VERSION ""

NS_ :

BS_:

BU_: AHLM ASBS CBC DIAGNOST DPDM DTCM ECM EHPS ESC ESL ESM ETM GPF HCP IC IRCM OCM ORC PTS RF_HUB SCCM SGW TBM TCM TPM

BO_ 1562 SD_RS_EPS: 8 EHPS
 SG_ SD_RS_EPS : 7|64@0+ (1,0) [0|0] ""  ETM,SGW,TBM

BO_ 1543 SD_RS_ESC: 8 ESC
 SG_ SD_RS_ESC : 7|64@0+ (1,0) [0|0] ""  ETM,SGW,TBM

BO_ 1544 SD_RS_ESL: 8 ESL
 SG_ SD_RS_ESL : 7|64@0+ (1,0) [0|0] ""  ETM,SGW,TBM

BO_ 1545 SD_RS_ESM: 8 ESM
 SG_ SD_RS_ESM : 7|64@0+ (1,0) [0|0] ""  ETM,SGW,TBM

BO_ 1586 SD_RS_GPF: 8 GPF
 SG_ SD_RS_GPF : 7|64@0+ (1,0) [0|0] ""  ETM,SGW,TBM

BO_ 1594 SD_RS_HCP: 8 HCP
 SG_ SD_RS_HCP : 7|64@0+ (1,0) [0|0] ""  ETM,SGW,TBM

BO_ 1538 SD_RS_IC: 8 IC
 SG_ SD_RS_IC : 7|64@0+ (1,0) [0|0] ""  ETM,SGW,TBM

BO_ 1566 SD_RS_OCM: 8 OCM
 SG_ SD_RS_OCM : 7|64@0+ (1,0) [0|0] ""  ETM,SGW,TBM

BO_ 1540 SD_RS_ORC: 8 ORC
 SG_ SD_RS_ORC : 7|64@0+ (1,0) [0|0] ""  ETM,SGW,TBM

BO_ 1570 SD_RS_PTS: 8 PTS
 SG_ SD_RS_PTS : 7|64@0+ (1,0) [0|0] ""  ETM,SGW,TBM

BO_ 1536 SD_RS_RF_HUB: 8 RF_HUB
 SG_ SD_RS_RF_HUB : 7|64@0+ (1,0) [0|0] ""  ETM,SGW,TBM

BO_ 1571 SD_RS_SCCM: 8 SCCM
 SG_ SD_RS_SCCM : 7|64@0+ (1,0) [0|0] ""  ETM,SGW,TBM

BO_ 1643 SD_RS_TBM: 8 SGW
 SG_ SD_RS_TBM : 7|64@0+ (1,0) [0|0] "" Vector__XXX

BO_ 1593 SD_RS_TCM: 8 TCM
 SG_ SD_RS_TCM : 7|64@0+ (1,0) [0|0] ""  ETM,SGW,TBM

BO_ 1539 SD_RS_TPM: 8 TPM
 SG_ SD_RS_TPM : 7|64@0+ (1,0) [0|0] ""  ETM,SGW,TBM

BO_ 423 STATUS_C_ESL: 2 ESL
 SG_ ESLSts : 12|3@1+ (1,0) [0|0] ""  SGW
 SG_ KeyOffWithHighSpeedSts : 15|1@1+ (1,0) [0|0] ""  CBC,SGW

BO_ 491 STATUS_C_PTS: 8 PTS
 SG_ PTS_DBD : 16|1@1+ (1,0) [0|0] ""  IC,SGW

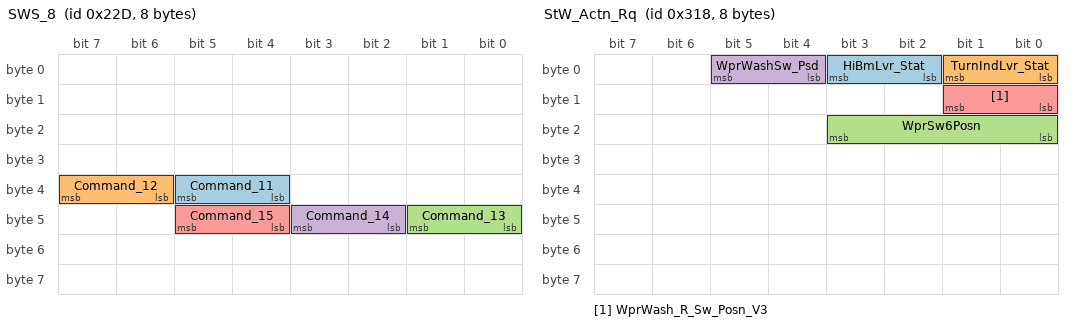
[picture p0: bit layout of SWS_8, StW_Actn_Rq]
BO_ 557 SWS_8: 8 CBC
 SG_ Command_11 : 36|2@1+ (1,0) [0|0] ""  ETM,IC,SGW,TBM
 SG_ Command_12 : 38|2@1+ (1,0) [0|0] ""  ETM,IC,SGW,TBM
 SG_ Command_13 : 40|2@1+ (1,0) [0|0] ""  ETM,IC,SGW,TBM
 SG_ Command_14 : 42|2@1+ (1,0) [0|0] ""  ETM,IC,SGW,TBM
 SG_ Command_15 : 44|2@1+ (1,0) [0|0] ""  ETM,IC,SGW,TBM

BO_ 792 StW_Actn_Rq: 8 SCCM
 SG_ HiBmLvr_Stat : 2|2@1+ (1,0) [0|0] ""  CBC,ETM,SGW,TBM
 SG_ TurnIndLvr_Stat : 0|2@1+ (1,0) [0|0] ""  CBC,IRCM,SGW
 SG_ WprSw6Posn : 16|4@1+ (1,0) [0|0] ""  CBC,ETM,IRCM,SGW,TBM
 SG_ WprWashSw_Psd : 4|2@1+ (1,0) [0|0] ""  CBC,ETM,SGW,TBM
 SG_ WprWash_R_Sw_Posn_V3 : 8|2@1+ (1,0) [0|0] ""  CBC,ECM,ETM,SGW,TBM

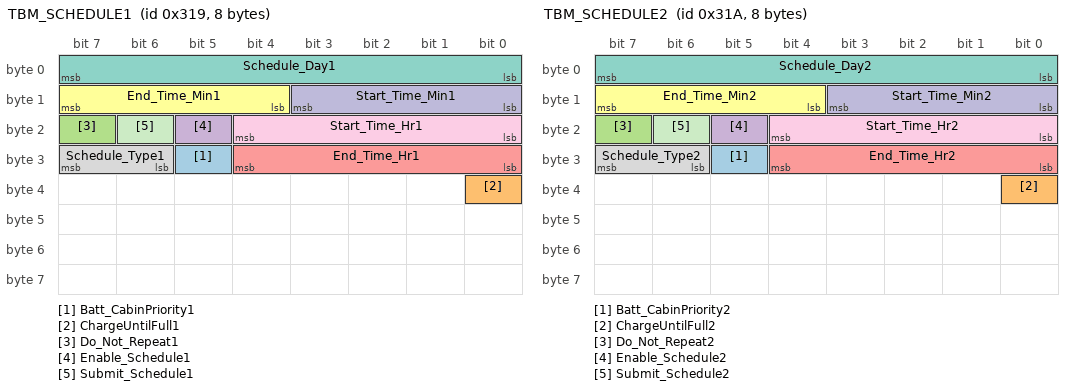
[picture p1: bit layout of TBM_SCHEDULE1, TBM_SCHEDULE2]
BO_ 793 TBM_SCHEDULE1: 8 CBC
 SG_ Batt_CabinPriority1 : 29|1@1+ (1,0) [0|0] ""  HCP,SGW
 SG_ ChargeUntilFull1 : 32|1@1+ (1,0) [0|0] ""  HCP,SGW
 SG_ Do_Not_Repeat1 : 23|1@1+ (1,0) [0|0] ""  HCP,SGW
 SG_ Enable_Schedule1 : 21|1@1+ (1,0) [0|0] ""  HCP,SGW
 SG_ End_Time_Hr1 : 24|5@1+ (1,0) [0|23] "Hours"  HCP,SGW
 SG_ End_Time_Min1 : 12|4@1+ (5,0) [0|55] "min"  HCP,SGW
 SG_ Schedule_Day1 : 0|8@1+ (1,0) [0|0] ""  HCP,SGW
 SG_ Schedule_Type1 : 30|2@1+ (1,0) [0|0] ""  HCP,SGW
 SG_ Start_Time_Hr1 : 16|5@1+ (1,0) [0|23] "Hours"  HCP,SGW
 SG_ Start_Time_Min1 : 8|4@1+ (5,0) [0|55] "min"  HCP,SGW
 SG_ Submit_Schedule1 : 22|1@1+ (1,0) [0|0] ""  HCP,SGW

BO_ 794 TBM_SCHEDULE2: 8 CBC
 SG_ Batt_CabinPriority2 : 29|1@1+ (1,0) [0|0] ""  HCP,SGW
 SG_ ChargeUntilFull2 : 32|1@1+ (1,0) [0|0] ""  HCP,SGW
 SG_ Do_Not_Repeat2 : 23|1@1+ (1,0) [0|0] ""  HCP,SGW
 SG_ Enable_Schedule2 : 21|1@1+ (1,0) [0|0] ""  HCP,SGW
 SG_ End_Time_Hr2 : 24|5@1+ (1,0) [0|23] "Hours"  HCP,SGW
 SG_ End_Time_Min2 : 12|4@1+ (5,0) [0|55] "min"  HCP,SGW
 SG_ Schedule_Day2 : 0|8@1+ (1,0) [0|0] ""  HCP,SGW
 SG_ Schedule_Type2 : 30|2@1+ (1,0) [0|0] ""  HCP,SGW
 SG_ Start_Time_Hr2 : 16|5@1+ (1,0) [0|23] "Hours"  HCP,SGW
 SG_ Start_Time_Min2 : 8|4@1+ (5,0) [0|55] "min"  HCP,SGW
 SG_ Submit_Schedule2 : 22|1@1+ (1,0) [0|0] ""  HCP,SGW

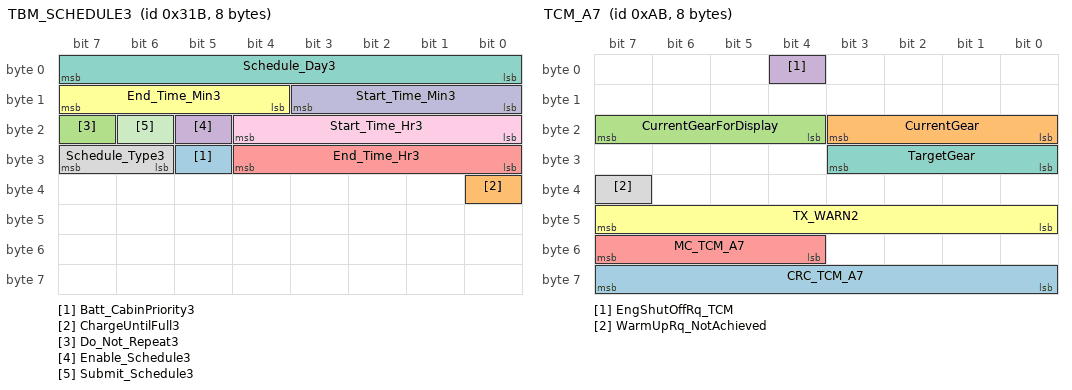
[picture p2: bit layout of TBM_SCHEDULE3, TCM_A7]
BO_ 795 TBM_SCHEDULE3: 8 CBC
 SG_ Batt_CabinPriority3 : 29|1@1+ (1,0) [0|0] ""  HCP,SGW
 SG_ ChargeUntilFull3 : 32|1@1+ (1,0) [0|0] ""  HCP,SGW
 SG_ Do_Not_Repeat3 : 23|1@1+ (1,0) [0|0] ""  HCP,SGW
 SG_ Enable_Schedule3 : 21|1@1+ (1,0) [0|0] ""  HCP,SGW
 SG_ End_Time_Hr3 : 24|5@1+ (1,0) [0|23] "Hours"  HCP,SGW
 SG_ End_Time_Min3 : 12|4@1+ (5,0) [0|55] "min"  HCP,SGW
 SG_ Schedule_Day3 : 0|8@1+ (1,0) [0|0] ""  HCP,SGW
 SG_ Schedule_Type3 : 30|2@1+ (1,0) [0|0] ""  HCP,SGW
 SG_ Start_Time_Hr3 : 16|5@1+ (1,0) [0|23] "Hours"  HCP,SGW
 SG_ Start_Time_Min3 : 8|4@1+ (5,0) [0|55] "min"  HCP,SGW
 SG_ Submit_Schedule3 : 22|1@1+ (1,0) [0|0] ""  HCP,SGW

BO_ 171 TCM_A7: 8 TCM
 SG_ CRC_TCM_A7 : 56|8@1+ (1,0) [0|0] ""  ECM,HCP,IRCM,SGW
 SG_ CurrentGear : 16|4@1+ (1,0) [0|0] ""  ECM,ETM,HCP,IRCM,SGW,TBM
 SG_ CurrentGearForDisplay : 20|4@1+ (1,0) [0|0] ""  ETM,IC,SGW
 SG_ EngShutOffRq_TCM : 4|1@1+ (1,0) [0|0] ""  ECM,SGW
 SG_ MC_TCM_A7 : 52|4@1+ (1,0) [0|15] ""  ECM,HCP,IRCM,SGW
 SG_ TX_WARN2 : 40|8@1+ (1,0) [0|0] ""  ETM,IC,SGW,TBM
 SG_ TargetGear : 24|4@1+ (1,0) [0|0] ""  ECM,HCP,IRCM,SGW
 SG_ WarmUpRq_NotAchieved : 39|1@1+ (1,0) [0|0] ""  ECM,SGW

BO_ 945 TCM_APPL1: 8 TCM
 SG_ TCM_APPL1 : 7|64@0+ (1,0) [0|0] ""  DIAGNOST,SGW

BO_ 944 TCM_APPL2: 8 DIAGNOST
 SG_ TCM_APPL2 : 7|64@0+ (1,0) [0|0] ""  TCM

BO_ 946 TCM_APPL3: 8 TCM
 SG_ TCM_APPL3 : 7|64@0+ (1,0) [0|0] ""  DIAGNOST,SGW

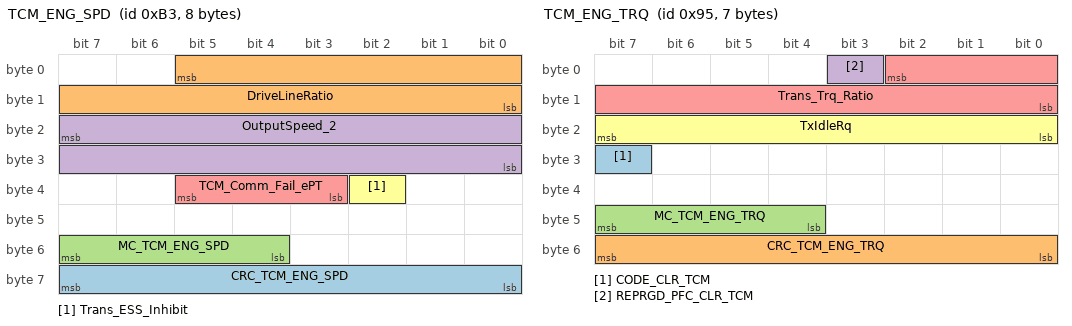
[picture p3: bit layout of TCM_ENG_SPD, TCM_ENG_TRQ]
BO_ 179 TCM_ENG_SPD: 8 TCM
 SG_ CRC_TCM_ENG_SPD : 56|8@1+ (1,0) [0|0] ""  ECM,ESC,HCP,IRCM,SGW
 SG_ DriveLineRatio : 5|14@0+ (0.01,0) [0|163.82] ""  ECM,HCP,IRCM,SGW
 SG_ MC_TCM_ENG_SPD : 52|4@1+ (1,0) [0|15] ""  ECM,ESC,HCP,IRCM,SGW
 SG_ OutputSpeed_2 : 23|16@0+ (1,0) [0|65534] "rpm"  ECM,HCP,SGW
 SG_ TCM_Comm_Fail_ePT : 35|3@1+ (1,0) [0|0] ""  ECM,HCP,SGW
 SG_ Trans_ESS_Inhibit : 34|1@1+ (1,0) [0|0] ""  ECM,SGW

BO_ 149 TCM_ENG_TRQ: 7 TCM
 SG_ CODE_CLR_TCM : 31|1@1+ (1,0) [0|0] ""  ECM,SGW
 SG_ CRC_TCM_ENG_TRQ : 48|8@1+ (1,0) [0|0] ""  DTCM,ECM,ESC,HCP,IRCM,SGW
 SG_ MC_TCM_ENG_TRQ : 44|4@1+ (1,0) [0|15] ""  DTCM,ECM,ESC,HCP,IRCM,SGW
 SG_ REPRGD_PFC_CLR_TCM : 3|1@1+ (1,0) [0|0] ""  ECM,SGW
 SG_ Trans_Trq_Ratio : 2|11@0+ (0.01,0) [0|20.46] ""  DTCM,ECM,ESC,ETM,HCP,IRCM,SGW,TBM
 SG_ TxIdleRq : 16|8@1+ (4,500) [500|1516] "rpm"  ECM,ESC,SGW

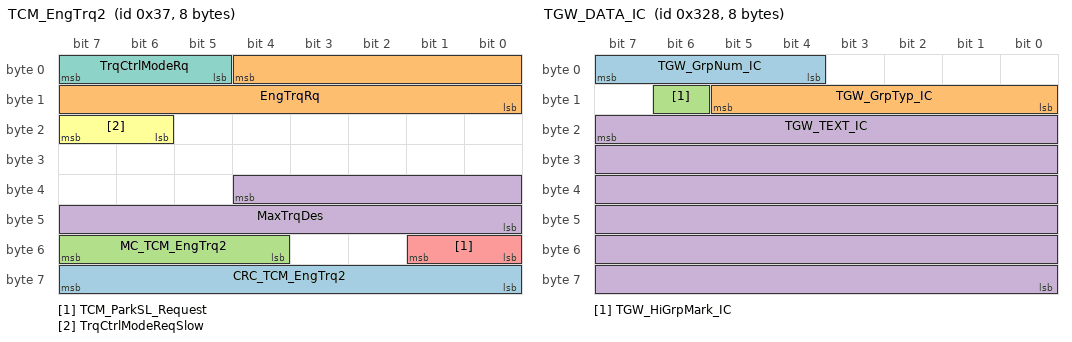
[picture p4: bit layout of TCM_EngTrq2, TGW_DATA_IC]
BO_ 55 TCM_EngTrq2: 8 TCM
 SG_ CRC_TCM_EngTrq2 : 56|8@1+ (1,0) [0|0] ""  ECM,ESC,HCP,IRCM,SGW
 SG_ EngTrqRq : 4|13@0+ (0.25,-500) [-500|1547.5] "Nm"  ECM,ESC,HCP,SGW
 SG_ MC_TCM_EngTrq2 : 52|4@1+ (1,0) [0|15] ""  ECM,ESC,HCP,IRCM,SGW
 SG_ MaxTrqDes : 36|13@0+ (0.25,-500) [-500|1547.5] "Nm"  ECM,HCP,SGW
 SG_ TCM_ParkSL_Request : 48|2@1+ (1,0) [0|0] ""  ECM,SGW
 SG_ TrqCtrlModeReqSlow : 22|2@1+ (1,0) [0|0] ""  HCP,SGW
 SG_ TrqCtrlModeRq : 5|3@1+ (1,0) [0|0] ""  ECM,ESC,HCP,SGW

BO_ 872 TCM_HSA: 8 TCM
 SG_ TCM_HSA : 7|64@0+ (1,0) [0|0] ""  DIAGNOST,SGW

BO_ 888 TCM_HSB: 8 TCM
 SG_ TCM_HSB : 7|64@0+ (1,0) [0|0] ""  DIAGNOST,SGW

BO_ 904 TCM_HSC: 8 TCM
 SG_ TCM_HSC : 7|64@0+ (1,0) [0|0] ""  DIAGNOST,SGW

BO_ 920 TCM_HSD: 8 TCM
 SG_ TCM_HSD : 7|64@0+ (1,0) [0|0] ""  DIAGNOST,SGW

BO_ 808 TGW_DATA_IC: 8 CBC
 SG_ TGW_GrpNum_IC : 4|4@1+ (1,1) [1|16] "Group"  IC,SGW
 SG_ TGW_GrpTyp_IC : 8|6@1+ (1,0) [1|40] "Text"  IC,SGW
 SG_ TGW_HiGrpMark_IC : 14|1@1+ (1,0) [0|0] ""  IC,SGW
 SG_ TGW_TEXT_IC : 23|48@0+ (1,0) [0|0] ""  IC,SGW

BO_ 662 TPM_A1: 8 TPM
 SG_ STFASysEnableFault : 23|1@1+ (1,0) [0|0] ""  CBC,SGW
 SG_ TFASts_TPM : 22|1@1+ (1,0) [0|0] ""  CBC,SGW
 SG_ TPM_Chime_Rq : 2|1@1+ (1,0) [0|0] ""  IC,SGW
 SG_ TPM_HazardFlash : 21|1@1+ (1,0) [0|0] ""  CBC,IC,SGW
 SG_ TPM_HornChirp : 19|2@1+ (1,0) [0|0] ""  SGW
 SG_ TPM_IndLmp_On_Rq : 0|2@1+ (1,0) [0|0] ""  ETM,IC,ORC,SGW,TBM
 SG_ TPM_Sys_Stat : 5|3@1+ (1,0) [0|0] ""  IC,SGW
 SG_ TireFL : 8|2@1+ (1,0) [0|0] ""  ETM,IC,ORC,SGW,TBM
 SG_ TireFR : 10|2@1+ (1,0) [0|0] ""  ETM,IC,ORC,SGW,TBM
 SG_ TirePressFL : 24|8@1+ (1,0) [0|126] "psi"  ETM,IC,ORC,SGW,TBM
 SG_ TirePressFR : 32|8@1+ (1,0) [0|126] "psi"  ETM,IC,ORC,SGW,TBM
 SG_ TirePressRL : 40|8@1+ (1,0) [0|126] "psi"  ETM,IC,ORC,SGW,TBM
 SG_ TirePressRR : 48|8@1+ (1,0) [0|126] "psi"  ETM,IC,ORC,SGW,TBM
 SG_ TirePressSpr : 56|8@1+ (1,0) [0|126] "psi"  ETM,IC,ORC,SGW,TBM
 SG_ TireRL : 14|2@1+ (1,0) [0|0] ""  ETM,IC,ORC,SGW,TBM
 SG_ TireRR : 12|2@1+ (1,0) [0|0] ""  ETM,IC,ORC,SGW,TBM
 SG_ TireSpr : 16|2@1+ (1,0) [0|0] ""  ETM,IC,ORC,SGW,TBM

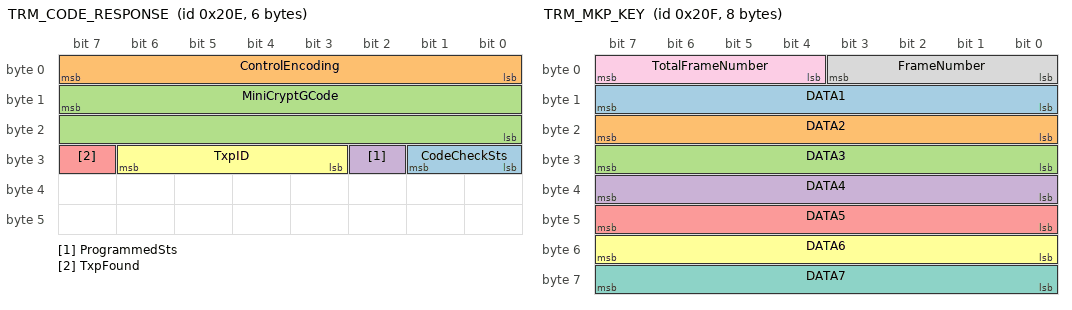
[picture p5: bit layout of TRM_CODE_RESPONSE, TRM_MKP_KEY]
BO_ 526 TRM_CODE_RESPONSE: 6 RF_HUB
 SG_ CodeCheckSts : 24|2@1+ (1,0) [0|0] ""  CBC,SGW
 SG_ ControlEncoding : 0|8@1+ (1,0) [0|0] ""  CBC,SGW
 SG_ MiniCryptGCode : 15|16@0+ (1,0) [0|0] ""  CBC,SGW
 SG_ ProgrammedSts : 26|1@1+ (1,0) [0|0] ""  CBC,SGW
 SG_ TxpFound : 31|1@1+ (1,0) [0|0] ""  CBC,SGW
 SG_ TxpID : 27|4@1+ (1,0) [0|0] ""  CBC,SGW

BO_ 527 TRM_MKP_KEY: 8 RF_HUB
 SG_ DATA1 : 8|8@1+ (1,0) [0|0] ""  CBC,SGW
 SG_ DATA2 : 16|8@1+ (1,0) [0|0] ""  CBC,SGW
 SG_ DATA3 : 24|8@1+ (1,0) [0|0] ""  CBC,SGW
 SG_ DATA4 : 32|8@1+ (1,0) [0|0] ""  CBC,SGW
 SG_ DATA5 : 40|8@1+ (1,0) [0|0] ""  CBC,SGW
 SG_ DATA6 : 48|8@1+ (1,0) [0|0] ""  CBC,SGW
 SG_ DATA7 : 56|8@1+ (1,0) [0|0] ""  CBC,SGW
 SG_ FrameNumber : 0|4@1+ (1,0) [0|0] ""  CBC,SGW
 SG_ TotalFrameNumber : 4|4@1+ (1,0) [0|0] ""  CBC,SGW

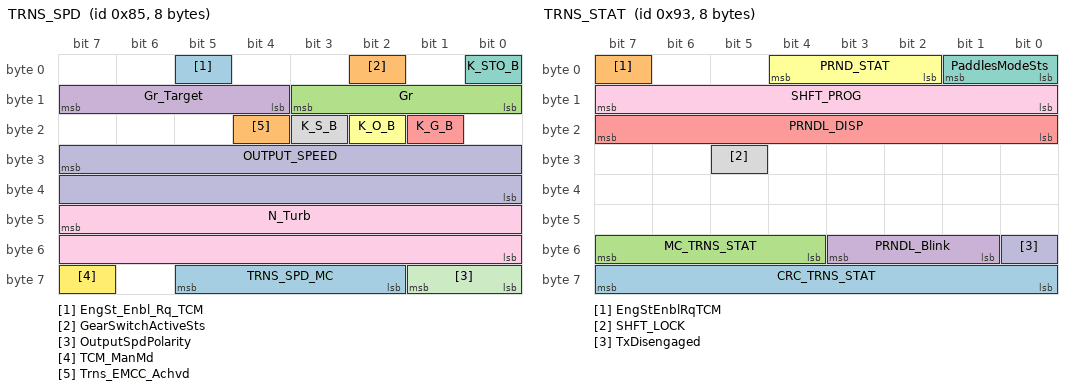
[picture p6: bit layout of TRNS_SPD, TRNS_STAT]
BO_ 133 TRNS_SPD: 8 TCM
 SG_ EngSt_Enbl_Rq_TCM : 5|1@1+ (1,0) [0|0] ""  ETM,RF_HUB,SGW,TBM
 SG_ GearSwitchActiveSts : 2|1@1+ (1,0) [0|0] ""  ECM,ESC,ETM,HCP,SGW,TBM
 SG_ Gr : 8|4@1+ (1,0) [0|0] ""  CBC,DTCM,ECM,ESC,ETM,HCP,IC,ORC,RF_HUB,SGW,TBM,TPM
 SG_ Gr_Target : 12|4@1+ (1,0) [0|0] ""  CBC,DTCM,ECM,ESC,HCP,SGW
 SG_ K_G_B : 17|1@1+ (1,0) [0|0] ""  ECM,ESC,ETM,HCP,SGW,TBM
 SG_ K_O_B : 18|1@1+ (1,0) [0|0] ""  ECM,ESC,ETM,HCP,SGW,TBM
 SG_ K_STO_B : 0|1@1+ (1,0) [0|0] ""  ECM,ETM,HCP,SGW,TBM
 SG_ K_S_B : 19|1@1+ (1,0) [0|0] ""  ECM,ESC,ETM,HCP,SGW,TBM
 SG_ N_Turb : 47|16@0+ (1,0) [0|65534] "rpm"  ECM,ETM,HCP,SGW,TBM
 SG_ OUTPUT_SPEED : 31|16@0+ (1,0) [0|65534] "rpm"  DTCM,ECM,ESC,ETM,HCP,SGW,TBM
 SG_ OutputSpdPolarity : 56|2@1+ (1,0) [0|0] ""  ESC,ETM,HCP,SGW,TBM
 SG_ TCM_ManMd : 63|1@1+ (1,0) [0|0] ""  DTCM,ECM,ETM,HCP,IC,SGW
 SG_ TRNS_SPD_MC : 58|4@1+ (1,0) [0|15] ""  ECM,ESC,ETM,HCP,SGW,TBM
 SG_ Trns_EMCC_Achvd : 20|1@1+ (1,0) [0|0] ""  ECM,ETM,SGW,TBM

BO_ 147 TRNS_STAT: 8 TCM
 SG_ CRC_TRNS_STAT : 56|8@1+ (1,0) [0|0] ""  DTCM,ECM,ESC,ESM,HCP,IRCM,PTS,SGW
 SG_ EngStEnblRqTCM : 7|1@1+ (1,0) [0|0] ""  ECM,RF_HUB,SGW
 SG_ MC_TRNS_STAT : 52|4@1+ (1,0) [0|15] ""  DTCM,ECM,ESC,ESM,HCP,IRCM,PTS,SGW
 SG_ PRNDL_Blink : 49|3@1+ (1,0) [0|0] ""  ESM,IC,SGW
 SG_ PRNDL_DISP : 16|8@1+ (1,0) [0|0] ""  CBC,DTCM,ECM,ESC,ESM,HCP,IC,IRCM,ORC,SGW
 SG_ PRND_STAT : 2|3@1+ (1,0) [0|0] ""  CBC,ECM,ESC,ESM,HCP,IC,IRCM,ORC,PTS,SGW
 SG_ PaddlesModeSts : 0|2@1+ (1,0) [0|0] ""  SGW
 SG_ SHFT_LOCK : 29|1@1+ (1,0) [0|0] ""  ESM,SGW
 SG_ SHFT_PROG : 8|8@1+ (1,0) [0|0] ""  CBC,DTCM,ECM,ESC,HCP,IC,SGW
 SG_ TxDisengaged : 48|1@1+ (1,0) [0|0] ""  ECM,HCP,SGW

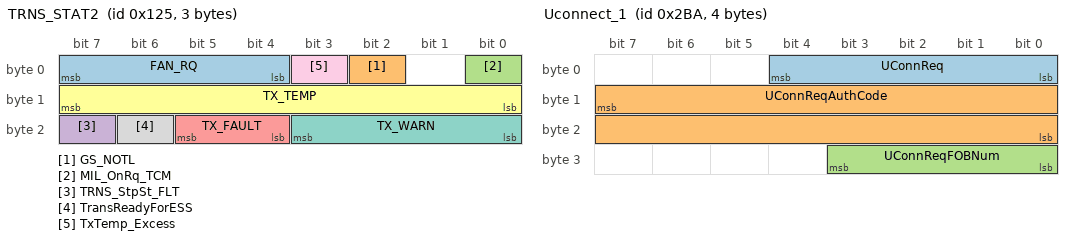
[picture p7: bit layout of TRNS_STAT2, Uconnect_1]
BO_ 293 TRNS_STAT2: 3 TCM
 SG_ FAN_RQ : 4|4@1+ (7.2,0) [0|100] "%"  ECM,SGW
 SG_ GS_NOTL : 2|1@1+ (1,0) [0|0] ""  ECM,HCP,IRCM,ORC,SGW
 SG_ MIL_OnRq_TCM : 0|1@1+ (1,0) [0|0] ""  ECM,ETM,SGW,TBM
 SG_ TRNS_StpSt_FLT : 23|1@1+ (1,0) [0|0] ""  ECM,SGW
 SG_ TX_FAULT : 20|2@1+ (1,0) [0|0] ""  ECM,ESM,ETM,RF_HUB,SGW,TBM
 SG_ TX_TEMP : 8|8@1+ (1,-50) [-50|204] "°C"  CBC,DTCM,ECM,ETM,HCP,IC,SGW,TBM
 SG_ TX_WARN : 16|4@1+ (1,0) [0|0] ""  IC,SGW
 SG_ TransReadyForESS : 22|1@1+ (1,0) [0|0] ""  ECM,ORC,SGW
 SG_ TxTemp_Excess : 3|1@1+ (1,0) [0|0] ""  ETM,IC,SGW,TBM

BO_ 698 Uconnect_1: 4 ETM
 SG_ UConnReq : 0|5@1+ (1,0) [0|0] ""  RF_HUB
 SG_ UConnReqAuthCode : 15|16@0+ (1,0) [0|0] ""  RF_HUB
 SG_ UConnReqFOBNum : 24|4@1+ (1,0) [0|0] ""  RF_HUB

BO_ 992 VIN: 8 ECM
 SG_ VIN_DATA : 15|56@0+ (1,0) [0|0] ""  AHLM,ASBS,CBC,DPDM,DTCM,EHPS,ESC,ESL,ESM,ETM,GPF,HCP,IC,IRCM,OCM,ORC,PTS,RF_HUB,SCCM,SGW,TBM,TCM,TPM
 SG_ VIN_MSG : 0|2@1+ (1,0) [0|0] ""  AHLM,ASBS,CBC,DPDM,DTCM,EHPS,ESC,ESL,ESM,ETM,GPF,HCP,IC,IRCM,OCM,ORC,PTS,RF_HUB,SCCM,SGW,TBM,TCM,TPM

BO_ 1000 VehCfg1: 8 CBC
 SG_ VC_AUTO_HB : 27|1@1+ (1,0) [0|0] ""  IC,IRCM,RF_HUB,SGW
 SG_ VC_BODY_STYLE : 28|4@1+ (1,0) [0|0] ""  AHLM,ASBS,DPDM,DTCM,ECM,EHPS,ESC,ESL,ESM,GPF,HCP,IC,IRCM,OCM,ORC,PTS,RF_HUB,SCCM,SGW,TCM,TPM
 SG_ VC_CHMCM_Prsnt : 61|1@1+ (1,0) [0|0] ""  RF_HUB,SGW
 SG_ VC_COUNTRY : 16|5@1+ (1,0) [0|0] ""  AHLM,ASBS,DPDM,DTCM,ECM,EHPS,ESC,ESL,ESM,ETM,GPF,HCP,IC,IRCM,OCM,ORC,PTS,RF_HUB,SCCM,SGW,TBM,TCM,TPM
 SG_ VC_EmodePrsnt : 26|1@1+ (1,0) [0|0] ""  RF_HUB,SGW
 SG_ VC_HDC_Prsnt : 62|1@1+ (1,0) [0|0] ""  ECM,ESC,IC,IRCM,RF_HUB,SGW,TCM
 SG_ VC_HdRstPrsnt : 56|1@1+ (1,0) [0|0] ""  RF_HUB,SGW
 SG_ VC_LHD_RHD : 21|2@1+ (1,0) [0|0] ""  DTCM,ESC,ETM,IC,IRCM,RF_HUB,SGW,TBM
 SG_ VC_MAX_VEH_SPD : 32|8@1+ (2,0) [0|506] "kph"  RF_HUB,SGW
 SG_ VC_MODEL_YEAR : 2|6@1+ (1,2000) [2000|2062] "model-year"  AHLM,ASBS,DPDM,DTCM,ECM,EHPS,ESC,ESL,ESM,ETM,GPF,HCP,IC,IRCM,OCM,ORC,PTS,RF_HUB,SCCM,SGW,TBM,TCM,TPM
 SG_ VC_PP_Prsnt : 47|1@1+ (1,0) [0|0] ""  RF_HUB,SGW
 SG_ VC_PTS_Config : 58|2@1+ (1,0) [0|0] ""  IC,RF_HUB,SGW
 SG_ VC_PTS_DispTyp : 44|3@1+ (1,0) [0|0] ""  RF_HUB,SGW
 SG_ VC_RVCM_Prsnt : 60|1@1+ (1,0) [0|0] ""  RF_HUB,SGW
 SG_ VC_RemStPrsnt : 23|1@1+ (1,0) [0|0] ""  IC,ORC,RF_HUB,SGW,TCM,TPM
 SG_ VC_SCR_Prsnt : 57|1@1+ (1,0) [0|0] ""  ECM,IC,RF_HUB,SGW
 SG_ VC_SSC_Prsnt : 63|1@1+ (1,0) [0|0] ""  DTCM,ECM,ESC,IC,RF_HUB,SGW,TCM
 SG_ VC_ShftrTyp : 40|4@1+ (1,0) [0|0] ""  IC,RF_HUB,SGW,TCM
 SG_ VC_SpecialPKG : 48|8@1+ (1,0) [1|254] ""  RF_HUB,SGW
 SG_ VC_VEH_LINE : 8|8@1+ (1,0) [0|0] ""  AHLM,ASBS,DPDM,DTCM,ECM,EHPS,ESC,ESL,ESM,ETM,GPF,HCP,IC,IRCM,OCM,ORC,PTS,RF_HUB,SCCM,SGW,TBM,TCM,TPM
 SG_ VC_VehCfg1_Stat : 0|2@1+ (1,0) [0|0] ""  AHLM,ASBS,DPDM,DTCM,ECM,EHPS,ESC,ESL,ESM,GPF,HCP,IC,IRCM,OCM,ORC,PTS,RF_HUB,SCCM,SGW,TCM,TPM
 SG_ VC_XWD : 24|2@1+ (1,0) [0|0] ""  DTCM,ECM,EHPS,ESC,HCP,IRCM,RF_HUB,SGW,TCM

BO_ 1001 VehCfg2: 8 CBC
 SG_ VC_AC_Prsnt : 11|1@1+ (1,0) [0|0] ""  RF_HUB,SGW
 SG_ VC_CRUISE_PRSNT : 12|1@1+ (1,0) [0|0] ""  ECM,IC,IRCM,ORC,RF_HUB,SCCM,SGW,TCM
 SG_ VC_DRVMD_Prsnt : 25|1@1+ (1,0) [0|0] ""  RF_HUB,SGW
 SG_ VC_ECO_Indicator : 24|1@1+ (1,0) [0|0] ""  RF_HUB,SGW
 SG_ VC_ESCDrvMd_Prsnt : 27|1@1+ (1,0) [0|0] ""  RF_HUB,SGW
 SG_ VC_EngPowerDrvMd_Prsnt : 28|1@1+ (1,0) [0|0] ""  RF_HUB,SGW
 SG_ VC_FG_PRSNT : 13|1@1+ (1,0) [0|0] ""  RF_HUB,SGW
 SG_ VC_FULL_SPARE : 14|1@1+ (1,0) [0|0] ""  RF_HUB,SGW,TPM
 SG_ VC_LgtLdPressFtTr : 56|8@1+ (1,0) [0|126] "psi"  RF_HUB,SGW
 SG_ VC_LgtLdPressRrTr : 48|8@1+ (1,0) [0|126] "psi"  RF_HUB,SGW
 SG_ VC_MaseratiMd : 6|2@1+ (1,0) [0|0] ""  RF_HUB,SGW
 SG_ VC_MaxLdPressFtTr : 40|8@1+ (1,0) [0|126] "psi"  IC,RF_HUB,SGW,TPM
 SG_ VC_MaxLdPressRrTr : 32|8@1+ (1,0) [0|126] "psi"  IC,RF_HUB,SGW,TPM
 SG_ VC_MemoryDRVMD_Prsnt : 26|1@1+ (1,0) [0|0] ""  RF_HUB,SGW
 SG_ VC_OffRoad : 15|1@1+ (1,0) [0|0] ""  RF_HUB,SGW
 SG_ VC_PADS_Prsnt : 8|1@1+ (1,0) [0|0] ""  IC,ORC,RF_HUB,SGW
 SG_ VC_PwrIvtrTyp : 2|2@1+ (1,0) [0|0] ""  RF_HUB,SGW
 SG_ VC_RainSnsPrsnt : 9|1@1+ (1,0) [0|0] ""  RF_HUB,SGW
 SG_ VC_RunFlatTirePrsnt : 5|1@1+ (1,0) [0|0] ""  RF_HUB,SGW
 SG_ VC_SKIM_PRSNT : 10|1@1+ (1,0) [0|0] ""  RF_HUB,SGW
 SG_ VC_SecPrkPrsnt : 29|1@1+ (1,0) [0|0] ""  RF_HUB,SGW
 SG_ VC_ShftInd_Prsnt : 30|2@1+ (1,0) [0|0] ""  ECM,HCP,IC,RF_HUB,SGW
 SG_ VC_SpecialPKG_IC : 16|8@1+ (1,0) [0|0] ""  IC,IRCM,RF_HUB,SGW
 SG_ VC_ThatchamPrsnt : 4|1@1+ (1,0) [0|0] ""  RF_HUB,SGW
 SG_ VC_VehCfg2_Stat : 0|2@1+ (1,0) [0|0] ""  ECM,ESC,ESM,HCP,IC,IRCM,ORC,RF_HUB,SCCM,SGW,TCM,TPM

BO_TX_BU_ 1643 : SGW,TBM;
BO_TX_BU_ 171 : TCM,ECM;
BO_TX_BU_ 944 : DIAGNOST,SGW;
BO_TX_BU_ 147 : TCM,ECM;
BO_TX_BU_ 698 : ETM,SGW,TBM;
CM_ SG_ 1562 SD_RS_EPS "Response on Event - light";
CM_ SG_ 1543 SD_RS_ESC "Response on Event - light";
CM_ SG_ 1544 SD_RS_ESL "Response on Event - light";
CM_ SG_ 1545 SD_RS_ESM "Response on Event - light";
CM_ SG_ 1586 SD_RS_GPF "Response on Event - light";
CM_ SG_ 1594 SD_RS_HCP "Response on Event - light";
CM_ SG_ 1538 SD_RS_IC "Response on Event - light";
CM_ SG_ 1566 SD_RS_OCM "Response on Event - light";
CM_ SG_ 1540 SD_RS_ORC "Response on Event - light";
CM_ SG_ 1570 SD_RS_PTS "Response on Event - light";
CM_ SG_ 1536 SD_RS_RF_HUB "Response on Event - light";
CM_ SG_ 1571 SD_RS_SCCM "Response on Event - light";
CM_ SG_ 1643 SD_RS_TBM "Response on Event - light";
CM_ SG_ 1593 SD_RS_TCM "Response on Event - light";
CM_ SG_ 1539 SD_RS_TPM "Response on Event - light";
CM_ SG_ 423 ESLSts "ESL lock / unlock status";
CM_ SG_ 423 KeyOffWithHighSpeedSts "Indicates vehicle speed inhibiting lock; Active = [1]";
CM_ SG_ 491 PTS_DBD "Park assist system disabled; System_Disabled = [1]";
CM_ SG_ 557 Command_11 "Steering wheel switch 11";
CM_ SG_ 557 Command_12 "Steering wheel switch 12";
CM_ SG_ 557 Command_13 "Steering wheel switch 13";
CM_ SG_ 557 Command_14 "Steering wheel switch 14";
CM_ SG_ 557 Command_15 "Steering wheel switch 15";
CM_ SG_ 792 HiBmLvr_Stat "High beam lever state";
CM_ SG_ 792 TurnIndLvr_Stat "Turn indicator lever state";
CM_ SG_ 792 WprSw6Posn "Wiper switch (6 stages) position";
CM_ SG_ 792 WprWashSw_Psd "Front wiper switch pressed";
CM_ SG_ 792 WprWash_R_Sw_Posn_V3 "Backlite wiper/washer switch position";
CM_ SG_ 793 Batt_CabinPriority1 "Bit to prioritize battery charging or cabin conditioning under schedule 1";
CM_ SG_ 793 ChargeUntilFull1 "Charge until battery is fully charged with schedule 1";
CM_ SG_ 793 Do_Not_Repeat1 "Do not repeat the set Schedule";
CM_ SG_ 793 Enable_Schedule1 "Schedule 1 checkbox enabled";
CM_ SG_ 793 End_Time_Hr1 "End Time of schedule 1 (hours in 24 hrs. format)";
CM_ SG_ 793 End_Time_Min1 "End Time of schedule 1 (Minutes)";
CM_ SG_ 793 Schedule_Day1 "Schedule#1 Day for charging or cabin conditioning";
CM_ SG_ 793 Schedule_Type1 "Type of charging and climate schedule";
CM_ SG_ 793 Start_Time_Hr1 "Start Time of schedule 1 (hours in 24 hrs. format)";
CM_ SG_ 793 Start_Time_Min1 "Start Time of schedule 1 (minutes)";
CM_ SG_ 793 Submit_Schedule1 "Schedule 1 submitted";
CM_ SG_ 794 Batt_CabinPriority2 "Bit to prioritize battery charging or cabin conditioning under schedule 2";
CM_ SG_ 794 ChargeUntilFull2 "Charge until battery is fully charged with schedule 2";
CM_ SG_ 794 Do_Not_Repeat2 "Do not repeat the set Schedule";
CM_ SG_ 794 Enable_Schedule2 "Schedule 2 checkbox enabled";
CM_ SG_ 794 End_Time_Hr2 "End Time of schedule 2 (hours in 24 hrs. format)";
CM_ SG_ 794 End_Time_Min2 "End Time of schedule 2 (Minutes)";
CM_ SG_ 794 Schedule_Day2 "Schedule#2 Day for charging or cabin conditioning";
CM_ SG_ 794 Schedule_Type2 "Type of charging and climate schedule";
CM_ SG_ 794 Start_Time_Hr2 "Start Time of schedule 2 (hours in 24 hrs. format)";
CM_ SG_ 794 Start_Time_Min2 "Start Time of schedule 2 (minutes)";
CM_ SG_ 794 Submit_Schedule2 "Schedule 2 submitted";
CM_ SG_ 795 Batt_CabinPriority3 "Bit to prioritize battery charging or cabin conditioning under schedule 3";
CM_ SG_ 795 ChargeUntilFull3 "Charge until battery is fully charged with schedule 3";
CM_ SG_ 795 Do_Not_Repeat3 "Do not repeat the set Schedule";
CM_ SG_ 795 Enable_Schedule3 "Schedule 3 checkbox enabled";
CM_ SG_ 795 End_Time_Hr3 "End Time of schedule 3 (hours in 24 hrs. format)";
CM_ SG_ 795 End_Time_Min3 "End Time of schedule 3 (Minutes)";
CM_ SG_ 795 Schedule_Day3 "Schedule#3 Day for charging or cabin conditioning";
CM_ SG_ 795 Schedule_Type3 "Type of charging and climate schedule";
CM_ SG_ 795 Start_Time_Hr3 "Start Time of schedule 3 (hours in 24 hrs. format)";
CM_ SG_ 795 Start_Time_Min3 "Start Time of schedule 3 (minutes)";
CM_ SG_ 795 Submit_Schedule3 "Schedule 3 submitted";
CM_ SG_ 171 CRC_TCM_A7 "CRC-checksum byte 1 to 7 according to SAE J1850";
CM_ SG_ 171 CurrentGear "Current Gear";
CM_ SG_ 171 CurrentGearForDisplay "Current Gear for display";
CM_ SG_ 171 EngShutOffRq_TCM "TCM request engine shut off";
CM_ SG_ 171 MC_TCM_A7 "Message counter";
CM_ SG_ 171 TX_WARN2 "Transmission warning #2";
CM_ SG_ 171 TargetGear "Target Gear - protected";
CM_ SG_ 171 WarmUpRq_NotAchieved "Warm Up Request; 0- Achieved, 1- NOT_Achieved";
CM_ SG_ 945 TCM_APPL1 "CCP from transmission";
CM_ SG_ 944 TCM_APPL2 "CCP to transmission";
CM_ SG_ 946 TCM_APPL3 "CCP from transmission";
CM_ SG_ 179 CRC_TCM_ENG_SPD "CRC-checksum byte 1 to 7 according to SAE J1850";
CM_ SG_ 179 DriveLineRatio "Drive Line Ratio";
CM_ SG_ 179 MC_TCM_ENG_SPD "Message counter   TCM_ENG_SPD";
CM_ SG_ 179 OutputSpeed_2 "Output Shaft Speed from 0 - 65534 RPM with 1 RPM resolution.  ";
CM_ SG_ 179 TCM_Comm_Fail_ePT "TCM_Comm_Fail_ePT";
CM_ SG_ 179 Trans_ESS_Inhibit "Trans_ESS_Inhibit";
CM_ SG_ 149 CODE_CLR_TCM "Clear emission related faults; 0= not clear, 1= Clear";
CM_ SG_ 149 CRC_TCM_ENG_TRQ "CRC-checksum byte 1 to 6 according to SAE J1850";
CM_ SG_ 149 MC_TCM_ENG_TRQ "Message counter";
CM_ SG_ 149 REPRGD_PFC_CLR_TCM "Set readiness to 'incomplete'; 0 = Do nothing; 1= Set incomplete";
CM_ SG_ 149 Trans_Trq_Ratio "Transmission torque ratio";
CM_ SG_ 149 TxIdleRq "Transmission idle speed request";
CM_ SG_ 55 CRC_TCM_EngTrq2 "CRC-checksum byte 1 to 7 according to SAE J1850";
CM_ SG_ 55 EngTrqRq "Requested engine torque";
CM_ SG_ 55 MC_TCM_EngTrq2 "Message counter";
CM_ SG_ 55 MaxTrqDes "Maximum engine torque desired";
CM_ SG_ 55 TCM_ParkSL_Request "TCM requested park pawl solenoid status";
CM_ SG_ 55 TrqCtrlModeReqSlow "Slow path torque control mode request";
CM_ SG_ 55 TrqCtrlModeRq "Torque control mode request";
CM_ SG_ 872 TCM_HSA "Manual control at test bench";
CM_ SG_ 888 TCM_HSB "Manual control at test bench";
CM_ SG_ 904 TCM_HSC "Manual control at test bench";
CM_ SG_ 920 TCM_HSD "Manual control at test bench";
CM_ SG_ 808 TGW_GrpNum_IC "TGW group number to IC";
CM_ SG_ 808 TGW_GrpTyp_IC "Group type to send text data from TGW to IC";
CM_ SG_ 808 TGW_HiGrpMark_IC "TGW high group mark to IC; [0] = Not True, [1] = True";
CM_ SG_ 808 TGW_TEXT_IC "TGW text string information to IC";
CM_ SG_ 662 STFASysEnableFault "STFA system enable fault; Absent = [0], Present = [1]";
CM_ SG_ 662 TFASts_TPM "Tire fill alert status; Disabled = [0], Enabled = [1]";
CM_ SG_ 662 TPM_Chime_Rq "TPM chime request";
CM_ SG_ 662 TPM_HazardFlash "TPM hazard flash;  true = [1]";
CM_ SG_ 662 TPM_HornChirp "TPM horn chirp";
CM_ SG_ 662 TPM_IndLmp_On_Rq "Tire pressure indication request";
CM_ SG_ 662 TPM_Sys_Stat "TPM system localization status";
CM_ SG_ 662 TireFL "Tire front left";
CM_ SG_ 662 TireFR "Tire front right";
CM_ SG_ 662 TirePressFL "Tire pressure front left";
CM_ SG_ 662 TirePressFR "Tire pressure front right";
CM_ SG_ 662 TirePressRL "Tire pressure rear left";
CM_ SG_ 662 TirePressRR "Tire pressure rear right";
CM_ SG_ 662 TirePressSpr "Tire pressure spare tire";
CM_ SG_ 662 TireRL "Tire rear left";
CM_ SG_ 662 TireRR "Tire rear right";
CM_ SG_ 662 TireSpr "Spare tire";
CM_ SG_ 526 CodeCheckSts "Code check status";
CM_ SG_ 526 ControlEncoding "Response type UC/TEN/PVA";
CM_ SG_ 526 MiniCryptGCode "MiniCrypt 'G' code output";
CM_ SG_ 526 ProgrammedSts "TRM programmed status; Programmed = [1]";
CM_ SG_ 526 TxpFound "Transponder found; Absent = [1]";
CM_ SG_ 526 TxpID "Transponder authentication";
CM_ SG_ 527 DATA1 "MiniCrypt key data byte 1";
CM_ SG_ 527 DATA2 "MiniCrypt key data byte 2";
CM_ SG_ 527 DATA3 "MiniCrypt key data byte 3";
CM_ SG_ 527 DATA4 "MiniCrypt key data byte 4";
CM_ SG_ 527 DATA5 "MiniCrypt key data byte 5";
CM_ SG_ 527 DATA6 "MiniCrypt key data byte 6";
CM_ SG_ 527 DATA7 "MiniCrypt key data byte 7";
CM_ SG_ 527 FrameNumber "MiniCrypt key frame number";
CM_ SG_ 527 TotalFrameNumber "MiniCrypt key total number of frames";
CM_ SG_ 133 EngSt_Enbl_Rq_TCM "Enable engine start request";
CM_ SG_ 133 GearSwitchActiveSts "Transmission shift in progress";
CM_ SG_ 133 Gr "Current Gear";
CM_ SG_ 133 Gr_Target "Target Gear";
CM_ SG_ 133 K_G_B "Conf. (torque converter lock-up) clutch 'closed'";
CM_ SG_ 133 K_O_B "Conf. (torque converter lock-up) clutch 'open'";
CM_ SG_ 133 K_STO_B "Conf. (torque converter lock-up) clutch 'starts to open'";
CM_ SG_ 133 K_S_B "Conf. (torque converter lock-up) clutch 'slip'";
CM_ SG_ 133 N_Turb "Unfiltered turbine speed (n_t_v)";
CM_ SG_ 133 OUTPUT_SPEED "Output Shaft Speed";
CM_ SG_ 133 OutputSpdPolarity "Output shaft speed polarity";
CM_ SG_ 133 TCM_ManMd "Transmission in manual mode";
CM_ SG_ 133 TRNS_SPD_MC "TRNS_SPD message counter";
CM_ SG_ 133 Trns_EMCC_Achvd "Trans A/C Converter Clutch Slipping; [1] = True";
CM_ SG_ 147 CRC_TRNS_STAT "CRC-checksum byte 1 to 7 according to SAE J1850";
CM_ SG_ 147 EngStEnblRqTCM "Engine start enable request from the transmission";
CM_ SG_ 147 MC_TRNS_STAT "Message counter";
CM_ SG_ 147 PRNDL_Blink "Request gear shift display indicator blink";
CM_ SG_ 147 PRNDL_DISP "PRNDL display request";
CM_ SG_ 147 PRND_STAT "PRND Status";
CM_ SG_ 147 PaddlesModeSts "Status of paddle functionality";
CM_ SG_ 147 SHFT_LOCK "Shiftlock state locked; false = [1]";
CM_ SG_ 147 SHFT_PROG "Driving program display code";
CM_ SG_ 147 TxDisengaged "Transmission disengaged";
CM_ SG_ 293 FAN_RQ "Cooling fan request";
CM_ SG_ 293 GS_NOTL "TRANS in limp home mode";
CM_ SG_ 293 MIL_OnRq_TCM "MIL on request from the transmission";
CM_ SG_ 293 TRNS_StpSt_FLT "Trans stop start fault (1=fault)";
CM_ SG_ 293 TX_FAULT "Transmission fault";
CM_ SG_ 293 TX_TEMP "Transmission fluid temperature";
CM_ SG_ 293 TX_WARN "Transmission warning";
CM_ SG_ 293 TransReadyForESS "Trans ready for auto stop (0= not ready)";
CM_ SG_ 293 TxTemp_Excess "Excessive transmission temperature";
CM_ SG_ 698 UConnReq "Basic Uconnect request";
CM_ SG_ 698 UConnReqAuthCode "Authorization for requests";
CM_ SG_ 698 UConnReqFOBNum "FOB number making the request";
CM_ SG_ 992 VIN_DATA "VIN Digits (8 bit ascii encoded) - see Signal Description Doc for details";
CM_ SG_ 992 VIN_MSG "VIN Message Information";
CM_ SG_ 1000 VC_AUTO_HB "Auto Highbeam feature present; present = [1]";
CM_ SG_ 1000 VC_BODY_STYLE "Body style";
CM_ SG_ 1000 VC_CHMCM_Prsnt "CHMSL camera (1=present)";
CM_ SG_ 1000 VC_COUNTRY "Country Code";
CM_ SG_ 1000 VC_EmodePrsnt "E-Mode feature present; True = [1]";
CM_ SG_ 1000 VC_HDC_Prsnt "Hill descent feature is present; present = [1]";
CM_ SG_ 1000 VC_HdRstPrsnt "Headrest present; present = [1]";
CM_ SG_ 1000 VC_LHD_RHD "Left/right hand drive";
CM_ SG_ 1000 VC_MAX_VEH_SPD "Maximum vehicle speed";
CM_ SG_ 1000 VC_MODEL_YEAR "Model year";
CM_ SG_ 1000 VC_PP_Prsnt "Performance Pages Present (1=present)";
CM_ SG_ 1000 VC_PTS_Config "Parktronics system configuration";
CM_ SG_ 1000 VC_PTS_DispTyp "PTS display type and location";
CM_ SG_ 1000 VC_RVCM_Prsnt "Rear view camera (1=present)";
CM_ SG_ 1000 VC_RemStPrsnt "Remote start present; present = [1]";
CM_ SG_ 1000 VC_SCR_Prsnt "Urea/SCR system present; present = [1]";
CM_ SG_ 1000 VC_SSC_Prsnt "Select speed control feature is present; present = [1]";
CM_ SG_ 1000 VC_ShftrTyp "Shifter type";
CM_ SG_ 1000 VC_SpecialPKG "Special sales code package";
CM_ SG_ 1000 VC_VEH_LINE "Vehicle line";
CM_ SG_ 1000 VC_VehCfg1_Stat "Configuration messages status 1";
CM_ SG_ 1000 VC_XWD "Drive configuration";
CM_ SG_ 1001 VC_AC_Prsnt "Vehicle is equipped with air conditioning; present = [1]";
CM_ SG_ 1001 VC_CRUISE_PRSNT "Cruise feature is present; present = [1]";
CM_ SG_ 1001 VC_DRVMD_Prsnt "Drive mode feature configuration (1 = Present)";
CM_ SG_ 1001 VC_ECO_Indicator "ECO Indicator present on vehicle; True = [1]";
CM_ SG_ 1001 VC_ESCDrvMd_Prsnt "ESC drive mode sub-feature configuration (1 = Present)";
CM_ SG_ 1001 VC_EngPowerDrvMd_Prsnt "ECM drive mode sub-feature configuration (1 = Present)";
CM_ SG_ 1001 VC_FG_PRSNT "Flipper glass present; present = [1]";
CM_ SG_ 1001 VC_FULL_SPARE "Full size spare; present = [1]";
CM_ SG_ 1001 VC_LgtLdPressFtTr "Light Load Inflation Pressure Front Tire";
CM_ SG_ 1001 VC_LgtLdPressRrTr "Light Load Inflation Pressure Rear Tire";
CM_ SG_ 1001 VC_MaseratiMd "Maserati vehicle mode";
CM_ SG_ 1001 VC_MaxLdPressFtTr "Max Load Inflation Pressure Front Tire";
CM_ SG_ 1001 VC_MaxLdPressRrTr "Max Load Inflation Pressure Rear Tire";
CM_ SG_ 1001 VC_MemoryDRVMD_Prsnt "Memory drive mode sub-feature configuration (1 = Present)";
CM_ SG_ 1001 VC_OffRoad "Off road capable; present = [1]";
CM_ SG_ 1001 VC_PADS_Prsnt "Pass. airbag disable switch present; present = [1]";
CM_ SG_ 1001 VC_PwrIvtrTyp "Power inverter type";
CM_ SG_ 1001 VC_RainSnsPrsnt "Rain sensor present; present = [1]";
CM_ SG_ 1001 VC_RunFlatTirePrsnt "Run flat tires present; present = [1]";
CM_ SG_ 1001 VC_SKIM_PRSNT "SKIM system present; present = [1]";
CM_ SG_ 1001 VC_SecPrkPrsnt "Secure park feature present; present = [1]";
CM_ SG_ 1001 VC_ShftInd_Prsnt "Configuration for performance & gear shift indication";
CM_ SG_ 1001 VC_SpecialPKG_IC "Special sales code package";
CM_ SG_ 1001 VC_ThatchamPrsnt "Thatcham present; present = [1]";
CM_ SG_ 1001 VC_VehCfg2_Stat "Configuration messages status 2";
BA_DEF_ BO_  "App-Botschaft" ENUM  "nein","ja";
BA_DEF_ BO_  "CanMsgMinLen" INT 0 8;
BA_DEF_ BO_  "DiagRequest" ENUM  "nein","ja";
BA_DEF_ BO_  "DiagResponse" ENUM  "nein","ja";
BA_DEF_ BO_  "DiagState" ENUM  "nein","ja";
BA_DEF_ BO_  "GenMsgCycleTime" INT 0 65535;
BA_DEF_ BO_  "GenMsgCycleTimeActive" INT 0 65535;
BA_DEF_ BO_  "GenMsgDelayTime" INT 0 65535;
BA_DEF_ BO_  "GenMsgNrOfRepetitions" INT 0 65535;
BA_DEF_ BO_  "GenMsgSendType" ENUM  "cyclicX","spontanX","cyclicIfActiveX","spontanWithDelay","cyclicAndSpontanX","cyclicAndSpontanWithDelay","spontanWithRepitition","cyclicIfActiveAndSpontanWD","cyclicIfActiveFast","cyclicWithRepeatOnDemand","none";
BA_DEF_ BO_  "GenMsgStartDelayTime" INT 0 65535;
BA_DEF_ BO_  "GenMsgStartValue" STRING ;
BA_DEF_ BO_  "NWM-Botschaft" ENUM  "nein","ja";
BA_DEF_ BO_  "TpTxIndex" INT 0 99;
BA_DEF_ SG_  "FlexKomComment" STRING ;
BA_DEF_ SG_  "FlexKomIsMotorola" ENUM  "nein","ja";
BA_DEF_ SG_  "FlexKomSID" INT 0 2147483647;
BA_DEF_ SG_  "FlexKomSigLaenge" INT 0 64;
BA_DEF_ SG_  "FlexKomSigName" STRING ;
BA_DEF_ SG_  "FlexKomSigStartPos" INT 0 63;
BA_DEF_ SG_  "FlexKomSigStartValue" STRING ;
BA_DEF_ SG_  "GenSigCycleTime" INT 0 65535;
BA_DEF_ SG_  "GenSigCycleTimeActive" INT 0 65535;
BA_DEF_ SG_  "GenSigSendType" ENUM  "cyclicX","spontanX","cyclicIfActiveX","spontanWithDelay","cyclicAndSpontanX","cyclicAndSpontanWithDelay","spontanWithRepitition","cyclicIfActiveAndSpontanWD","cyclicIfActiveFast","cyclicWithRepeatOnDemand","none";
BA_DEF_ SG_  "GenSigSNA" STRING ;
BA_DEF_ SG_  "GenSigStartValue" HEX 0 2147483648;
BA_DEF_ SG_  "GenSigTimeout_AHLM" INT 0 65535;
BA_DEF_ SG_  "GenSigTimeout_ASBS" INT 0 65535;
BA_DEF_ SG_  "GenSigTimeout_CBC" INT 0 65535;
BA_DEF_ SG_  "GenSigTimeout_DPDM" INT 0 65535;
BA_DEF_ SG_  "GenSigTimeout_DTCM" INT 0 65535;
BA_DEF_ SG_  "GenSigTimeout_EHPS" INT 0 65535;
BA_DEF_ SG_  "GenSigTimeout_ESC" INT 0 65535;
BA_DEF_ SG_  "GenSigTimeout_ESL" INT 0 65535;
BA_DEF_ SG_  "GenSigTimeout_ESM" INT 0 65535;
BA_DEF_ SG_  "GenSigTimeout_ETM" INT 0 65535;
BA_DEF_ SG_  "GenSigTimeout_IC" INT 0 65535;
BA_DEF_ SG_  "GenSigTimeout_OCM" INT 0 65535;
BA_DEF_ SG_  "GenSigTimeout_ORC" INT 0 65535;
BA_DEF_ SG_  "GenSigTimeout_PTS" INT 0 65535;
BA_DEF_ SG_  "GenSigTimeout_RF_HUB" INT 0 65535;
BA_DEF_ SG_  "GenSigTimeout_SCCM" INT 0 65535;
BA_DEF_ SG_  "GenSigTimeout_TBM" INT 0 65535;
BA_DEF_ SG_  "GenSigTimeout_TCM" INT 0 65535;
BA_DEF_ SG_  "GenSigTimeout_TPM" INT 0 65535;
BA_DEF_ SG_  "RID" STRING ;
BA_DEF_ SG_  "SystemSignalLongSymbol" STRING ;
BA_DEF_DEF_  "App-Botschaft" "nein";
BA_DEF_DEF_  "CanMsgMinLen" 0;
BA_DEF_DEF_  "DiagRequest" "nein";
BA_DEF_DEF_  "DiagResponse" "nein";
BA_DEF_DEF_  "DiagState" "nein";
BA_DEF_DEF_  "GenMsgCycleTime" 0;
BA_DEF_DEF_  "GenMsgCycleTimeActive" 0;
BA_DEF_DEF_  "GenMsgDelayTime" 0;
BA_DEF_DEF_  "GenMsgNrOfRepetitions" 0;
BA_DEF_DEF_  "GenMsgSendType" "cyclicX";
BA_DEF_DEF_  "GenMsgStartDelayTime" 0;
BA_DEF_DEF_  "GenMsgStartValue" "";
BA_DEF_DEF_  "NWM-Botschaft" "nein";
BA_DEF_DEF_  "TpTxIndex" 0;
BA_DEF_DEF_  "FlexKomComment" "";
BA_DEF_DEF_  "FlexKomIsMotorola" "nein";
BA_DEF_DEF_  "FlexKomSID" 0;
BA_DEF_DEF_  "FlexKomSigLaenge" 0;
BA_DEF_DEF_  "FlexKomSigName" "";
BA_DEF_DEF_  "FlexKomSigStartPos" 0;
BA_DEF_DEF_  "FlexKomSigStartValue" "";
BA_DEF_DEF_  "GenSigCycleTime" 0;
BA_DEF_DEF_  "GenSigCycleTimeActive" 0;
BA_DEF_DEF_  "GenSigSendType" "cyclicX";
BA_DEF_DEF_  "GenSigSNA" "";
BA_DEF_DEF_  "GenSigStartValue" 0;
BA_DEF_DEF_  "GenSigTimeout_AHLM" 0;
BA_DEF_DEF_  "GenSigTimeout_ASBS" 0;
BA_DEF_DEF_  "GenSigTimeout_CBC" 0;
BA_DEF_DEF_  "GenSigTimeout_DPDM" 0;
BA_DEF_DEF_  "GenSigTimeout_DTCM" 0;
BA_DEF_DEF_  "GenSigTimeout_EHPS" 0;
BA_DEF_DEF_  "GenSigTimeout_ESC" 0;
BA_DEF_DEF_  "GenSigTimeout_ESL" 0;
BA_DEF_DEF_  "GenSigTimeout_ESM" 0;
BA_DEF_DEF_  "GenSigTimeout_ETM" 0;
BA_DEF_DEF_  "GenSigTimeout_IC" 0;
BA_DEF_DEF_  "GenSigTimeout_OCM" 0;
BA_DEF_DEF_  "GenSigTimeout_ORC" 0;
BA_DEF_DEF_  "GenSigTimeout_PTS" 0;
BA_DEF_DEF_  "GenSigTimeout_RF_HUB" 0;
BA_DEF_DEF_  "GenSigTimeout_SCCM" 0;
BA_DEF_DEF_  "GenSigTimeout_TBM" 0;
BA_DEF_DEF_  "GenSigTimeout_TCM" 0;
BA_DEF_DEF_  "GenSigTimeout_TPM" 0;
BA_DEF_DEF_  "RID" "";
BA_DEF_DEF_  "SystemSignalLongSymbol" "";
BA_ "GenMsgStartValue" BO_ 1562 "0000000000000000h";
BA_ "GenMsgStartDelayTime" BO_ 1562 860;
BA_ "GenMsgSendType" BO_ 1562 9;
BA_ "GenMsgDelayTime" BO_ 1562 200;
BA_ "GenMsgCycleTime" BO_ 1562 200;
BA_ "GenMsgStartValue" BO_ 1543 "0000000000000000h";
BA_ "GenMsgStartDelayTime" BO_ 1543 870;
BA_ "GenMsgSendType" BO_ 1543 9;
BA_ "GenMsgDelayTime" BO_ 1543 200;
BA_ "GenMsgCycleTime" BO_ 1543 200;
BA_ "GenMsgStartValue" BO_ 1544 "0000000000000000h";
BA_ "GenMsgStartDelayTime" BO_ 1544 880;
BA_ "GenMsgSendType" BO_ 1544 9;
BA_ "GenMsgDelayTime" BO_ 1544 200;
BA_ "GenMsgCycleTime" BO_ 1544 200;
BA_ "GenMsgStartValue" BO_ 1545 "0000000000000000h";
BA_ "GenMsgStartDelayTime" BO_ 1545 890;
BA_ "GenMsgSendType" BO_ 1545 9;
BA_ "GenMsgDelayTime" BO_ 1545 200;
BA_ "GenMsgCycleTime" BO_ 1545 200;
BA_ "GenMsgStartValue" BO_ 1586 "0000000000000000h";
BA_ "GenMsgStartDelayTime" BO_ 1586 860;
BA_ "GenMsgSendType" BO_ 1586 9;
BA_ "GenMsgDelayTime" BO_ 1586 200;
BA_ "GenMsgCycleTime" BO_ 1586 200;
BA_ "GenMsgStartValue" BO_ 1594 "0000000000000000h";
BA_ "GenMsgStartDelayTime" BO_ 1594 980;
BA_ "GenMsgSendType" BO_ 1594 9;
BA_ "GenMsgDelayTime" BO_ 1594 200;
BA_ "GenMsgCycleTime" BO_ 1594 200;
BA_ "GenMsgStartValue" BO_ 1538 "0000000000000000h";
BA_ "GenMsgStartDelayTime" BO_ 1538 820;
BA_ "GenMsgSendType" BO_ 1538 9;
BA_ "GenMsgDelayTime" BO_ 1538 200;
BA_ "GenMsgCycleTime" BO_ 1538 200;
BA_ "GenMsgStartValue" BO_ 1566 "0000000000000000h";
BA_ "GenMsgStartDelayTime" BO_ 1566 800;
BA_ "GenMsgSendType" BO_ 1566 9;
BA_ "GenMsgDelayTime" BO_ 1566 200;
BA_ "GenMsgCycleTime" BO_ 1566 200;
BA_ "GenMsgStartValue" BO_ 1540 "0000000000000000h";
BA_ "GenMsgStartDelayTime" BO_ 1540 800;
BA_ "GenMsgSendType" BO_ 1540 9;
BA_ "GenMsgDelayTime" BO_ 1540 200;
BA_ "GenMsgCycleTime" BO_ 1540 200;
BA_ "GenMsgStartValue" BO_ 1570 "0000000000000000h";
BA_ "GenMsgStartDelayTime" BO_ 1570 800;
BA_ "GenMsgSendType" BO_ 1570 9;
BA_ "GenMsgDelayTime" BO_ 1570 200;
BA_ "GenMsgCycleTime" BO_ 1570 200;
BA_ "GenMsgStartValue" BO_ 1536 "0000000000000000h";
BA_ "GenMsgStartDelayTime" BO_ 1536 800;
BA_ "GenMsgSendType" BO_ 1536 9;
BA_ "GenMsgDelayTime" BO_ 1536 200;
BA_ "GenMsgCycleTime" BO_ 1536 200;
BA_ "GenMsgStartValue" BO_ 1571 "0000000000000000h";
BA_ "GenMsgStartDelayTime" BO_ 1571 950;
BA_ "GenMsgSendType" BO_ 1571 9;
BA_ "GenMsgDelayTime" BO_ 1571 200;
BA_ "GenMsgCycleTime" BO_ 1571 200;
BA_ "GenMsgStartValue" BO_ 1643 "0000000000000000h";
BA_ "GenMsgStartDelayTime" BO_ 1643 830;
BA_ "GenMsgSendType" BO_ 1643 9;
BA_ "GenMsgDelayTime" BO_ 1643 200;
BA_ "GenMsgCycleTime" BO_ 1643 200;
BA_ "GenMsgStartValue" BO_ 1593 "0000000000000000h";
BA_ "GenMsgStartDelayTime" BO_ 1593 800;
BA_ "GenMsgSendType" BO_ 1593 9;
BA_ "GenMsgDelayTime" BO_ 1593 200;
BA_ "GenMsgCycleTime" BO_ 1593 200;
BA_ "GenMsgStartValue" BO_ 1539 "0000000000000000h";
BA_ "GenMsgStartDelayTime" BO_ 1539 830;
BA_ "GenMsgSendType" BO_ 1539 9;
BA_ "GenMsgDelayTime" BO_ 1539 200;
BA_ "GenMsgCycleTime" BO_ 1539 200;
BA_ "GenMsgStartValue" BO_ 423 "0000h";
BA_ "GenMsgNrOfRepetitions" BO_ 423 2;
BA_ "GenMsgDelayTime" BO_ 423 20;
BA_ "GenMsgCycleTime" BO_ 423 250;
BA_ "GenMsgStartValue" BO_ 491 "0000000000000000h";
BA_ "GenMsgSendType" BO_ 491 5;
BA_ "GenMsgNrOfRepetitions" BO_ 491 2;
BA_ "GenMsgDelayTime" BO_ 491 20;
BA_ "GenMsgCycleTime" BO_ 491 500;
BA_ "GenMsgStartValue" BO_ 557 "FF00000000000000h";
BA_ "GenMsgStartDelayTime" BO_ 557 110;
BA_ "GenMsgSendType" BO_ 557 5;
BA_ "GenMsgNrOfRepetitions" BO_ 557 2;
BA_ "GenMsgDelayTime" BO_ 557 20;
BA_ "GenMsgCycleTime" BO_ 557 1000;
BA_ "GenMsgStartValue" BO_ 792 "000000000000FF00h";
BA_ "GenMsgSendType" BO_ 792 5;
BA_ "GenMsgNrOfRepetitions" BO_ 792 2;
BA_ "GenMsgDelayTime" BO_ 792 20;
BA_ "GenMsgCycleTime" BO_ 792 100;
BA_ "GenMsgStartValue" BO_ 793 "0000000000000000h";
BA_ "GenMsgSendType" BO_ 793 1;
BA_ "GenMsgNrOfRepetitions" BO_ 793 2;
BA_ "GenMsgDelayTime" BO_ 793 20;
BA_ "GenMsgStartValue" BO_ 794 "0000000000000000h";
BA_ "GenMsgSendType" BO_ 794 1;
BA_ "GenMsgNrOfRepetitions" BO_ 794 2;
BA_ "GenMsgDelayTime" BO_ 794 20;
BA_ "GenMsgStartValue" BO_ 795 "0000000000000000h";
BA_ "GenMsgSendType" BO_ 795 1;
BA_ "GenMsgNrOfRepetitions" BO_ 795 2;
BA_ "GenMsgDelayTime" BO_ 795 20;
BA_ "GenMsgStartValue" BO_ 171 "0FFF0F0F000000FFh";
BA_ "GenMsgNrOfRepetitions" BO_ 171 2;
BA_ "GenMsgDelayTime" BO_ 171 20;
BA_ "GenMsgCycleTime" BO_ 171 20;
BA_ "GenMsgStartValue" BO_ 945 "0000000000000000h";
BA_ "GenMsgSendType" BO_ 945 1;
BA_ "GenMsgNrOfRepetitions" BO_ 945 2;
BA_ "GenMsgDelayTime" BO_ 945 20;
BA_ "GenMsgStartValue" BO_ 944 "0000000000000000h";
BA_ "GenMsgSendType" BO_ 944 1;
BA_ "GenMsgNrOfRepetitions" BO_ 944 2;
BA_ "GenMsgDelayTime" BO_ 944 20;
BA_ "GenMsgStartValue" BO_ 946 "0000000000000000h";
BA_ "GenMsgSendType" BO_ 946 1;
BA_ "GenMsgNrOfRepetitions" BO_ 946 2;
BA_ "GenMsgDelayTime" BO_ 946 20;
BA_ "GenMsgStartValue" BO_ 179 "0000FFFF000000FFh";
BA_ "GenMsgNrOfRepetitions" BO_ 179 2;
BA_ "GenMsgDelayTime" BO_ 179 20;
BA_ "GenMsgCycleTime" BO_ 179 20;
BA_ "GenMsgStartValue" BO_ 149 "07FF001FFF00FFh";
BA_ "GenMsgNrOfRepetitions" BO_ 149 2;
BA_ "GenMsgDelayTime" BO_ 149 20;
BA_ "GenMsgCycleTime" BO_ 149 20;
BA_ "GenMsgStartValue" BO_ 55 "1FFF1FFF1FFF00FFh";
BA_ "GenMsgNrOfRepetitions" BO_ 55 2;
BA_ "GenMsgDelayTime" BO_ 55 20;
BA_ "GenMsgCycleTime" BO_ 55 10;
BA_ "GenMsgStartValue" BO_ 872 "0000000000000000h";
BA_ "GenMsgSendType" BO_ 872 1;
BA_ "GenMsgNrOfRepetitions" BO_ 872 2;
BA_ "GenMsgDelayTime" BO_ 872 20;
BA_ "GenMsgStartValue" BO_ 888 "0000000000000000h";
BA_ "GenMsgSendType" BO_ 888 1;
BA_ "GenMsgNrOfRepetitions" BO_ 888 2;
BA_ "GenMsgDelayTime" BO_ 888 20;
BA_ "GenMsgStartValue" BO_ 904 "0000000000000000h";
BA_ "GenMsgSendType" BO_ 904 1;
BA_ "GenMsgNrOfRepetitions" BO_ 904 2;
BA_ "GenMsgDelayTime" BO_ 904 20;
BA_ "GenMsgStartValue" BO_ 920 "0000000000000000h";
BA_ "GenMsgSendType" BO_ 920 1;
BA_ "GenMsgNrOfRepetitions" BO_ 920 2;
BA_ "GenMsgDelayTime" BO_ 920 20;
BA_ "GenMsgStartValue" BO_ 808 "0000000000000000h";
BA_ "GenMsgSendType" BO_ 808 5;
BA_ "GenMsgNrOfRepetitions" BO_ 808 2;
BA_ "GenMsgDelayTime" BO_ 808 20;
BA_ "GenMsgCycleTime" BO_ 808 1000;
BA_ "GenMsgStartValue" BO_ 662 "000000FFFFFFFFFFh";
BA_ "GenMsgSendType" BO_ 662 5;
BA_ "GenMsgNrOfRepetitions" BO_ 662 2;
BA_ "GenMsgDelayTime" BO_ 662 20;
BA_ "GenMsgCycleTime" BO_ 662 1000;
BA_ "GenMsgStartValue" BO_ 526 "000000800000h";
BA_ "GenMsgSendType" BO_ 526 1;
BA_ "GenMsgNrOfRepetitions" BO_ 526 2;
BA_ "GenMsgDelayTime" BO_ 526 20;
BA_ "GenMsgStartValue" BO_ 527 "0000000000000000h";
BA_ "GenMsgSendType" BO_ 527 1;
BA_ "GenMsgNrOfRepetitions" BO_ 527 2;
BA_ "GenMsgDelayTime" BO_ 527 20;
BA_ "GenMsgStartValue" BO_ 133 "00FF00FFFFFFFF00h";
BA_ "GenMsgNrOfRepetitions" BO_ 133 2;
BA_ "GenMsgDelayTime" BO_ 133 20;
BA_ "GenMsgCycleTime" BO_ 133 20;
BA_ "GenMsgStartValue" BO_ 147 "1CFFFF00000000FFh";
BA_ "GenMsgNrOfRepetitions" BO_ 147 2;
BA_ "GenMsgDelayTime" BO_ 147 20;
BA_ "GenMsgCycleTime" BO_ 147 20;
BA_ "GenMsgStartValue" BO_ 293 "F0FF80h";
BA_ "GenMsgNrOfRepetitions" BO_ 293 2;
BA_ "GenMsgDelayTime" BO_ 293 20;
BA_ "GenMsgCycleTime" BO_ 293 100;
BA_ "GenMsgStartValue" BO_ 698 "00000000h";
BA_ "GenMsgSendType" BO_ 698 8;
BA_ "GenMsgNrOfRepetitions" BO_ 698 2;
BA_ "GenMsgDelayTime" BO_ 698 20;
BA_ "GenMsgCycleTimeActive" BO_ 698 100;
BA_ "GenMsgStartValue" BO_ 992 "0300000000000000h";
BA_ "GenMsgNrOfRepetitions" BO_ 992 2;
BA_ "GenMsgDelayTime" BO_ 992 20;
BA_ "GenMsgCycleTime" BO_ 992 100;
BA_ "GenMsgStartValue" BO_ 1000 "FFFF7FF0FF0FFF00h";
BA_ "GenMsgStartDelayTime" BO_ 1000 50;
BA_ "GenMsgSendType" BO_ 1000 5;
BA_ "GenMsgNrOfRepetitions" BO_ 1000 2;
BA_ "GenMsgDelayTime" BO_ 1000 20;
BA_ "GenMsgCycleTime" BO_ 1000 500;
BA_ "GenMsgStartValue" BO_ 1001 "0300FF00FFFFFFFFh";
BA_ "GenMsgStartDelayTime" BO_ 1001 40;
BA_ "GenMsgSendType" BO_ 1001 5;
BA_ "GenMsgNrOfRepetitions" BO_ 1001 2;
BA_ "GenMsgDelayTime" BO_ 1001 20;
BA_ "GenMsgCycleTime" BO_ 1001 2000;
BA_ "GenSigSNA" SG_ 1562 SD_RS_EPS "0h";
BA_ "GenSigSendType" SG_ 1562 SD_RS_EPS 9;
BA_ "GenSigCycleTime" SG_ 1562 SD_RS_EPS 200;
BA_ "FlexKomSigStartValue" SG_ 1562 SD_RS_EPS "0000000000000000h";
BA_ "FlexKomSigStartPos" SG_ 1562 SD_RS_EPS 7;
BA_ "FlexKomSigName" SG_ 1562 SD_RS_EPS "SD_RS_EPS";
BA_ "FlexKomSigLaenge" SG_ 1562 SD_RS_EPS 64;
BA_ "FlexKomSID" SG_ 1562 SD_RS_EPS 194;
BA_ "FlexKomIsMotorola" SG_ 1562 SD_RS_EPS 1;
BA_ "FlexKomComment" SG_ 1562 SD_RS_EPS "Response on Event - light";
BA_ "GenSigSNA" SG_ 1543 SD_RS_ESC "0h";
BA_ "GenSigSendType" SG_ 1543 SD_RS_ESC 9;
BA_ "GenSigCycleTime" SG_ 1543 SD_RS_ESC 200;
BA_ "FlexKomSigStartValue" SG_ 1543 SD_RS_ESC "0000000000000000h";
BA_ "FlexKomSigStartPos" SG_ 1543 SD_RS_ESC 7;
BA_ "FlexKomSigName" SG_ 1543 SD_RS_ESC "SD_RS_ESC";
BA_ "FlexKomSigLaenge" SG_ 1543 SD_RS_ESC 64;
BA_ "FlexKomSID" SG_ 1543 SD_RS_ESC 196;
BA_ "FlexKomIsMotorola" SG_ 1543 SD_RS_ESC 1;
BA_ "FlexKomComment" SG_ 1543 SD_RS_ESC "Response on Event - light";
BA_ "GenSigSNA" SG_ 1544 SD_RS_ESL "0h";
BA_ "GenSigSendType" SG_ 1544 SD_RS_ESL 9;
BA_ "GenSigCycleTime" SG_ 1544 SD_RS_ESL 200;
BA_ "FlexKomSigStartValue" SG_ 1544 SD_RS_ESL "0000000000000000h";
BA_ "FlexKomSigStartPos" SG_ 1544 SD_RS_ESL 7;
BA_ "FlexKomSigName" SG_ 1544 SD_RS_ESL "SD_RS_ESL";
BA_ "FlexKomSigLaenge" SG_ 1544 SD_RS_ESL 64;
BA_ "FlexKomSID" SG_ 1544 SD_RS_ESL 2342;
BA_ "FlexKomIsMotorola" SG_ 1544 SD_RS_ESL 1;
BA_ "FlexKomComment" SG_ 1544 SD_RS_ESL "Response on Event - light";
BA_ "GenSigSNA" SG_ 1545 SD_RS_ESM "0h";
BA_ "GenSigSendType" SG_ 1545 SD_RS_ESM 9;
BA_ "GenSigCycleTime" SG_ 1545 SD_RS_ESM 200;
BA_ "FlexKomSigStartValue" SG_ 1545 SD_RS_ESM "0000000000000000h";
BA_ "FlexKomSigStartPos" SG_ 1545 SD_RS_ESM 7;
BA_ "FlexKomSigName" SG_ 1545 SD_RS_ESM "SD_RS_ESM";
BA_ "FlexKomSigLaenge" SG_ 1545 SD_RS_ESM 64;
BA_ "FlexKomSID" SG_ 1545 SD_RS_ESM 195;
BA_ "FlexKomIsMotorola" SG_ 1545 SD_RS_ESM 1;
BA_ "FlexKomComment" SG_ 1545 SD_RS_ESM "Response on Event - light";
BA_ "GenSigSNA" SG_ 1586 SD_RS_GPF "0h";
BA_ "GenSigSendType" SG_ 1586 SD_RS_GPF 9;
BA_ "GenSigCycleTime" SG_ 1586 SD_RS_GPF 200;
BA_ "FlexKomSigStartValue" SG_ 1586 SD_RS_GPF "0000000000000000h";
BA_ "FlexKomSigStartPos" SG_ 1586 SD_RS_GPF 7;
BA_ "FlexKomSigName" SG_ 1586 SD_RS_GPF "SD_RS_EPS";
BA_ "FlexKomSigLaenge" SG_ 1586 SD_RS_GPF 64;
BA_ "FlexKomSID" SG_ 1586 SD_RS_GPF 2829;
BA_ "FlexKomIsMotorola" SG_ 1586 SD_RS_GPF 1;
BA_ "FlexKomComment" SG_ 1586 SD_RS_GPF "Response on Event - light";
BA_ "GenSigSNA" SG_ 1594 SD_RS_HCP "0h";
BA_ "GenSigSendType" SG_ 1594 SD_RS_HCP 9;
BA_ "GenSigCycleTime" SG_ 1594 SD_RS_HCP 200;
BA_ "FlexKomSigStartValue" SG_ 1594 SD_RS_HCP "0000000000000000h";
BA_ "FlexKomSigStartPos" SG_ 1594 SD_RS_HCP 7;
BA_ "FlexKomSigName" SG_ 1594 SD_RS_HCP "SD_RS_HCP";
BA_ "FlexKomSigLaenge" SG_ 1594 SD_RS_HCP 64;
BA_ "FlexKomSID" SG_ 1594 SD_RS_HCP 2121;
BA_ "FlexKomIsMotorola" SG_ 1594 SD_RS_HCP 1;
BA_ "FlexKomComment" SG_ 1594 SD_RS_HCP "Response on Event - light";
BA_ "GenSigSNA" SG_ 1538 SD_RS_IC "0h";
BA_ "GenSigSendType" SG_ 1538 SD_RS_IC 9;
BA_ "GenSigCycleTime" SG_ 1538 SD_RS_IC 200;
BA_ "FlexKomSigStartValue" SG_ 1538 SD_RS_IC "0000000000000000h";
BA_ "FlexKomSigStartPos" SG_ 1538 SD_RS_IC 7;
BA_ "FlexKomSigName" SG_ 1538 SD_RS_IC "SD_RS_IC";
BA_ "FlexKomSigLaenge" SG_ 1538 SD_RS_IC 64;
BA_ "FlexKomSID" SG_ 1538 SD_RS_IC 201;
BA_ "FlexKomIsMotorola" SG_ 1538 SD_RS_IC 1;
BA_ "FlexKomComment" SG_ 1538 SD_RS_IC "Response on Event - light";
BA_ "GenSigSNA" SG_ 1566 SD_RS_OCM "0h";
BA_ "GenSigSendType" SG_ 1566 SD_RS_OCM 9;
BA_ "GenSigCycleTime" SG_ 1566 SD_RS_OCM 200;
BA_ "FlexKomSigStartValue" SG_ 1566 SD_RS_OCM "0000000000000000h";
BA_ "FlexKomSigStartPos" SG_ 1566 SD_RS_OCM 7;
BA_ "FlexKomSigName" SG_ 1566 SD_RS_OCM "SD_RS_OCM";
BA_ "FlexKomSigLaenge" SG_ 1566 SD_RS_OCM 64;
BA_ "FlexKomSID" SG_ 1566 SD_RS_OCM 1538;
BA_ "FlexKomIsMotorola" SG_ 1566 SD_RS_OCM 1;
BA_ "FlexKomComment" SG_ 1566 SD_RS_OCM "Response on Event - light";
BA_ "GenSigSNA" SG_ 1540 SD_RS_ORC "0h";
BA_ "GenSigSendType" SG_ 1540 SD_RS_ORC 9;
BA_ "GenSigCycleTime" SG_ 1540 SD_RS_ORC 200;
BA_ "FlexKomSigStartValue" SG_ 1540 SD_RS_ORC "0000000000000000h";
BA_ "FlexKomSigStartPos" SG_ 1540 SD_RS_ORC 7;
BA_ "FlexKomSigName" SG_ 1540 SD_RS_ORC "SD_RS_ORC";
BA_ "FlexKomSigLaenge" SG_ 1540 SD_RS_ORC 64;
BA_ "FlexKomSID" SG_ 1540 SD_RS_ORC 207;
BA_ "FlexKomIsMotorola" SG_ 1540 SD_RS_ORC 1;
BA_ "FlexKomComment" SG_ 1540 SD_RS_ORC "Response on Event - light";
BA_ "GenSigSNA" SG_ 1570 SD_RS_PTS "0h";
BA_ "GenSigSendType" SG_ 1570 SD_RS_PTS 9;
BA_ "GenSigCycleTime" SG_ 1570 SD_RS_PTS 200;
BA_ "FlexKomSigStartValue" SG_ 1570 SD_RS_PTS "0000000000000000h";
BA_ "FlexKomSigStartPos" SG_ 1570 SD_RS_PTS 7;
BA_ "FlexKomSigName" SG_ 1570 SD_RS_PTS "SD_RS_PTS";
BA_ "FlexKomSigLaenge" SG_ 1570 SD_RS_PTS 64;
BA_ "FlexKomSID" SG_ 1570 SD_RS_PTS 215;
BA_ "FlexKomIsMotorola" SG_ 1570 SD_RS_PTS 1;
BA_ "FlexKomComment" SG_ 1570 SD_RS_PTS "Response on Event - light";
BA_ "GenSigSNA" SG_ 1536 SD_RS_RF_HUB "0h";
BA_ "GenSigSendType" SG_ 1536 SD_RS_RF_HUB 9;
BA_ "GenSigCycleTime" SG_ 1536 SD_RS_RF_HUB 200;
BA_ "FlexKomSigStartValue" SG_ 1536 SD_RS_RF_HUB "0000000000000000h";
BA_ "FlexKomSigStartPos" SG_ 1536 SD_RS_RF_HUB 7;
BA_ "FlexKomSigName" SG_ 1536 SD_RS_RF_HUB "SD_RS_RF_HUB";
BA_ "FlexKomSigLaenge" SG_ 1536 SD_RS_RF_HUB 64;
BA_ "FlexKomSID" SG_ 1536 SD_RS_RF_HUB 198;
BA_ "FlexKomIsMotorola" SG_ 1536 SD_RS_RF_HUB 1;
BA_ "FlexKomComment" SG_ 1536 SD_RS_RF_HUB "Response on Event - light";
BA_ "GenSigSNA" SG_ 1571 SD_RS_SCCM "0h";
BA_ "GenSigSendType" SG_ 1571 SD_RS_SCCM 9;
BA_ "GenSigCycleTime" SG_ 1571 SD_RS_SCCM 200;
BA_ "FlexKomSigStartValue" SG_ 1571 SD_RS_SCCM "0000000000000000h";
BA_ "FlexKomSigStartPos" SG_ 1571 SD_RS_SCCM 7;
BA_ "FlexKomSigName" SG_ 1571 SD_RS_SCCM "SD_RS_SCCM";
BA_ "FlexKomSigLaenge" SG_ 1571 SD_RS_SCCM 64;
BA_ "FlexKomSID" SG_ 1571 SD_RS_SCCM 219;
BA_ "FlexKomIsMotorola" SG_ 1571 SD_RS_SCCM 1;
BA_ "FlexKomComment" SG_ 1571 SD_RS_SCCM "Response on Event - light";
BA_ "GenSigSNA" SG_ 1643 SD_RS_TBM "0h";
BA_ "GenSigSendType" SG_ 1643 SD_RS_TBM 9;
BA_ "GenSigCycleTime" SG_ 1643 SD_RS_TBM 200;
BA_ "FlexKomSigStartValue" SG_ 1643 SD_RS_TBM "0000000000000000h";
BA_ "FlexKomSigStartPos" SG_ 1643 SD_RS_TBM 7;
BA_ "FlexKomSigName" SG_ 1643 SD_RS_TBM "SD_RS_TBM";
BA_ "FlexKomSigLaenge" SG_ 1643 SD_RS_TBM 64;
BA_ "FlexKomSID" SG_ 1643 SD_RS_TBM 2433;
BA_ "FlexKomIsMotorola" SG_ 1643 SD_RS_TBM 1;
BA_ "FlexKomComment" SG_ 1643 SD_RS_TBM "Response on Event - light";
BA_ "GenSigSNA" SG_ 1593 SD_RS_TCM "0h";
BA_ "GenSigSendType" SG_ 1593 SD_RS_TCM 9;
BA_ "GenSigCycleTime" SG_ 1593 SD_RS_TCM 200;
BA_ "FlexKomSigStartValue" SG_ 1593 SD_RS_TCM "0000000000000000h";
BA_ "FlexKomSigStartPos" SG_ 1593 SD_RS_TCM 7;
BA_ "FlexKomSigName" SG_ 1593 SD_RS_TCM "SD_RS_TCM";
BA_ "FlexKomSigLaenge" SG_ 1593 SD_RS_TCM 64;
BA_ "FlexKomSID" SG_ 1593 SD_RS_TCM 223;
BA_ "FlexKomIsMotorola" SG_ 1593 SD_RS_TCM 1;
BA_ "FlexKomComment" SG_ 1593 SD_RS_TCM "Response on Event - light";
BA_ "GenSigSNA" SG_ 1539 SD_RS_TPM "0h";
BA_ "GenSigSendType" SG_ 1539 SD_RS_TPM 9;
BA_ "GenSigCycleTime" SG_ 1539 SD_RS_TPM 200;
BA_ "FlexKomSigStartValue" SG_ 1539 SD_RS_TPM "0000000000000000h";
BA_ "FlexKomSigStartPos" SG_ 1539 SD_RS_TPM 7;
BA_ "FlexKomSigName" SG_ 1539 SD_RS_TPM "SD_RS_TPM";
BA_ "FlexKomSigLaenge" SG_ 1539 SD_RS_TPM 64;
BA_ "FlexKomSID" SG_ 1539 SD_RS_TPM 226;
BA_ "FlexKomIsMotorola" SG_ 1539 SD_RS_TPM 1;
BA_ "FlexKomComment" SG_ 1539 SD_RS_TPM "Response on Event - light";
BA_ "GenSigSNA" SG_ 423 ESLSts "7h";
BA_ "GenSigCycleTime" SG_ 423 ESLSts 250;
BA_ "FlexKomSigStartValue" SG_ 423 ESLSts "0000h";
BA_ "FlexKomSigStartPos" SG_ 423 ESLSts 7;
BA_ "FlexKomSigName" SG_ 423 ESLSts "StatusESL_Pkt";
BA_ "FlexKomSigLaenge" SG_ 423 ESLSts 16;
BA_ "FlexKomSID" SG_ 423 ESLSts 2368;
BA_ "FlexKomIsMotorola" SG_ 423 ESLSts 1;
BA_ "FlexKomComment" SG_ 423 ESLSts "ESL status packet";
BA_ "GenSigSNA" SG_ 423 KeyOffWithHighSpeedSts "0h";
BA_ "GenSigCycleTime" SG_ 423 KeyOffWithHighSpeedSts 250;
BA_ "FlexKomSigStartValue" SG_ 423 KeyOffWithHighSpeedSts "0000h";
BA_ "FlexKomSigStartPos" SG_ 423 KeyOffWithHighSpeedSts 7;
BA_ "FlexKomSigName" SG_ 423 KeyOffWithHighSpeedSts "StatusESL_Pkt";
BA_ "FlexKomSigLaenge" SG_ 423 KeyOffWithHighSpeedSts 16;
BA_ "FlexKomSID" SG_ 423 KeyOffWithHighSpeedSts 2368;
BA_ "FlexKomIsMotorola" SG_ 423 KeyOffWithHighSpeedSts 1;
BA_ "FlexKomComment" SG_ 423 KeyOffWithHighSpeedSts "ESL status packet";
BA_ "GenSigTimeout_IC" SG_ 491 PTS_DBD 5250;
BA_ "GenSigSNA" SG_ 491 PTS_DBD "0h";
BA_ "GenSigSendType" SG_ 491 PTS_DBD 5;
BA_ "GenSigCycleTime" SG_ 491 PTS_DBD 500;
BA_ "FlexKomSigStartValue" SG_ 491 PTS_DBD "00h";
BA_ "FlexKomSigStartPos" SG_ 491 PTS_DBD 16;
BA_ "FlexKomSigName" SG_ 491 PTS_DBD "PTS_DBD";
BA_ "FlexKomSigLaenge" SG_ 491 PTS_DBD 1;
BA_ "FlexKomSID" SG_ 491 PTS_DBD 1949;
BA_ "FlexKomIsMotorola" SG_ 491 PTS_DBD 1;
BA_ "FlexKomComment" SG_ 491 PTS_DBD "Park assist system disabled; System_Disabled = [1]";
BA_ "RID" SG_ 557 Command_11 "1849";
BA_ "GenSigTimeout_IC" SG_ 557 Command_11 10500;
BA_ "GenSigSNA" SG_ 557 Command_11 "3h";
BA_ "GenSigSendType" SG_ 557 Command_11 5;
BA_ "GenSigCycleTime" SG_ 557 Command_11 1000;
BA_ "FlexKomSigStartValue" SG_ 557 Command_11 "FF00000000000000h";
BA_ "FlexKomSigStartPos" SG_ 557 Command_11 7;
BA_ "FlexKomSigName" SG_ 557 Command_11 "SWS8_Pkt";
BA_ "FlexKomSigLaenge" SG_ 557 Command_11 64;
BA_ "FlexKomSID" SG_ 557 Command_11 1811;
BA_ "FlexKomIsMotorola" SG_ 557 Command_11 1;
BA_ "FlexKomComment" SG_ 557 Command_11 "Steering wheel switch packet";
BA_ "RID" SG_ 557 Command_12 "1855";
BA_ "GenSigTimeout_IC" SG_ 557 Command_12 10500;
BA_ "GenSigSNA" SG_ 557 Command_12 "3h";
BA_ "GenSigSendType" SG_ 557 Command_12 5;
BA_ "GenSigCycleTime" SG_ 557 Command_12 1000;
BA_ "FlexKomSigStartValue" SG_ 557 Command_12 "FF00000000000000h";
BA_ "FlexKomSigStartPos" SG_ 557 Command_12 7;
BA_ "FlexKomSigName" SG_ 557 Command_12 "SWS8_Pkt";
BA_ "FlexKomSigLaenge" SG_ 557 Command_12 64;
BA_ "FlexKomSID" SG_ 557 Command_12 1811;
BA_ "FlexKomIsMotorola" SG_ 557 Command_12 1;
BA_ "FlexKomComment" SG_ 557 Command_12 "Steering wheel switch packet";
BA_ "RID" SG_ 557 Command_13 "1863";
BA_ "GenSigTimeout_IC" SG_ 557 Command_13 10500;
BA_ "GenSigSNA" SG_ 557 Command_13 "3h";
BA_ "GenSigSendType" SG_ 557 Command_13 5;
BA_ "GenSigCycleTime" SG_ 557 Command_13 1000;
BA_ "FlexKomSigStartValue" SG_ 557 Command_13 "FF00000000000000h";
BA_ "FlexKomSigStartPos" SG_ 557 Command_13 7;
BA_ "FlexKomSigName" SG_ 557 Command_13 "SWS8_Pkt";
BA_ "FlexKomSigLaenge" SG_ 557 Command_13 64;
BA_ "FlexKomSID" SG_ 557 Command_13 1811;
BA_ "FlexKomIsMotorola" SG_ 557 Command_13 1;
BA_ "FlexKomComment" SG_ 557 Command_13 "Steering wheel switch packet";
BA_ "RID" SG_ 557 Command_14 "1873";
BA_ "GenSigTimeout_IC" SG_ 557 Command_14 10500;
BA_ "GenSigSNA" SG_ 557 Command_14 "3h";
BA_ "GenSigSendType" SG_ 557 Command_14 5;
BA_ "GenSigCycleTime" SG_ 557 Command_14 1000;
BA_ "FlexKomSigStartValue" SG_ 557 Command_14 "FF00000000000000h";
BA_ "FlexKomSigStartPos" SG_ 557 Command_14 7;
BA_ "FlexKomSigName" SG_ 557 Command_14 "SWS8_Pkt";
BA_ "FlexKomSigLaenge" SG_ 557 Command_14 64;
BA_ "FlexKomSID" SG_ 557 Command_14 1811;
BA_ "FlexKomIsMotorola" SG_ 557 Command_14 1;
BA_ "FlexKomComment" SG_ 557 Command_14 "Steering wheel switch packet";
BA_ "RID" SG_ 557 Command_15 "1860";
BA_ "GenSigTimeout_IC" SG_ 557 Command_15 10500;
BA_ "GenSigSNA" SG_ 557 Command_15 "3h";
BA_ "GenSigSendType" SG_ 557 Command_15 5;
BA_ "GenSigCycleTime" SG_ 557 Command_15 1000;
BA_ "FlexKomSigStartValue" SG_ 557 Command_15 "FF00000000000000h";
BA_ "FlexKomSigStartPos" SG_ 557 Command_15 7;
BA_ "FlexKomSigName" SG_ 557 Command_15 "SWS8_Pkt";
BA_ "FlexKomSigLaenge" SG_ 557 Command_15 64;
BA_ "FlexKomSID" SG_ 557 Command_15 1811;
BA_ "FlexKomIsMotorola" SG_ 557 Command_15 1;
BA_ "FlexKomComment" SG_ 557 Command_15 "Steering wheel switch packet";
BA_ "RID" SG_ 792 HiBmLvr_Stat "1219 1294 1709";
BA_ "GenSigSNA" SG_ 792 HiBmLvr_Stat "0h";
BA_ "GenSigSendType" SG_ 792 HiBmLvr_Stat 5;
BA_ "GenSigCycleTime" SG_ 792 HiBmLvr_Stat 100;
BA_ "FlexKomSigStartValue" SG_ 792 HiBmLvr_Stat "000000000000FF00h";
BA_ "FlexKomSigStartPos" SG_ 792 HiBmLvr_Stat 7;
BA_ "FlexKomSigName" SG_ 792 HiBmLvr_Stat "StW_Actn_Rq";
BA_ "FlexKomSigLaenge" SG_ 792 HiBmLvr_Stat 64;
BA_ "FlexKomSID" SG_ 792 HiBmLvr_Stat 420;
BA_ "FlexKomIsMotorola" SG_ 792 HiBmLvr_Stat 1;
BA_ "FlexKomComment" SG_ 792 HiBmLvr_Stat "Steering wheel actuation request";
BA_ "RID" SG_ 792 TurnIndLvr_Stat "1220";
BA_ "GenSigTimeout_PTS" SG_ 792 TurnIndLvr_Stat 1050;
BA_ "GenSigSNA" SG_ 792 TurnIndLvr_Stat "0h";
BA_ "GenSigSendType" SG_ 792 TurnIndLvr_Stat 5;
BA_ "GenSigCycleTime" SG_ 792 TurnIndLvr_Stat 100;
BA_ "FlexKomSigStartValue" SG_ 792 TurnIndLvr_Stat "000000000000FF00h";
BA_ "FlexKomSigStartPos" SG_ 792 TurnIndLvr_Stat 7;
BA_ "FlexKomSigName" SG_ 792 TurnIndLvr_Stat "StW_Actn_Rq";
BA_ "FlexKomSigLaenge" SG_ 792 TurnIndLvr_Stat 64;
BA_ "FlexKomSID" SG_ 792 TurnIndLvr_Stat 420;
BA_ "FlexKomIsMotorola" SG_ 792 TurnIndLvr_Stat 1;
BA_ "FlexKomComment" SG_ 792 TurnIndLvr_Stat "Steering wheel actuation request";
BA_ "RID" SG_ 792 WprSw6Posn "1214 1297";
BA_ "GenSigTimeout_CBC" SG_ 792 WprSw6Posn 1050;
BA_ "GenSigSNA" SG_ 792 WprSw6Posn "Fh";
BA_ "GenSigSendType" SG_ 792 WprSw6Posn 5;
BA_ "GenSigCycleTime" SG_ 792 WprSw6Posn 100;
BA_ "FlexKomSigStartValue" SG_ 792 WprSw6Posn "000000000000FF00h";
BA_ "FlexKomSigStartPos" SG_ 792 WprSw6Posn 7;
BA_ "FlexKomSigName" SG_ 792 WprSw6Posn "StW_Actn_Rq";
BA_ "FlexKomSigLaenge" SG_ 792 WprSw6Posn 64;
BA_ "FlexKomSID" SG_ 792 WprSw6Posn 420;
BA_ "FlexKomIsMotorola" SG_ 792 WprSw6Posn 1;
BA_ "FlexKomComment" SG_ 792 WprSw6Posn "Steering wheel actuation request";
BA_ "RID" SG_ 792 WprWashSw_Psd "1234";
BA_ "GenSigSNA" SG_ 792 WprWashSw_Psd "0h";
BA_ "GenSigSendType" SG_ 792 WprWashSw_Psd 5;
BA_ "GenSigCycleTime" SG_ 792 WprWashSw_Psd 100;
BA_ "FlexKomSigStartValue" SG_ 792 WprWashSw_Psd "000000000000FF00h";
BA_ "FlexKomSigStartPos" SG_ 792 WprWashSw_Psd 7;
BA_ "FlexKomSigName" SG_ 792 WprWashSw_Psd "StW_Actn_Rq";
BA_ "FlexKomSigLaenge" SG_ 792 WprWashSw_Psd 64;
BA_ "FlexKomSID" SG_ 792 WprWashSw_Psd 420;
BA_ "FlexKomIsMotorola" SG_ 792 WprWashSw_Psd 1;
BA_ "FlexKomComment" SG_ 792 WprWashSw_Psd "Steering wheel actuation request";
BA_ "RID" SG_ 792 WprWash_R_Sw_Posn_V3 "1224";
BA_ "GenSigSNA" SG_ 792 WprWash_R_Sw_Posn_V3 "0h";
BA_ "GenSigSendType" SG_ 792 WprWash_R_Sw_Posn_V3 5;
BA_ "GenSigCycleTime" SG_ 792 WprWash_R_Sw_Posn_V3 100;
BA_ "FlexKomSigStartValue" SG_ 792 WprWash_R_Sw_Posn_V3 "000000000000FF00h";
BA_ "FlexKomSigStartPos" SG_ 792 WprWash_R_Sw_Posn_V3 7;
BA_ "FlexKomSigName" SG_ 792 WprWash_R_Sw_Posn_V3 "StW_Actn_Rq";
BA_ "FlexKomSigLaenge" SG_ 792 WprWash_R_Sw_Posn_V3 64;
BA_ "FlexKomSID" SG_ 792 WprWash_R_Sw_Posn_V3 420;
BA_ "FlexKomIsMotorola" SG_ 792 WprWash_R_Sw_Posn_V3 1;
BA_ "FlexKomComment" SG_ 792 WprWash_R_Sw_Posn_V3 "Steering wheel actuation request";
BA_ "RID" SG_ 793 Batt_CabinPriority1 "6664";
BA_ "GenSigSNA" SG_ 793 Batt_CabinPriority1 "0h";
BA_ "GenSigSendType" SG_ 793 Batt_CabinPriority1 1;
BA_ "FlexKomSigStartValue" SG_ 793 Batt_CabinPriority1 "0000000000000000h";
BA_ "FlexKomSigStartPos" SG_ 793 Batt_CabinPriority1 7;
BA_ "FlexKomSigName" SG_ 793 Batt_CabinPriority1 "TBM_SCHEDULE1";
BA_ "FlexKomSigLaenge" SG_ 793 Batt_CabinPriority1 64;
BA_ "FlexKomSID" SG_ 793 Batt_CabinPriority1 3105;
BA_ "FlexKomIsMotorola" SG_ 793 Batt_CabinPriority1 1;
BA_ "FlexKomComment" SG_ 793 Batt_CabinPriority1 "TBM_SCHEDULE1";
BA_ "RID" SG_ 793 ChargeUntilFull1 "6615";
BA_ "GenSigSNA" SG_ 793 ChargeUntilFull1 "0h";
BA_ "GenSigSendType" SG_ 793 ChargeUntilFull1 1;
BA_ "FlexKomSigStartValue" SG_ 793 ChargeUntilFull1 "0000000000000000h";
BA_ "FlexKomSigStartPos" SG_ 793 ChargeUntilFull1 7;
BA_ "FlexKomSigName" SG_ 793 ChargeUntilFull1 "TBM_SCHEDULE1";
BA_ "FlexKomSigLaenge" SG_ 793 ChargeUntilFull1 64;
BA_ "FlexKomSID" SG_ 793 ChargeUntilFull1 3105;
BA_ "FlexKomIsMotorola" SG_ 793 ChargeUntilFull1 1;
BA_ "FlexKomComment" SG_ 793 ChargeUntilFull1 "TBM_SCHEDULE1";
BA_ "RID" SG_ 793 Do_Not_Repeat1 "6668";
BA_ "GenSigSNA" SG_ 793 Do_Not_Repeat1 "0h";
BA_ "GenSigSendType" SG_ 793 Do_Not_Repeat1 1;
BA_ "FlexKomSigStartValue" SG_ 793 Do_Not_Repeat1 "0000000000000000h";
BA_ "FlexKomSigStartPos" SG_ 793 Do_Not_Repeat1 7;
BA_ "FlexKomSigName" SG_ 793 Do_Not_Repeat1 "TBM_SCHEDULE1";
BA_ "FlexKomSigLaenge" SG_ 793 Do_Not_Repeat1 64;
BA_ "FlexKomSID" SG_ 793 Do_Not_Repeat1 3105;
BA_ "FlexKomIsMotorola" SG_ 793 Do_Not_Repeat1 1;
BA_ "FlexKomComment" SG_ 793 Do_Not_Repeat1 "TBM_SCHEDULE1";
BA_ "RID" SG_ 793 Enable_Schedule1 "6696";
BA_ "GenSigSNA" SG_ 793 Enable_Schedule1 "0h";
BA_ "GenSigSendType" SG_ 793 Enable_Schedule1 1;
BA_ "FlexKomSigStartValue" SG_ 793 Enable_Schedule1 "0000000000000000h";
BA_ "FlexKomSigStartPos" SG_ 793 Enable_Schedule1 7;
BA_ "FlexKomSigName" SG_ 793 Enable_Schedule1 "TBM_SCHEDULE1";
BA_ "FlexKomSigLaenge" SG_ 793 Enable_Schedule1 64;
BA_ "FlexKomSID" SG_ 793 Enable_Schedule1 3105;
BA_ "FlexKomIsMotorola" SG_ 793 Enable_Schedule1 1;
BA_ "FlexKomComment" SG_ 793 Enable_Schedule1 "TBM_SCHEDULE1";
BA_ "RID" SG_ 793 End_Time_Hr1 "6655";
BA_ "GenSigSNA" SG_ 793 End_Time_Hr1 "1Fh";
BA_ "GenSigSendType" SG_ 793 End_Time_Hr1 1;
BA_ "FlexKomSigStartValue" SG_ 793 End_Time_Hr1 "0000000000000000h";
BA_ "FlexKomSigStartPos" SG_ 793 End_Time_Hr1 7;
BA_ "FlexKomSigName" SG_ 793 End_Time_Hr1 "TBM_SCHEDULE1";
BA_ "FlexKomSigLaenge" SG_ 793 End_Time_Hr1 64;
BA_ "FlexKomSID" SG_ 793 End_Time_Hr1 3105;
BA_ "FlexKomIsMotorola" SG_ 793 End_Time_Hr1 1;
BA_ "FlexKomComment" SG_ 793 End_Time_Hr1 "TBM_SCHEDULE1";
BA_ "RID" SG_ 793 End_Time_Min1 "6671";
BA_ "GenSigSNA" SG_ 793 End_Time_Min1 "Fh";
BA_ "GenSigSendType" SG_ 793 End_Time_Min1 1;
BA_ "FlexKomSigStartValue" SG_ 793 End_Time_Min1 "0000000000000000h";
BA_ "FlexKomSigStartPos" SG_ 793 End_Time_Min1 7;
BA_ "FlexKomSigName" SG_ 793 End_Time_Min1 "TBM_SCHEDULE1";
BA_ "FlexKomSigLaenge" SG_ 793 End_Time_Min1 64;
BA_ "FlexKomSID" SG_ 793 End_Time_Min1 3105;
BA_ "FlexKomIsMotorola" SG_ 793 End_Time_Min1 1;
BA_ "FlexKomComment" SG_ 793 End_Time_Min1 "TBM_SCHEDULE1";
BA_ "RID" SG_ 793 Schedule_Day1 "6616";
BA_ "GenSigSNA" SG_ 793 Schedule_Day1 "FFh";
BA_ "GenSigSendType" SG_ 793 Schedule_Day1 1;
BA_ "FlexKomSigStartValue" SG_ 793 Schedule_Day1 "0000000000000000h";
BA_ "FlexKomSigStartPos" SG_ 793 Schedule_Day1 7;
BA_ "FlexKomSigName" SG_ 793 Schedule_Day1 "TBM_SCHEDULE1";
BA_ "FlexKomSigLaenge" SG_ 793 Schedule_Day1 64;
BA_ "FlexKomSID" SG_ 793 Schedule_Day1 3105;
BA_ "FlexKomIsMotorola" SG_ 793 Schedule_Day1 1;
BA_ "FlexKomComment" SG_ 793 Schedule_Day1 "TBM_SCHEDULE1";
BA_ "RID" SG_ 793 Schedule_Type1 "6617";
BA_ "GenSigSNA" SG_ 793 Schedule_Type1 "3h";
BA_ "GenSigSendType" SG_ 793 Schedule_Type1 1;
BA_ "FlexKomSigStartValue" SG_ 793 Schedule_Type1 "0000000000000000h";
BA_ "FlexKomSigStartPos" SG_ 793 Schedule_Type1 7;
BA_ "FlexKomSigName" SG_ 793 Schedule_Type1 "TBM_SCHEDULE1";
BA_ "FlexKomSigLaenge" SG_ 793 Schedule_Type1 64;
BA_ "FlexKomSID" SG_ 793 Schedule_Type1 3105;
BA_ "FlexKomIsMotorola" SG_ 793 Schedule_Type1 1;
BA_ "FlexKomComment" SG_ 793 Schedule_Type1 "TBM_SCHEDULE1";
BA_ "RID" SG_ 793 Start_Time_Hr1 "6636";
BA_ "GenSigSNA" SG_ 793 Start_Time_Hr1 "1Fh";
BA_ "GenSigSendType" SG_ 793 Start_Time_Hr1 1;
BA_ "FlexKomSigStartValue" SG_ 793 Start_Time_Hr1 "0000000000000000h";
BA_ "FlexKomSigStartPos" SG_ 793 Start_Time_Hr1 7;
BA_ "FlexKomSigName" SG_ 793 Start_Time_Hr1 "TBM_SCHEDULE1";
BA_ "FlexKomSigLaenge" SG_ 793 Start_Time_Hr1 64;
BA_ "FlexKomSID" SG_ 793 Start_Time_Hr1 3105;
BA_ "FlexKomIsMotorola" SG_ 793 Start_Time_Hr1 1;
BA_ "FlexKomComment" SG_ 793 Start_Time_Hr1 "TBM_SCHEDULE1";
BA_ "RID" SG_ 793 Start_Time_Min1 "6661";
BA_ "GenSigSNA" SG_ 793 Start_Time_Min1 "Fh";
BA_ "GenSigSendType" SG_ 793 Start_Time_Min1 1;
BA_ "FlexKomSigStartValue" SG_ 793 Start_Time_Min1 "0000000000000000h";
BA_ "FlexKomSigStartPos" SG_ 793 Start_Time_Min1 7;
BA_ "FlexKomSigName" SG_ 793 Start_Time_Min1 "TBM_SCHEDULE1";
BA_ "FlexKomSigLaenge" SG_ 793 Start_Time_Min1 64;
BA_ "FlexKomSID" SG_ 793 Start_Time_Min1 3105;
BA_ "FlexKomIsMotorola" SG_ 793 Start_Time_Min1 1;
BA_ "FlexKomComment" SG_ 793 Start_Time_Min1 "TBM_SCHEDULE1";
BA_ "RID" SG_ 793 Submit_Schedule1 "6648";
BA_ "GenSigSNA" SG_ 793 Submit_Schedule1 "0h";
BA_ "GenSigSendType" SG_ 793 Submit_Schedule1 1;
BA_ "FlexKomSigStartValue" SG_ 793 Submit_Schedule1 "0000000000000000h";
BA_ "FlexKomSigStartPos" SG_ 793 Submit_Schedule1 7;
BA_ "FlexKomSigName" SG_ 793 Submit_Schedule1 "TBM_SCHEDULE1";
BA_ "FlexKomSigLaenge" SG_ 793 Submit_Schedule1 64;
BA_ "FlexKomSID" SG_ 793 Submit_Schedule1 3105;
BA_ "FlexKomIsMotorola" SG_ 793 Submit_Schedule1 1;
BA_ "FlexKomComment" SG_ 793 Submit_Schedule1 "TBM_SCHEDULE1";
BA_ "RID" SG_ 794 Batt_CabinPriority2 "6702";
BA_ "GenSigSNA" SG_ 794 Batt_CabinPriority2 "0h";
BA_ "GenSigSendType" SG_ 794 Batt_CabinPriority2 1;
BA_ "FlexKomSigStartValue" SG_ 794 Batt_CabinPriority2 "0000000000000000h";
BA_ "FlexKomSigStartPos" SG_ 794 Batt_CabinPriority2 7;
BA_ "FlexKomSigName" SG_ 794 Batt_CabinPriority2 "TBM_SCHEDULE2";
BA_ "FlexKomSigLaenge" SG_ 794 Batt_CabinPriority2 64;
BA_ "FlexKomSID" SG_ 794 Batt_CabinPriority2 3106;
BA_ "FlexKomIsMotorola" SG_ 794 Batt_CabinPriority2 1;
BA_ "FlexKomComment" SG_ 794 Batt_CabinPriority2 "TBM_SCHEDULE2";
BA_ "RID" SG_ 794 ChargeUntilFull2 "6618";
BA_ "GenSigSNA" SG_ 794 ChargeUntilFull2 "0h";
BA_ "GenSigSendType" SG_ 794 ChargeUntilFull2 1;
BA_ "FlexKomSigStartValue" SG_ 794 ChargeUntilFull2 "0000000000000000h";
BA_ "FlexKomSigStartPos" SG_ 794 ChargeUntilFull2 7;
BA_ "FlexKomSigName" SG_ 794 ChargeUntilFull2 "TBM_SCHEDULE2";
BA_ "FlexKomSigLaenge" SG_ 794 ChargeUntilFull2 64;
BA_ "FlexKomSID" SG_ 794 ChargeUntilFull2 3106;
BA_ "FlexKomIsMotorola" SG_ 794 ChargeUntilFull2 1;
BA_ "FlexKomComment" SG_ 794 ChargeUntilFull2 "TBM_SCHEDULE2";
BA_ "RID" SG_ 794 Do_Not_Repeat2 "6667";
BA_ "GenSigSNA" SG_ 794 Do_Not_Repeat2 "0h";
BA_ "GenSigSendType" SG_ 794 Do_Not_Repeat2 1;
BA_ "FlexKomSigStartValue" SG_ 794 Do_Not_Repeat2 "0000000000000000h";
BA_ "FlexKomSigStartPos" SG_ 794 Do_Not_Repeat2 7;
BA_ "FlexKomSigName" SG_ 794 Do_Not_Repeat2 "TBM_SCHEDULE2";
BA_ "FlexKomSigLaenge" SG_ 794 Do_Not_Repeat2 64;
BA_ "FlexKomSID" SG_ 794 Do_Not_Repeat2 3106;
BA_ "FlexKomIsMotorola" SG_ 794 Do_Not_Repeat2 1;
BA_ "FlexKomComment" SG_ 794 Do_Not_Repeat2 "TBM_SCHEDULE2";
BA_ "RID" SG_ 794 Enable_Schedule2 "6612";
BA_ "GenSigSNA" SG_ 794 Enable_Schedule2 "0h";
BA_ "GenSigSendType" SG_ 794 Enable_Schedule2 1;
BA_ "FlexKomSigStartValue" SG_ 794 Enable_Schedule2 "0000000000000000h";
BA_ "FlexKomSigStartPos" SG_ 794 Enable_Schedule2 7;
BA_ "FlexKomSigName" SG_ 794 Enable_Schedule2 "TBM_SCHEDULE2";
BA_ "FlexKomSigLaenge" SG_ 794 Enable_Schedule2 64;
BA_ "FlexKomSID" SG_ 794 Enable_Schedule2 3106;
BA_ "FlexKomIsMotorola" SG_ 794 Enable_Schedule2 1;
BA_ "FlexKomComment" SG_ 794 Enable_Schedule2 "TBM_SCHEDULE2";
BA_ "RID" SG_ 794 End_Time_Hr2 "6684";
BA_ "GenSigSNA" SG_ 794 End_Time_Hr2 "1Fh";
BA_ "GenSigSendType" SG_ 794 End_Time_Hr2 1;
BA_ "FlexKomSigStartValue" SG_ 794 End_Time_Hr2 "0000000000000000h";
BA_ "FlexKomSigStartPos" SG_ 794 End_Time_Hr2 7;
BA_ "FlexKomSigName" SG_ 794 End_Time_Hr2 "TBM_SCHEDULE2";
BA_ "FlexKomSigLaenge" SG_ 794 End_Time_Hr2 64;
BA_ "FlexKomSID" SG_ 794 End_Time_Hr2 3106;
BA_ "FlexKomIsMotorola" SG_ 794 End_Time_Hr2 1;
BA_ "FlexKomComment" SG_ 794 End_Time_Hr2 "TBM_SCHEDULE2";
BA_ "RID" SG_ 794 End_Time_Min2 "6642";
BA_ "GenSigSNA" SG_ 794 End_Time_Min2 "Fh";
BA_ "GenSigSendType" SG_ 794 End_Time_Min2 1;
BA_ "FlexKomSigStartValue" SG_ 794 End_Time_Min2 "0000000000000000h";
BA_ "FlexKomSigStartPos" SG_ 794 End_Time_Min2 7;
BA_ "FlexKomSigName" SG_ 794 End_Time_Min2 "TBM_SCHEDULE2";
BA_ "FlexKomSigLaenge" SG_ 794 End_Time_Min2 64;
BA_ "FlexKomSID" SG_ 794 End_Time_Min2 3106;
BA_ "FlexKomIsMotorola" SG_ 794 End_Time_Min2 1;
BA_ "FlexKomComment" SG_ 794 End_Time_Min2 "TBM_SCHEDULE2";
BA_ "RID" SG_ 794 Schedule_Day2 "6703";
BA_ "GenSigSNA" SG_ 794 Schedule_Day2 "FFh";
BA_ "GenSigSendType" SG_ 794 Schedule_Day2 1;
BA_ "FlexKomSigStartValue" SG_ 794 Schedule_Day2 "0000000000000000h";
BA_ "FlexKomSigStartPos" SG_ 794 Schedule_Day2 7;
BA_ "FlexKomSigName" SG_ 794 Schedule_Day2 "TBM_SCHEDULE2";
BA_ "FlexKomSigLaenge" SG_ 794 Schedule_Day2 64;
BA_ "FlexKomSID" SG_ 794 Schedule_Day2 3106;
BA_ "FlexKomIsMotorola" SG_ 794 Schedule_Day2 1;
BA_ "FlexKomComment" SG_ 794 Schedule_Day2 "TBM_SCHEDULE2";
BA_ "RID" SG_ 794 Schedule_Type2 "6693";
BA_ "GenSigSNA" SG_ 794 Schedule_Type2 "3h";
BA_ "GenSigSendType" SG_ 794 Schedule_Type2 1;
BA_ "FlexKomSigStartValue" SG_ 794 Schedule_Type2 "0000000000000000h";
BA_ "FlexKomSigStartPos" SG_ 794 Schedule_Type2 7;
BA_ "FlexKomSigName" SG_ 794 Schedule_Type2 "TBM_SCHEDULE2";
BA_ "FlexKomSigLaenge" SG_ 794 Schedule_Type2 64;
BA_ "FlexKomSID" SG_ 794 Schedule_Type2 3106;
BA_ "FlexKomIsMotorola" SG_ 794 Schedule_Type2 1;
BA_ "FlexKomComment" SG_ 794 Schedule_Type2 "TBM_SCHEDULE2";
BA_ "RID" SG_ 794 Start_Time_Hr2 "6624";
BA_ "GenSigSNA" SG_ 794 Start_Time_Hr2 "1Fh";
BA_ "GenSigSendType" SG_ 794 Start_Time_Hr2 1;
BA_ "FlexKomSigStartValue" SG_ 794 Start_Time_Hr2 "0000000000000000h";
BA_ "FlexKomSigStartPos" SG_ 794 Start_Time_Hr2 7;
BA_ "FlexKomSigName" SG_ 794 Start_Time_Hr2 "TBM_SCHEDULE2";
BA_ "FlexKomSigLaenge" SG_ 794 Start_Time_Hr2 64;
BA_ "FlexKomSID" SG_ 794 Start_Time_Hr2 3106;
BA_ "FlexKomIsMotorola" SG_ 794 Start_Time_Hr2 1;
BA_ "FlexKomComment" SG_ 794 Start_Time_Hr2 "TBM_SCHEDULE2";
BA_ "RID" SG_ 794 Start_Time_Min2 "6679";
BA_ "GenSigSNA" SG_ 794 Start_Time_Min2 "Fh";
BA_ "GenSigSendType" SG_ 794 Start_Time_Min2 1;
BA_ "FlexKomSigStartValue" SG_ 794 Start_Time_Min2 "0000000000000000h";
BA_ "FlexKomSigStartPos" SG_ 794 Start_Time_Min2 7;
BA_ "FlexKomSigName" SG_ 794 Start_Time_Min2 "TBM_SCHEDULE2";
BA_ "FlexKomSigLaenge" SG_ 794 Start_Time_Min2 64;
BA_ "FlexKomSID" SG_ 794 Start_Time_Min2 3106;
BA_ "FlexKomIsMotorola" SG_ 794 Start_Time_Min2 1;
BA_ "FlexKomComment" SG_ 794 Start_Time_Min2 "TBM_SCHEDULE2";
BA_ "RID" SG_ 794 Submit_Schedule2 "6686";
BA_ "GenSigSNA" SG_ 794 Submit_Schedule2 "0h";
BA_ "GenSigSendType" SG_ 794 Submit_Schedule2 1;
BA_ "FlexKomSigStartValue" SG_ 794 Submit_Schedule2 "0000000000000000h";
BA_ "FlexKomSigStartPos" SG_ 794 Submit_Schedule2 7;
BA_ "FlexKomSigName" SG_ 794 Submit_Schedule2 "TBM_SCHEDULE2";
BA_ "FlexKomSigLaenge" SG_ 794 Submit_Schedule2 64;
BA_ "FlexKomSID" SG_ 794 Submit_Schedule2 3106;
BA_ "FlexKomIsMotorola" SG_ 794 Submit_Schedule2 1;
BA_ "FlexKomComment" SG_ 794 Submit_Schedule2 "TBM_SCHEDULE2";
BA_ "RID" SG_ 795 Batt_CabinPriority3 "6634";
BA_ "GenSigSNA" SG_ 795 Batt_CabinPriority3 "0h";
BA_ "GenSigSendType" SG_ 795 Batt_CabinPriority3 1;
BA_ "FlexKomSigStartValue" SG_ 795 Batt_CabinPriority3 "0000000000000000h";
BA_ "FlexKomSigStartPos" SG_ 795 Batt_CabinPriority3 7;
BA_ "FlexKomSigName" SG_ 795 Batt_CabinPriority3 "TBM_SCHEDULE3";
BA_ "FlexKomSigLaenge" SG_ 795 Batt_CabinPriority3 64;
BA_ "FlexKomSID" SG_ 795 Batt_CabinPriority3 3107;
BA_ "FlexKomIsMotorola" SG_ 795 Batt_CabinPriority3 1;
BA_ "FlexKomComment" SG_ 795 Batt_CabinPriority3 "TBM_SCHEDULE3";
BA_ "RID" SG_ 795 ChargeUntilFull3 "6608";
BA_ "GenSigSNA" SG_ 795 ChargeUntilFull3 "0h";
BA_ "GenSigSendType" SG_ 795 ChargeUntilFull3 1;
BA_ "FlexKomSigStartValue" SG_ 795 ChargeUntilFull3 "0000000000000000h";
BA_ "FlexKomSigStartPos" SG_ 795 ChargeUntilFull3 7;
BA_ "FlexKomSigName" SG_ 795 ChargeUntilFull3 "TBM_SCHEDULE3";
BA_ "FlexKomSigLaenge" SG_ 795 ChargeUntilFull3 64;
BA_ "FlexKomSID" SG_ 795 ChargeUntilFull3 3107;
BA_ "FlexKomIsMotorola" SG_ 795 ChargeUntilFull3 1;
BA_ "FlexKomComment" SG_ 795 ChargeUntilFull3 "TBM_SCHEDULE3";
BA_ "RID" SG_ 795 Do_Not_Repeat3 "6694";
BA_ "GenSigSNA" SG_ 795 Do_Not_Repeat3 "0h";
BA_ "GenSigSendType" SG_ 795 Do_Not_Repeat3 1;
BA_ "FlexKomSigStartValue" SG_ 795 Do_Not_Repeat3 "0000000000000000h";
BA_ "FlexKomSigStartPos" SG_ 795 Do_Not_Repeat3 7;
BA_ "FlexKomSigName" SG_ 795 Do_Not_Repeat3 "TBM_SCHEDULE3";
BA_ "FlexKomSigLaenge" SG_ 795 Do_Not_Repeat3 64;
BA_ "FlexKomSID" SG_ 795 Do_Not_Repeat3 3107;
BA_ "FlexKomIsMotorola" SG_ 795 Do_Not_Repeat3 1;
BA_ "FlexKomComment" SG_ 795 Do_Not_Repeat3 "TBM_SCHEDULE3";
BA_ "RID" SG_ 795 Enable_Schedule3 "6629";
BA_ "GenSigSNA" SG_ 795 Enable_Schedule3 "0h";
BA_ "GenSigSendType" SG_ 795 Enable_Schedule3 1;
BA_ "FlexKomSigStartValue" SG_ 795 Enable_Schedule3 "0000000000000000h";
BA_ "FlexKomSigStartPos" SG_ 795 Enable_Schedule3 7;
BA_ "FlexKomSigName" SG_ 795 Enable_Schedule3 "TBM_SCHEDULE3";
BA_ "FlexKomSigLaenge" SG_ 795 Enable_Schedule3 64;
BA_ "FlexKomSID" SG_ 795 Enable_Schedule3 3107;
BA_ "FlexKomIsMotorola" SG_ 795 Enable_Schedule3 1;
BA_ "FlexKomComment" SG_ 795 Enable_Schedule3 "TBM_SCHEDULE3";
BA_ "RID" SG_ 795 End_Time_Hr3 "6658";
BA_ "GenSigSNA" SG_ 795 End_Time_Hr3 "1Fh";
BA_ "GenSigSendType" SG_ 795 End_Time_Hr3 1;
BA_ "FlexKomSigStartValue" SG_ 795 End_Time_Hr3 "0000000000000000h";
BA_ "FlexKomSigStartPos" SG_ 795 End_Time_Hr3 7;
BA_ "FlexKomSigName" SG_ 795 End_Time_Hr3 "TBM_SCHEDULE3";
BA_ "FlexKomSigLaenge" SG_ 795 End_Time_Hr3 64;
BA_ "FlexKomSID" SG_ 795 End_Time_Hr3 3107;
BA_ "FlexKomIsMotorola" SG_ 795 End_Time_Hr3 1;
BA_ "FlexKomComment" SG_ 795 End_Time_Hr3 "TBM_SCHEDULE3";
BA_ "RID" SG_ 795 End_Time_Min3 "6697";
BA_ "GenSigSNA" SG_ 795 End_Time_Min3 "Fh";
BA_ "GenSigSendType" SG_ 795 End_Time_Min3 1;
BA_ "FlexKomSigStartValue" SG_ 795 End_Time_Min3 "0000000000000000h";
BA_ "FlexKomSigStartPos" SG_ 795 End_Time_Min3 7;
BA_ "FlexKomSigName" SG_ 795 End_Time_Min3 "TBM_SCHEDULE3";
BA_ "FlexKomSigLaenge" SG_ 795 End_Time_Min3 64;
BA_ "FlexKomSID" SG_ 795 End_Time_Min3 3107;
BA_ "FlexKomIsMotorola" SG_ 795 End_Time_Min3 1;
BA_ "FlexKomComment" SG_ 795 End_Time_Min3 "TBM_SCHEDULE3";
BA_ "RID" SG_ 795 Schedule_Day3 "6680";
BA_ "GenSigSNA" SG_ 795 Schedule_Day3 "FFh";
BA_ "GenSigSendType" SG_ 795 Schedule_Day3 1;
BA_ "FlexKomSigStartValue" SG_ 795 Schedule_Day3 "0000000000000000h";
BA_ "FlexKomSigStartPos" SG_ 795 Schedule_Day3 7;
BA_ "FlexKomSigName" SG_ 795 Schedule_Day3 "TBM_SCHEDULE3";
BA_ "FlexKomSigLaenge" SG_ 795 Schedule_Day3 64;
BA_ "FlexKomSID" SG_ 795 Schedule_Day3 3107;
BA_ "FlexKomIsMotorola" SG_ 795 Schedule_Day3 1;
BA_ "FlexKomComment" SG_ 795 Schedule_Day3 "TBM_SCHEDULE3";
BA_ "RID" SG_ 795 Schedule_Type3 "6646";
BA_ "GenSigSNA" SG_ 795 Schedule_Type3 "3h";
BA_ "GenSigSendType" SG_ 795 Schedule_Type3 1;
BA_ "FlexKomSigStartValue" SG_ 795 Schedule_Type3 "0000000000000000h";
BA_ "FlexKomSigStartPos" SG_ 795 Schedule_Type3 7;
BA_ "FlexKomSigName" SG_ 795 Schedule_Type3 "TBM_SCHEDULE3";
BA_ "FlexKomSigLaenge" SG_ 795 Schedule_Type3 64;
BA_ "FlexKomSID" SG_ 795 Schedule_Type3 3107;
BA_ "FlexKomIsMotorola" SG_ 795 Schedule_Type3 1;
BA_ "FlexKomComment" SG_ 795 Schedule_Type3 "TBM_SCHEDULE3";
BA_ "RID" SG_ 795 Start_Time_Hr3 "6676";
BA_ "GenSigSNA" SG_ 795 Start_Time_Hr3 "1Fh";
BA_ "GenSigSendType" SG_ 795 Start_Time_Hr3 1;
BA_ "FlexKomSigStartValue" SG_ 795 Start_Time_Hr3 "0000000000000000h";
BA_ "FlexKomSigStartPos" SG_ 795 Start_Time_Hr3 7;
BA_ "FlexKomSigName" SG_ 795 Start_Time_Hr3 "TBM_SCHEDULE3";
BA_ "FlexKomSigLaenge" SG_ 795 Start_Time_Hr3 64;
BA_ "FlexKomSID" SG_ 795 Start_Time_Hr3 3107;
BA_ "FlexKomIsMotorola" SG_ 795 Start_Time_Hr3 1;
BA_ "FlexKomComment" SG_ 795 Start_Time_Hr3 "TBM_SCHEDULE3";
BA_ "RID" SG_ 795 Start_Time_Min3 "6613";
BA_ "GenSigSNA" SG_ 795 Start_Time_Min3 "Fh";
BA_ "GenSigSendType" SG_ 795 Start_Time_Min3 1;
BA_ "FlexKomSigStartValue" SG_ 795 Start_Time_Min3 "0000000000000000h";
BA_ "FlexKomSigStartPos" SG_ 795 Start_Time_Min3 7;
BA_ "FlexKomSigName" SG_ 795 Start_Time_Min3 "TBM_SCHEDULE3";
BA_ "FlexKomSigLaenge" SG_ 795 Start_Time_Min3 64;
BA_ "FlexKomSID" SG_ 795 Start_Time_Min3 3107;
BA_ "FlexKomIsMotorola" SG_ 795 Start_Time_Min3 1;
BA_ "FlexKomComment" SG_ 795 Start_Time_Min3 "TBM_SCHEDULE3";
BA_ "RID" SG_ 795 Submit_Schedule3 "6609";
BA_ "GenSigSNA" SG_ 795 Submit_Schedule3 "0h";
BA_ "GenSigSendType" SG_ 795 Submit_Schedule3 1;
BA_ "FlexKomSigStartValue" SG_ 795 Submit_Schedule3 "0000000000000000h";
BA_ "FlexKomSigStartPos" SG_ 795 Submit_Schedule3 7;
BA_ "FlexKomSigName" SG_ 795 Submit_Schedule3 "TBM_SCHEDULE3";
BA_ "FlexKomSigLaenge" SG_ 795 Submit_Schedule3 64;
BA_ "FlexKomSID" SG_ 795 Submit_Schedule3 3107;
BA_ "FlexKomIsMotorola" SG_ 795 Submit_Schedule3 1;
BA_ "FlexKomComment" SG_ 795 Submit_Schedule3 "TBM_SCHEDULE3";
BA_ "GenSigStartValue" SG_ 171 CRC_TCM_A7 255;
BA_ "GenSigSNA" SG_ 171 CRC_TCM_A7 "FFh";
BA_ "GenSigCycleTime" SG_ 171 CRC_TCM_A7 20;
BA_ "FlexKomSigStartValue" SG_ 171 CRC_TCM_A7 "0FFF0F0F000000FFh";
BA_ "FlexKomSigStartPos" SG_ 171 CRC_TCM_A7 7;
BA_ "FlexKomSigName" SG_ 171 CRC_TCM_A7 "TCM_A7_PKT";
BA_ "FlexKomSigLaenge" SG_ 171 CRC_TCM_A7 64;
BA_ "FlexKomSID" SG_ 171 CRC_TCM_A7 1613;
BA_ "FlexKomIsMotorola" SG_ 171 CRC_TCM_A7 1;
BA_ "FlexKomComment" SG_ 171 CRC_TCM_A7 "Transmission message A7 packet";
BA_ "GenSigStartValue" SG_ 171 CurrentGear 15;
BA_ "GenSigSNA" SG_ 171 CurrentGear "Fh";
BA_ "GenSigCycleTime" SG_ 171 CurrentGear 20;
BA_ "FlexKomSigStartValue" SG_ 171 CurrentGear "0FFF0F0F000000FFh";
BA_ "FlexKomSigStartPos" SG_ 171 CurrentGear 7;
BA_ "FlexKomSigName" SG_ 171 CurrentGear "TCM_A7_PKT";
BA_ "FlexKomSigLaenge" SG_ 171 CurrentGear 64;
BA_ "FlexKomSID" SG_ 171 CurrentGear 1613;
BA_ "FlexKomIsMotorola" SG_ 171 CurrentGear 1;
BA_ "FlexKomComment" SG_ 171 CurrentGear "Transmission message A7 packet";
BA_ "GenSigTimeout_IC" SG_ 171 CurrentGearForDisplay 210;
BA_ "GenSigSNA" SG_ 171 CurrentGearForDisplay "Fh";
BA_ "GenSigCycleTime" SG_ 171 CurrentGearForDisplay 20;
BA_ "FlexKomSigStartValue" SG_ 171 CurrentGearForDisplay "0FFF0F0F000000FFh";
BA_ "FlexKomSigStartPos" SG_ 171 CurrentGearForDisplay 7;
BA_ "FlexKomSigName" SG_ 171 CurrentGearForDisplay "TCM_A7_PKT";
BA_ "FlexKomSigLaenge" SG_ 171 CurrentGearForDisplay 64;
BA_ "FlexKomSID" SG_ 171 CurrentGearForDisplay 1613;
BA_ "FlexKomIsMotorola" SG_ 171 CurrentGearForDisplay 1;
BA_ "FlexKomComment" SG_ 171 CurrentGearForDisplay "Transmission message A7 packet";
BA_ "GenSigSNA" SG_ 171 EngShutOffRq_TCM "0h";
BA_ "GenSigCycleTime" SG_ 171 EngShutOffRq_TCM 20;
BA_ "FlexKomSigStartValue" SG_ 171 EngShutOffRq_TCM "0FFF0F0F000000FFh";
BA_ "FlexKomSigStartPos" SG_ 171 EngShutOffRq_TCM 7;
BA_ "FlexKomSigName" SG_ 171 EngShutOffRq_TCM "TCM_A7_PKT";
BA_ "FlexKomSigLaenge" SG_ 171 EngShutOffRq_TCM 64;
BA_ "FlexKomSID" SG_ 171 EngShutOffRq_TCM 1613;
BA_ "FlexKomIsMotorola" SG_ 171 EngShutOffRq_TCM 1;
BA_ "FlexKomComment" SG_ 171 EngShutOffRq_TCM "Transmission message A7 packet";
BA_ "GenSigSNA" SG_ 171 MC_TCM_A7 "0h";
BA_ "GenSigCycleTime" SG_ 171 MC_TCM_A7 20;
BA_ "FlexKomSigStartValue" SG_ 171 MC_TCM_A7 "0FFF0F0F000000FFh";
BA_ "FlexKomSigStartPos" SG_ 171 MC_TCM_A7 7;
BA_ "FlexKomSigName" SG_ 171 MC_TCM_A7 "TCM_A7_PKT";
BA_ "FlexKomSigLaenge" SG_ 171 MC_TCM_A7 64;
BA_ "FlexKomSID" SG_ 171 MC_TCM_A7 1613;
BA_ "FlexKomIsMotorola" SG_ 171 MC_TCM_A7 1;
BA_ "FlexKomComment" SG_ 171 MC_TCM_A7 "Transmission message A7 packet";
BA_ "RID" SG_ 171 TX_WARN2 "2157";
BA_ "GenSigTimeout_IC" SG_ 171 TX_WARN2 210;
BA_ "GenSigTimeout_CBC" SG_ 171 TX_WARN2 210;
BA_ "GenSigSNA" SG_ 171 TX_WARN2 "FFh";
BA_ "GenSigCycleTime" SG_ 171 TX_WARN2 20;
BA_ "FlexKomSigStartValue" SG_ 171 TX_WARN2 "0FFF0F0F000000FFh";
BA_ "FlexKomSigStartPos" SG_ 171 TX_WARN2 7;
BA_ "FlexKomSigName" SG_ 171 TX_WARN2 "TCM_A7_PKT";
BA_ "FlexKomSigLaenge" SG_ 171 TX_WARN2 64;
BA_ "FlexKomSID" SG_ 171 TX_WARN2 1613;
BA_ "FlexKomIsMotorola" SG_ 171 TX_WARN2 1;
BA_ "FlexKomComment" SG_ 171 TX_WARN2 "Transmission message A7 packet";
BA_ "GenSigStartValue" SG_ 171 TargetGear 15;
BA_ "GenSigSNA" SG_ 171 TargetGear "Fh";
BA_ "GenSigCycleTime" SG_ 171 TargetGear 20;
BA_ "FlexKomSigStartValue" SG_ 171 TargetGear "0FFF0F0F000000FFh";
BA_ "FlexKomSigStartPos" SG_ 171 TargetGear 7;
BA_ "FlexKomSigName" SG_ 171 TargetGear "TCM_A7_PKT";
BA_ "FlexKomSigLaenge" SG_ 171 TargetGear 64;
BA_ "FlexKomSID" SG_ 171 TargetGear 1613;
BA_ "FlexKomIsMotorola" SG_ 171 TargetGear 1;
BA_ "FlexKomComment" SG_ 171 TargetGear "Transmission message A7 packet";
BA_ "GenSigSNA" SG_ 171 WarmUpRq_NotAchieved "0h";
BA_ "GenSigCycleTime" SG_ 171 WarmUpRq_NotAchieved 20;
BA_ "FlexKomSigStartValue" SG_ 171 WarmUpRq_NotAchieved "0FFF0F0F000000FFh";
BA_ "FlexKomSigStartPos" SG_ 171 WarmUpRq_NotAchieved 7;
BA_ "FlexKomSigName" SG_ 171 WarmUpRq_NotAchieved "TCM_A7_PKT";
BA_ "FlexKomSigLaenge" SG_ 171 WarmUpRq_NotAchieved 64;
BA_ "FlexKomSID" SG_ 171 WarmUpRq_NotAchieved 1613;
BA_ "FlexKomIsMotorola" SG_ 171 WarmUpRq_NotAchieved 1;
BA_ "FlexKomComment" SG_ 171 WarmUpRq_NotAchieved "Transmission message A7 packet";
BA_ "GenSigSNA" SG_ 945 TCM_APPL1 "0h";
BA_ "GenSigSendType" SG_ 945 TCM_APPL1 1;
BA_ "FlexKomSigStartValue" SG_ 945 TCM_APPL1 "0000000000000000h";
BA_ "FlexKomSigStartPos" SG_ 945 TCM_APPL1 7;
BA_ "FlexKomSigName" SG_ 945 TCM_APPL1 "TCM_APPL1";
BA_ "FlexKomSigLaenge" SG_ 945 TCM_APPL1 64;
BA_ "FlexKomSID" SG_ 945 TCM_APPL1 778;
BA_ "FlexKomIsMotorola" SG_ 945 TCM_APPL1 1;
BA_ "FlexKomComment" SG_ 945 TCM_APPL1 "CCP from transmission";
BA_ "GenSigSNA" SG_ 944 TCM_APPL2 "0h";
BA_ "GenSigSendType" SG_ 944 TCM_APPL2 1;
BA_ "FlexKomSigStartValue" SG_ 944 TCM_APPL2 "0000000000000000h";
BA_ "FlexKomSigStartPos" SG_ 944 TCM_APPL2 7;
BA_ "FlexKomSigName" SG_ 944 TCM_APPL2 "TCM_APPL2";
BA_ "FlexKomSigLaenge" SG_ 944 TCM_APPL2 64;
BA_ "FlexKomSID" SG_ 944 TCM_APPL2 1178;
BA_ "FlexKomIsMotorola" SG_ 944 TCM_APPL2 1;
BA_ "FlexKomComment" SG_ 944 TCM_APPL2 "CCP to transmission";
BA_ "GenSigSNA" SG_ 946 TCM_APPL3 "0h";
BA_ "GenSigSendType" SG_ 946 TCM_APPL3 1;
BA_ "FlexKomSigStartValue" SG_ 946 TCM_APPL3 "0000000000000000h";
BA_ "FlexKomSigStartPos" SG_ 946 TCM_APPL3 7;
BA_ "FlexKomSigName" SG_ 946 TCM_APPL3 "TCM_APPL3";
BA_ "FlexKomSigLaenge" SG_ 946 TCM_APPL3 64;
BA_ "FlexKomSID" SG_ 946 TCM_APPL3 1179;
BA_ "FlexKomIsMotorola" SG_ 946 TCM_APPL3 1;
BA_ "FlexKomComment" SG_ 946 TCM_APPL3 "CCP from transmission";
BA_ "GenSigStartValue" SG_ 179 CRC_TCM_ENG_SPD 255;
BA_ "GenSigSNA" SG_ 179 CRC_TCM_ENG_SPD "FFh";
BA_ "GenSigCycleTime" SG_ 179 CRC_TCM_ENG_SPD 20;
BA_ "FlexKomSigStartValue" SG_ 179 CRC_TCM_ENG_SPD "0000FFFF000000FFh";
BA_ "FlexKomSigStartPos" SG_ 179 CRC_TCM_ENG_SPD 7;
BA_ "FlexKomSigName" SG_ 179 CRC_TCM_ENG_SPD "TCM_ENG_SPD_PKT";
BA_ "FlexKomSigLaenge" SG_ 179 CRC_TCM_ENG_SPD 64;
BA_ "FlexKomSID" SG_ 179 CRC_TCM_ENG_SPD 2772;
BA_ "FlexKomIsMotorola" SG_ 179 CRC_TCM_ENG_SPD 1;
BA_ "FlexKomComment" SG_ 179 CRC_TCM_ENG_SPD "TCM Engine Speed Packet";
BA_ "GenSigSNA" SG_ 179 DriveLineRatio "3FFFh";
BA_ "GenSigCycleTime" SG_ 179 DriveLineRatio 20;
BA_ "FlexKomSigStartValue" SG_ 179 DriveLineRatio "0000FFFF000000FFh";
BA_ "FlexKomSigStartPos" SG_ 179 DriveLineRatio 7;
BA_ "FlexKomSigName" SG_ 179 DriveLineRatio "TCM_ENG_SPD_PKT";
BA_ "FlexKomSigLaenge" SG_ 179 DriveLineRatio 64;
BA_ "FlexKomSID" SG_ 179 DriveLineRatio 2772;
BA_ "FlexKomIsMotorola" SG_ 179 DriveLineRatio 1;
BA_ "FlexKomComment" SG_ 179 DriveLineRatio "TCM Engine Speed Packet";
BA_ "GenSigSNA" SG_ 179 MC_TCM_ENG_SPD "0h";
BA_ "GenSigCycleTime" SG_ 179 MC_TCM_ENG_SPD 20;
BA_ "FlexKomSigStartValue" SG_ 179 MC_TCM_ENG_SPD "0000FFFF000000FFh";
BA_ "FlexKomSigStartPos" SG_ 179 MC_TCM_ENG_SPD 7;
BA_ "FlexKomSigName" SG_ 179 MC_TCM_ENG_SPD "TCM_ENG_SPD_PKT";
BA_ "FlexKomSigLaenge" SG_ 179 MC_TCM_ENG_SPD 64;
BA_ "FlexKomSID" SG_ 179 MC_TCM_ENG_SPD 2772;
BA_ "FlexKomIsMotorola" SG_ 179 MC_TCM_ENG_SPD 1;
BA_ "FlexKomComment" SG_ 179 MC_TCM_ENG_SPD "TCM Engine Speed Packet";
BA_ "GenSigStartValue" SG_ 179 OutputSpeed_2 65535;
BA_ "GenSigSNA" SG_ 179 OutputSpeed_2 "FFFFh";
BA_ "GenSigCycleTime" SG_ 179 OutputSpeed_2 20;
BA_ "FlexKomSigStartValue" SG_ 179 OutputSpeed_2 "0000FFFF000000FFh";
BA_ "FlexKomSigStartPos" SG_ 179 OutputSpeed_2 7;
BA_ "FlexKomSigName" SG_ 179 OutputSpeed_2 "TCM_ENG_SPD_PKT";
BA_ "FlexKomSigLaenge" SG_ 179 OutputSpeed_2 64;
BA_ "FlexKomSID" SG_ 179 OutputSpeed_2 2772;
BA_ "FlexKomIsMotorola" SG_ 179 OutputSpeed_2 1;
BA_ "FlexKomComment" SG_ 179 OutputSpeed_2 "TCM Engine Speed Packet";
BA_ "GenSigSNA" SG_ 179 TCM_Comm_Fail_ePT "0h";
BA_ "GenSigCycleTime" SG_ 179 TCM_Comm_Fail_ePT 20;
BA_ "FlexKomSigStartValue" SG_ 179 TCM_Comm_Fail_ePT "0000FFFF000000FFh";
BA_ "FlexKomSigStartPos" SG_ 179 TCM_Comm_Fail_ePT 7;
BA_ "FlexKomSigName" SG_ 179 TCM_Comm_Fail_ePT "TCM_ENG_SPD_PKT";
BA_ "FlexKomSigLaenge" SG_ 179 TCM_Comm_Fail_ePT 64;
BA_ "FlexKomSID" SG_ 179 TCM_Comm_Fail_ePT 2772;
BA_ "FlexKomIsMotorola" SG_ 179 TCM_Comm_Fail_ePT 1;
BA_ "FlexKomComment" SG_ 179 TCM_Comm_Fail_ePT "TCM Engine Speed Packet";
BA_ "GenSigSNA" SG_ 179 Trans_ESS_Inhibit "0h";
BA_ "GenSigCycleTime" SG_ 179 Trans_ESS_Inhibit 20;
BA_ "FlexKomSigStartValue" SG_ 179 Trans_ESS_Inhibit "0000FFFF000000FFh";
BA_ "FlexKomSigStartPos" SG_ 179 Trans_ESS_Inhibit 7;
BA_ "FlexKomSigName" SG_ 179 Trans_ESS_Inhibit "TCM_ENG_SPD_PKT";
BA_ "FlexKomSigLaenge" SG_ 179 Trans_ESS_Inhibit 64;
BA_ "FlexKomSID" SG_ 179 Trans_ESS_Inhibit 2772;
BA_ "FlexKomIsMotorola" SG_ 179 Trans_ESS_Inhibit 1;
BA_ "FlexKomComment" SG_ 179 Trans_ESS_Inhibit "TCM Engine Speed Packet";
BA_ "GenSigSNA" SG_ 149 CODE_CLR_TCM "0h";
BA_ "GenSigCycleTime" SG_ 149 CODE_CLR_TCM 20;
BA_ "FlexKomSigStartValue" SG_ 149 CODE_CLR_TCM "07FF001FFF00FFh";
BA_ "FlexKomSigStartPos" SG_ 149 CODE_CLR_TCM 7;
BA_ "FlexKomSigName" SG_ 149 CODE_CLR_TCM "ENG_TRQ_PKT";
BA_ "FlexKomSigLaenge" SG_ 149 CODE_CLR_TCM 56;
BA_ "FlexKomSID" SG_ 149 CODE_CLR_TCM 788;
BA_ "FlexKomIsMotorola" SG_ 149 CODE_CLR_TCM 1;
BA_ "FlexKomComment" SG_ 149 CODE_CLR_TCM "Engine torque packet for all transmissions";
BA_ "GenSigStartValue" SG_ 149 CRC_TCM_ENG_TRQ 255;
BA_ "GenSigSNA" SG_ 149 CRC_TCM_ENG_TRQ "FFh";
BA_ "GenSigCycleTime" SG_ 149 CRC_TCM_ENG_TRQ 20;
BA_ "FlexKomSigStartValue" SG_ 149 CRC_TCM_ENG_TRQ "07FF001FFF00FFh";
BA_ "FlexKomSigStartPos" SG_ 149 CRC_TCM_ENG_TRQ 7;
BA_ "FlexKomSigName" SG_ 149 CRC_TCM_ENG_TRQ "ENG_TRQ_PKT";
BA_ "FlexKomSigLaenge" SG_ 149 CRC_TCM_ENG_TRQ 56;
BA_ "FlexKomSID" SG_ 149 CRC_TCM_ENG_TRQ 788;
BA_ "FlexKomIsMotorola" SG_ 149 CRC_TCM_ENG_TRQ 1;
BA_ "FlexKomComment" SG_ 149 CRC_TCM_ENG_TRQ "Engine torque packet for all transmissions";
BA_ "GenSigSNA" SG_ 149 MC_TCM_ENG_TRQ "0h";
BA_ "GenSigCycleTime" SG_ 149 MC_TCM_ENG_TRQ 20;
BA_ "FlexKomSigStartValue" SG_ 149 MC_TCM_ENG_TRQ "07FF001FFF00FFh";
BA_ "FlexKomSigStartPos" SG_ 149 MC_TCM_ENG_TRQ 7;
BA_ "FlexKomSigName" SG_ 149 MC_TCM_ENG_TRQ "ENG_TRQ_PKT";
BA_ "FlexKomSigLaenge" SG_ 149 MC_TCM_ENG_TRQ 56;
BA_ "FlexKomSID" SG_ 149 MC_TCM_ENG_TRQ 788;
BA_ "FlexKomIsMotorola" SG_ 149 MC_TCM_ENG_TRQ 1;
BA_ "FlexKomComment" SG_ 149 MC_TCM_ENG_TRQ "Engine torque packet for all transmissions";
BA_ "GenSigSNA" SG_ 149 REPRGD_PFC_CLR_TCM "0h";
BA_ "GenSigCycleTime" SG_ 149 REPRGD_PFC_CLR_TCM 20;
BA_ "FlexKomSigStartValue" SG_ 149 REPRGD_PFC_CLR_TCM "07FF001FFF00FFh";
BA_ "FlexKomSigStartPos" SG_ 149 REPRGD_PFC_CLR_TCM 7;
BA_ "FlexKomSigName" SG_ 149 REPRGD_PFC_CLR_TCM "ENG_TRQ_PKT";
BA_ "FlexKomSigLaenge" SG_ 149 REPRGD_PFC_CLR_TCM 56;
BA_ "FlexKomSID" SG_ 149 REPRGD_PFC_CLR_TCM 788;
BA_ "FlexKomIsMotorola" SG_ 149 REPRGD_PFC_CLR_TCM 1;
BA_ "FlexKomComment" SG_ 149 REPRGD_PFC_CLR_TCM "Engine torque packet for all transmissions";
BA_ "GenSigStartValue" SG_ 149 Trans_Trq_Ratio 2047;
BA_ "GenSigSNA" SG_ 149 Trans_Trq_Ratio "7FFh";
BA_ "GenSigCycleTime" SG_ 149 Trans_Trq_Ratio 20;
BA_ "FlexKomSigStartValue" SG_ 149 Trans_Trq_Ratio "07FF001FFF00FFh";
BA_ "FlexKomSigStartPos" SG_ 149 Trans_Trq_Ratio 7;
BA_ "FlexKomSigName" SG_ 149 Trans_Trq_Ratio "ENG_TRQ_PKT";
BA_ "FlexKomSigLaenge" SG_ 149 Trans_Trq_Ratio 56;
BA_ "FlexKomSID" SG_ 149 Trans_Trq_Ratio 788;
BA_ "FlexKomIsMotorola" SG_ 149 Trans_Trq_Ratio 1;
BA_ "FlexKomComment" SG_ 149 Trans_Trq_Ratio "Engine torque packet for all transmissions";
BA_ "GenSigSNA" SG_ 149 TxIdleRq "FFh";
BA_ "GenSigCycleTime" SG_ 149 TxIdleRq 20;
BA_ "FlexKomSigStartValue" SG_ 149 TxIdleRq "07FF001FFF00FFh";
BA_ "FlexKomSigStartPos" SG_ 149 TxIdleRq 7;
BA_ "FlexKomSigName" SG_ 149 TxIdleRq "ENG_TRQ_PKT";
BA_ "FlexKomSigLaenge" SG_ 149 TxIdleRq 56;
BA_ "FlexKomSID" SG_ 149 TxIdleRq 788;
BA_ "FlexKomIsMotorola" SG_ 149 TxIdleRq 1;
BA_ "FlexKomComment" SG_ 149 TxIdleRq "Engine torque packet for all transmissions";
BA_ "GenSigStartValue" SG_ 55 CRC_TCM_EngTrq2 255;
BA_ "GenSigSNA" SG_ 55 CRC_TCM_EngTrq2 "FFh";
BA_ "GenSigCycleTime" SG_ 55 CRC_TCM_EngTrq2 10;
BA_ "FlexKomSigStartValue" SG_ 55 CRC_TCM_EngTrq2 "1FFF1FFF1FFF00FFh";
BA_ "FlexKomSigStartPos" SG_ 55 CRC_TCM_EngTrq2 7;
BA_ "FlexKomSigName" SG_ 55 CRC_TCM_EngTrq2 "TCM_EngTrq2_Pkt";
BA_ "FlexKomSigLaenge" SG_ 55 CRC_TCM_EngTrq2 64;
BA_ "FlexKomSID" SG_ 55 CRC_TCM_EngTrq2 1379;
BA_ "FlexKomIsMotorola" SG_ 55 CRC_TCM_EngTrq2 1;
BA_ "FlexKomComment" SG_ 55 CRC_TCM_EngTrq2 "Engine Torque Pkt";
BA_ "GenSigStartValue" SG_ 55 EngTrqRq 8191;
BA_ "GenSigSNA" SG_ 55 EngTrqRq "1FFFh";
BA_ "GenSigCycleTime" SG_ 55 EngTrqRq 10;
BA_ "FlexKomSigStartValue" SG_ 55 EngTrqRq "1FFF1FFF1FFF00FFh";
BA_ "FlexKomSigStartPos" SG_ 55 EngTrqRq 7;
BA_ "FlexKomSigName" SG_ 55 EngTrqRq "TCM_EngTrq2_Pkt";
BA_ "FlexKomSigLaenge" SG_ 55 EngTrqRq 64;
BA_ "FlexKomSID" SG_ 55 EngTrqRq 1379;
BA_ "FlexKomIsMotorola" SG_ 55 EngTrqRq 1;
BA_ "FlexKomComment" SG_ 55 EngTrqRq "Engine Torque Pkt";
BA_ "GenSigSNA" SG_ 55 MC_TCM_EngTrq2 "0h";
BA_ "GenSigCycleTime" SG_ 55 MC_TCM_EngTrq2 10;
BA_ "FlexKomSigStartValue" SG_ 55 MC_TCM_EngTrq2 "1FFF1FFF1FFF00FFh";
BA_ "FlexKomSigStartPos" SG_ 55 MC_TCM_EngTrq2 7;
BA_ "FlexKomSigName" SG_ 55 MC_TCM_EngTrq2 "TCM_EngTrq2_Pkt";
BA_ "FlexKomSigLaenge" SG_ 55 MC_TCM_EngTrq2 64;
BA_ "FlexKomSID" SG_ 55 MC_TCM_EngTrq2 1379;
BA_ "FlexKomIsMotorola" SG_ 55 MC_TCM_EngTrq2 1;
BA_ "FlexKomComment" SG_ 55 MC_TCM_EngTrq2 "Engine Torque Pkt";
BA_ "GenSigStartValue" SG_ 55 MaxTrqDes 8191;
BA_ "GenSigSNA" SG_ 55 MaxTrqDes "1FFFh";
BA_ "GenSigCycleTime" SG_ 55 MaxTrqDes 10;
BA_ "FlexKomSigStartValue" SG_ 55 MaxTrqDes "1FFF1FFF1FFF00FFh";
BA_ "FlexKomSigStartPos" SG_ 55 MaxTrqDes 7;
BA_ "FlexKomSigName" SG_ 55 MaxTrqDes "TCM_EngTrq2_Pkt";
BA_ "FlexKomSigLaenge" SG_ 55 MaxTrqDes 64;
BA_ "FlexKomSID" SG_ 55 MaxTrqDes 1379;
BA_ "FlexKomIsMotorola" SG_ 55 MaxTrqDes 1;
BA_ "FlexKomComment" SG_ 55 MaxTrqDes "Engine Torque Pkt";
BA_ "GenSigSNA" SG_ 55 TCM_ParkSL_Request "3h";
BA_ "GenSigCycleTime" SG_ 55 TCM_ParkSL_Request 10;
BA_ "FlexKomSigStartValue" SG_ 55 TCM_ParkSL_Request "1FFF1FFF1FFF00FFh";
BA_ "FlexKomSigStartPos" SG_ 55 TCM_ParkSL_Request 7;
BA_ "FlexKomSigName" SG_ 55 TCM_ParkSL_Request "TCM_EngTrq2_Pkt";
BA_ "FlexKomSigLaenge" SG_ 55 TCM_ParkSL_Request 64;
BA_ "FlexKomSID" SG_ 55 TCM_ParkSL_Request 1379;
BA_ "FlexKomIsMotorola" SG_ 55 TCM_ParkSL_Request 1;
BA_ "FlexKomComment" SG_ 55 TCM_ParkSL_Request "Engine Torque Pkt";
BA_ "GenSigSNA" SG_ 55 TrqCtrlModeReqSlow "3h";
BA_ "GenSigCycleTime" SG_ 55 TrqCtrlModeReqSlow 10;
BA_ "FlexKomSigStartValue" SG_ 55 TrqCtrlModeReqSlow "1FFF1FFF1FFF00FFh";
BA_ "FlexKomSigStartPos" SG_ 55 TrqCtrlModeReqSlow 7;
BA_ "FlexKomSigName" SG_ 55 TrqCtrlModeReqSlow "TCM_EngTrq2_Pkt";
BA_ "FlexKomSigLaenge" SG_ 55 TrqCtrlModeReqSlow 64;
BA_ "FlexKomSID" SG_ 55 TrqCtrlModeReqSlow 1379;
BA_ "FlexKomIsMotorola" SG_ 55 TrqCtrlModeReqSlow 1;
BA_ "FlexKomComment" SG_ 55 TrqCtrlModeReqSlow "Engine Torque Pkt";
BA_ "GenSigSNA" SG_ 55 TrqCtrlModeRq "7h";
BA_ "GenSigCycleTime" SG_ 55 TrqCtrlModeRq 10;
BA_ "FlexKomSigStartValue" SG_ 55 TrqCtrlModeRq "1FFF1FFF1FFF00FFh";
BA_ "FlexKomSigStartPos" SG_ 55 TrqCtrlModeRq 7;
BA_ "FlexKomSigName" SG_ 55 TrqCtrlModeRq "TCM_EngTrq2_Pkt";
BA_ "FlexKomSigLaenge" SG_ 55 TrqCtrlModeRq 64;
BA_ "FlexKomSID" SG_ 55 TrqCtrlModeRq 1379;
BA_ "FlexKomIsMotorola" SG_ 55 TrqCtrlModeRq 1;
BA_ "FlexKomComment" SG_ 55 TrqCtrlModeRq "Engine Torque Pkt";
BA_ "GenSigSNA" SG_ 872 TCM_HSA "0h";
BA_ "GenSigSendType" SG_ 872 TCM_HSA 1;
BA_ "FlexKomSigStartValue" SG_ 872 TCM_HSA "0000000000000000h";
BA_ "FlexKomSigStartPos" SG_ 872 TCM_HSA 7;
BA_ "FlexKomSigName" SG_ 872 TCM_HSA "TCM_HSA";
BA_ "FlexKomSigLaenge" SG_ 872 TCM_HSA 64;
BA_ "FlexKomSID" SG_ 872 TCM_HSA 799;
BA_ "FlexKomIsMotorola" SG_ 872 TCM_HSA 1;
BA_ "FlexKomComment" SG_ 872 TCM_HSA "Manual control at test bench";
BA_ "GenSigSNA" SG_ 888 TCM_HSB "0h";
BA_ "GenSigSendType" SG_ 888 TCM_HSB 1;
BA_ "FlexKomSigStartValue" SG_ 888 TCM_HSB "0000000000000000h";
BA_ "FlexKomSigStartPos" SG_ 888 TCM_HSB 7;
BA_ "FlexKomSigName" SG_ 888 TCM_HSB "TCM_HSB";
BA_ "FlexKomSigLaenge" SG_ 888 TCM_HSB 64;
BA_ "FlexKomSID" SG_ 888 TCM_HSB 800;
BA_ "FlexKomIsMotorola" SG_ 888 TCM_HSB 1;
BA_ "FlexKomComment" SG_ 888 TCM_HSB "Manual control at test bench";
BA_ "GenSigSNA" SG_ 904 TCM_HSC "0h";
BA_ "GenSigSendType" SG_ 904 TCM_HSC 1;
BA_ "FlexKomSigStartValue" SG_ 904 TCM_HSC "0000000000000000h";
BA_ "FlexKomSigStartPos" SG_ 904 TCM_HSC 7;
BA_ "FlexKomSigName" SG_ 904 TCM_HSC "TCM_HSC";
BA_ "FlexKomSigLaenge" SG_ 904 TCM_HSC 64;
BA_ "FlexKomSID" SG_ 904 TCM_HSC 801;
BA_ "FlexKomIsMotorola" SG_ 904 TCM_HSC 1;
BA_ "FlexKomComment" SG_ 904 TCM_HSC "Manual control at test bench";
BA_ "GenSigSNA" SG_ 920 TCM_HSD "0h";
BA_ "GenSigSendType" SG_ 920 TCM_HSD 1;
BA_ "FlexKomSigStartValue" SG_ 920 TCM_HSD "0000000000000000h";
BA_ "FlexKomSigStartPos" SG_ 920 TCM_HSD 7;
BA_ "FlexKomSigName" SG_ 920 TCM_HSD "TCM_HSD";
BA_ "FlexKomSigLaenge" SG_ 920 TCM_HSD 64;
BA_ "FlexKomSID" SG_ 920 TCM_HSD 802;
BA_ "FlexKomIsMotorola" SG_ 920 TCM_HSD 1;
BA_ "FlexKomComment" SG_ 920 TCM_HSD "Manual control at test bench";
BA_ "RID" SG_ 808 TGW_GrpNum_IC "1203";
BA_ "GenSigSNA" SG_ 808 TGW_GrpNum_IC "0h";
BA_ "GenSigSendType" SG_ 808 TGW_GrpNum_IC 5;
BA_ "GenSigCycleTime" SG_ 808 TGW_GrpNum_IC 1000;
BA_ "FlexKomSigStartValue" SG_ 808 TGW_GrpNum_IC "0000000000000000h";
BA_ "FlexKomSigStartPos" SG_ 808 TGW_GrpNum_IC 7;
BA_ "FlexKomSigName" SG_ 808 TGW_GrpNum_IC "TGW_DATA_IC";
BA_ "FlexKomSigLaenge" SG_ 808 TGW_GrpNum_IC 64;
BA_ "FlexKomSID" SG_ 808 TGW_GrpNum_IC 985;
BA_ "FlexKomIsMotorola" SG_ 808 TGW_GrpNum_IC 1;
BA_ "FlexKomComment" SG_ 808 TGW_GrpNum_IC "TGW text data transfer to IC";
BA_ "RID" SG_ 808 TGW_GrpTyp_IC "1077";
BA_ "GenSigSNA" SG_ 808 TGW_GrpTyp_IC "3Fh";
BA_ "GenSigSendType" SG_ 808 TGW_GrpTyp_IC 5;
BA_ "GenSigCycleTime" SG_ 808 TGW_GrpTyp_IC 1000;
BA_ "FlexKomSigStartValue" SG_ 808 TGW_GrpTyp_IC "0000000000000000h";
BA_ "FlexKomSigStartPos" SG_ 808 TGW_GrpTyp_IC 7;
BA_ "FlexKomSigName" SG_ 808 TGW_GrpTyp_IC "TGW_DATA_IC";
BA_ "FlexKomSigLaenge" SG_ 808 TGW_GrpTyp_IC 64;
BA_ "FlexKomSID" SG_ 808 TGW_GrpTyp_IC 985;
BA_ "FlexKomIsMotorola" SG_ 808 TGW_GrpTyp_IC 1;
BA_ "FlexKomComment" SG_ 808 TGW_GrpTyp_IC "TGW text data transfer to IC";
BA_ "RID" SG_ 808 TGW_HiGrpMark_IC "1243";
BA_ "GenSigSNA" SG_ 808 TGW_HiGrpMark_IC "0h";
BA_ "GenSigSendType" SG_ 808 TGW_HiGrpMark_IC 5;
BA_ "GenSigCycleTime" SG_ 808 TGW_HiGrpMark_IC 1000;
BA_ "FlexKomSigStartValue" SG_ 808 TGW_HiGrpMark_IC "0000000000000000h";
BA_ "FlexKomSigStartPos" SG_ 808 TGW_HiGrpMark_IC 7;
BA_ "FlexKomSigName" SG_ 808 TGW_HiGrpMark_IC "TGW_DATA_IC";
BA_ "FlexKomSigLaenge" SG_ 808 TGW_HiGrpMark_IC 64;
BA_ "FlexKomSID" SG_ 808 TGW_HiGrpMark_IC 985;
BA_ "FlexKomIsMotorola" SG_ 808 TGW_HiGrpMark_IC 1;
BA_ "FlexKomComment" SG_ 808 TGW_HiGrpMark_IC "TGW text data transfer to IC";
BA_ "RID" SG_ 808 TGW_TEXT_IC "1125";
BA_ "GenSigSNA" SG_ 808 TGW_TEXT_IC "0h";
BA_ "GenSigSendType" SG_ 808 TGW_TEXT_IC 5;
BA_ "GenSigCycleTime" SG_ 808 TGW_TEXT_IC 1000;
BA_ "FlexKomSigStartValue" SG_ 808 TGW_TEXT_IC "0000000000000000h";
BA_ "FlexKomSigStartPos" SG_ 808 TGW_TEXT_IC 7;
BA_ "FlexKomSigName" SG_ 808 TGW_TEXT_IC "TGW_DATA_IC";
BA_ "FlexKomSigLaenge" SG_ 808 TGW_TEXT_IC 64;
BA_ "FlexKomSID" SG_ 808 TGW_TEXT_IC 985;
BA_ "FlexKomIsMotorola" SG_ 808 TGW_TEXT_IC 1;
BA_ "FlexKomComment" SG_ 808 TGW_TEXT_IC "TGW text data transfer to IC";
BA_ "RID" SG_ 662 STFASysEnableFault "6541";
BA_ "GenSigSNA" SG_ 662 STFASysEnableFault "0h";
BA_ "GenSigSendType" SG_ 662 STFASysEnableFault 5;
BA_ "GenSigCycleTime" SG_ 662 STFASysEnableFault 1000;
BA_ "FlexKomSigStartValue" SG_ 662 STFASysEnableFault "000000FFFFFFFFFFh";
BA_ "FlexKomSigStartPos" SG_ 662 STFASysEnableFault 7;
BA_ "FlexKomSigName" SG_ 662 STFASysEnableFault "TPM_A1_PKT";
BA_ "FlexKomSigLaenge" SG_ 662 STFASysEnableFault 64;
BA_ "FlexKomSID" SG_ 662 STFASysEnableFault 866;
BA_ "FlexKomIsMotorola" SG_ 662 STFASysEnableFault 1;
BA_ "FlexKomComment" SG_ 662 STFASysEnableFault "Tire Pressure Packet";
BA_ "RID" SG_ 662 TFASts_TPM "6478";
BA_ "GenSigTimeout_CBC" SG_ 662 TFASts_TPM 10500;
BA_ "GenSigSNA" SG_ 662 TFASts_TPM "0h";
BA_ "GenSigSendType" SG_ 662 TFASts_TPM 5;
BA_ "GenSigCycleTime" SG_ 662 TFASts_TPM 1000;
BA_ "FlexKomSigStartValue" SG_ 662 TFASts_TPM "000000FFFFFFFFFFh";
BA_ "FlexKomSigStartPos" SG_ 662 TFASts_TPM 7;
BA_ "FlexKomSigName" SG_ 662 TFASts_TPM "TPM_A1_PKT";
BA_ "FlexKomSigLaenge" SG_ 662 TFASts_TPM 64;
BA_ "FlexKomSID" SG_ 662 TFASts_TPM 866;
BA_ "FlexKomIsMotorola" SG_ 662 TFASts_TPM 1;
BA_ "FlexKomComment" SG_ 662 TFASts_TPM "Tire Pressure Packet";
BA_ "GenSigTimeout_ORC" SG_ 662 TPM_Chime_Rq 3500;
BA_ "GenSigTimeout_IC" SG_ 662 TPM_Chime_Rq 10500;
BA_ "GenSigSNA" SG_ 662 TPM_Chime_Rq "0h";
BA_ "GenSigSendType" SG_ 662 TPM_Chime_Rq 5;
BA_ "GenSigCycleTime" SG_ 662 TPM_Chime_Rq 1000;
BA_ "FlexKomSigStartValue" SG_ 662 TPM_Chime_Rq "000000FFFFFFFFFFh";
BA_ "FlexKomSigStartPos" SG_ 662 TPM_Chime_Rq 7;
BA_ "FlexKomSigName" SG_ 662 TPM_Chime_Rq "TPM_A1_PKT";
BA_ "FlexKomSigLaenge" SG_ 662 TPM_Chime_Rq 64;
BA_ "FlexKomSID" SG_ 662 TPM_Chime_Rq 866;
BA_ "FlexKomIsMotorola" SG_ 662 TPM_Chime_Rq 1;
BA_ "FlexKomComment" SG_ 662 TPM_Chime_Rq "Tire Pressure Packet";
BA_ "GenSigTimeout_TBM" SG_ 662 TPM_HazardFlash 10500;
BA_ "GenSigTimeout_ORC" SG_ 662 TPM_HazardFlash 3500;
BA_ "GenSigTimeout_IC" SG_ 662 TPM_HazardFlash 5500;
BA_ "GenSigTimeout_ETM" SG_ 662 TPM_HazardFlash 10500;
BA_ "GenSigTimeout_CBC" SG_ 662 TPM_HazardFlash 10500;
BA_ "GenSigSNA" SG_ 662 TPM_HazardFlash "0h";
BA_ "GenSigSendType" SG_ 662 TPM_HazardFlash 5;
BA_ "GenSigCycleTime" SG_ 662 TPM_HazardFlash 1000;
BA_ "FlexKomSigStartValue" SG_ 662 TPM_HazardFlash "000000FFFFFFFFFFh";
BA_ "FlexKomSigStartPos" SG_ 662 TPM_HazardFlash 7;
BA_ "FlexKomSigName" SG_ 662 TPM_HazardFlash "TPM_A1_PKT";
BA_ "FlexKomSigLaenge" SG_ 662 TPM_HazardFlash 64;
BA_ "FlexKomSID" SG_ 662 TPM_HazardFlash 866;
BA_ "FlexKomIsMotorola" SG_ 662 TPM_HazardFlash 1;
BA_ "FlexKomComment" SG_ 662 TPM_HazardFlash "Tire Pressure Packet";
BA_ "GenSigTimeout_TBM" SG_ 662 TPM_HornChirp 10500;
BA_ "GenSigTimeout_ORC" SG_ 662 TPM_HornChirp 3500;
BA_ "GenSigTimeout_IC" SG_ 662 TPM_HornChirp 5500;
BA_ "GenSigTimeout_ETM" SG_ 662 TPM_HornChirp 10500;
BA_ "GenSigTimeout_CBC" SG_ 662 TPM_HornChirp 10500;
BA_ "GenSigSNA" SG_ 662 TPM_HornChirp "3h";
BA_ "GenSigSendType" SG_ 662 TPM_HornChirp 5;
BA_ "GenSigCycleTime" SG_ 662 TPM_HornChirp 1000;
BA_ "FlexKomSigStartValue" SG_ 662 TPM_HornChirp "000000FFFFFFFFFFh";
BA_ "FlexKomSigStartPos" SG_ 662 TPM_HornChirp 7;
BA_ "FlexKomSigName" SG_ 662 TPM_HornChirp "TPM_A1_PKT";
BA_ "FlexKomSigLaenge" SG_ 662 TPM_HornChirp 64;
BA_ "FlexKomSID" SG_ 662 TPM_HornChirp 866;
BA_ "FlexKomIsMotorola" SG_ 662 TPM_HornChirp 1;
BA_ "FlexKomComment" SG_ 662 TPM_HornChirp "Tire Pressure Packet";
BA_ "GenSigTimeout_TBM" SG_ 662 TPM_IndLmp_On_Rq 10500;
BA_ "GenSigTimeout_ORC" SG_ 662 TPM_IndLmp_On_Rq 3500;
BA_ "GenSigTimeout_IC" SG_ 662 TPM_IndLmp_On_Rq 5500;
BA_ "GenSigTimeout_ETM" SG_ 662 TPM_IndLmp_On_Rq 10500;
BA_ "GenSigSNA" SG_ 662 TPM_IndLmp_On_Rq "3h";
BA_ "GenSigSendType" SG_ 662 TPM_IndLmp_On_Rq 5;
BA_ "GenSigCycleTime" SG_ 662 TPM_IndLmp_On_Rq 1000;
BA_ "FlexKomSigStartValue" SG_ 662 TPM_IndLmp_On_Rq "000000FFFFFFFFFFh";
BA_ "FlexKomSigStartPos" SG_ 662 TPM_IndLmp_On_Rq 7;
BA_ "FlexKomSigName" SG_ 662 TPM_IndLmp_On_Rq "TPM_A1_PKT";
BA_ "FlexKomSigLaenge" SG_ 662 TPM_IndLmp_On_Rq 64;
BA_ "FlexKomSID" SG_ 662 TPM_IndLmp_On_Rq 866;
BA_ "FlexKomIsMotorola" SG_ 662 TPM_IndLmp_On_Rq 1;
BA_ "FlexKomComment" SG_ 662 TPM_IndLmp_On_Rq "Tire Pressure Packet";
BA_ "GenSigTimeout_ORC" SG_ 662 TPM_Sys_Stat 3500;
BA_ "GenSigTimeout_IC" SG_ 662 TPM_Sys_Stat 10500;
BA_ "GenSigSNA" SG_ 662 TPM_Sys_Stat "7h";
BA_ "GenSigSendType" SG_ 662 TPM_Sys_Stat 5;
BA_ "GenSigCycleTime" SG_ 662 TPM_Sys_Stat 1000;
BA_ "FlexKomSigStartValue" SG_ 662 TPM_Sys_Stat "000000FFFFFFFFFFh";
BA_ "FlexKomSigStartPos" SG_ 662 TPM_Sys_Stat 7;
BA_ "FlexKomSigName" SG_ 662 TPM_Sys_Stat "TPM_A1_PKT";
BA_ "FlexKomSigLaenge" SG_ 662 TPM_Sys_Stat 64;
BA_ "FlexKomSID" SG_ 662 TPM_Sys_Stat 866;
BA_ "FlexKomIsMotorola" SG_ 662 TPM_Sys_Stat 1;
BA_ "FlexKomComment" SG_ 662 TPM_Sys_Stat "Tire Pressure Packet";
BA_ "GenSigTimeout_ORC" SG_ 662 TireFL 3500;
BA_ "GenSigTimeout_IC" SG_ 662 TireFL 10500;
BA_ "GenSigTimeout_ETM" SG_ 662 TireFL 10500;
BA_ "GenSigSNA" SG_ 662 TireFL "3h";
BA_ "GenSigSendType" SG_ 662 TireFL 5;
BA_ "GenSigCycleTime" SG_ 662 TireFL 1000;
BA_ "FlexKomSigStartValue" SG_ 662 TireFL "000000FFFFFFFFFFh";
BA_ "FlexKomSigStartPos" SG_ 662 TireFL 7;
BA_ "FlexKomSigName" SG_ 662 TireFL "TPM_A1_PKT";
BA_ "FlexKomSigLaenge" SG_ 662 TireFL 64;
BA_ "FlexKomSID" SG_ 662 TireFL 866;
BA_ "FlexKomIsMotorola" SG_ 662 TireFL 1;
BA_ "FlexKomComment" SG_ 662 TireFL "Tire Pressure Packet";
BA_ "GenSigTimeout_ORC" SG_ 662 TireFR 3500;
BA_ "GenSigTimeout_IC" SG_ 662 TireFR 10500;
BA_ "GenSigTimeout_ETM" SG_ 662 TireFR 10500;
BA_ "GenSigSNA" SG_ 662 TireFR "3h";
BA_ "GenSigSendType" SG_ 662 TireFR 5;
BA_ "GenSigCycleTime" SG_ 662 TireFR 1000;
BA_ "FlexKomSigStartValue" SG_ 662 TireFR "000000FFFFFFFFFFh";
BA_ "FlexKomSigStartPos" SG_ 662 TireFR 7;
BA_ "FlexKomSigName" SG_ 662 TireFR "TPM_A1_PKT";
BA_ "FlexKomSigLaenge" SG_ 662 TireFR 64;
BA_ "FlexKomSID" SG_ 662 TireFR 866;
BA_ "FlexKomIsMotorola" SG_ 662 TireFR 1;
BA_ "FlexKomComment" SG_ 662 TireFR "Tire Pressure Packet";
BA_ "GenSigTimeout_TBM" SG_ 662 TirePressFL 10500;
BA_ "GenSigTimeout_ORC" SG_ 662 TirePressFL 3500;
BA_ "GenSigTimeout_IC" SG_ 662 TirePressFL 10500;
BA_ "GenSigStartValue" SG_ 662 TirePressFL 255;
BA_ "GenSigSNA" SG_ 662 TirePressFL "FFh";
BA_ "GenSigSendType" SG_ 662 TirePressFL 5;
BA_ "GenSigCycleTime" SG_ 662 TirePressFL 1000;
BA_ "FlexKomSigStartValue" SG_ 662 TirePressFL "000000FFFFFFFFFFh";
BA_ "FlexKomSigStartPos" SG_ 662 TirePressFL 7;
BA_ "FlexKomSigName" SG_ 662 TirePressFL "TPM_A1_PKT";
BA_ "FlexKomSigLaenge" SG_ 662 TirePressFL 64;
BA_ "FlexKomSID" SG_ 662 TirePressFL 866;
BA_ "FlexKomIsMotorola" SG_ 662 TirePressFL 1;
BA_ "FlexKomComment" SG_ 662 TirePressFL "Tire Pressure Packet";
BA_ "GenSigTimeout_TBM" SG_ 662 TirePressFR 10500;
BA_ "GenSigTimeout_ORC" SG_ 662 TirePressFR 3500;
BA_ "GenSigTimeout_IC" SG_ 662 TirePressFR 10500;
BA_ "GenSigStartValue" SG_ 662 TirePressFR 255;
BA_ "GenSigSNA" SG_ 662 TirePressFR "FFh";
BA_ "GenSigSendType" SG_ 662 TirePressFR 5;
BA_ "GenSigCycleTime" SG_ 662 TirePressFR 1000;
BA_ "FlexKomSigStartValue" SG_ 662 TirePressFR "000000FFFFFFFFFFh";
BA_ "FlexKomSigStartPos" SG_ 662 TirePressFR 7;
BA_ "FlexKomSigName" SG_ 662 TirePressFR "TPM_A1_PKT";
BA_ "FlexKomSigLaenge" SG_ 662 TirePressFR 64;
BA_ "FlexKomSID" SG_ 662 TirePressFR 866;
BA_ "FlexKomIsMotorola" SG_ 662 TirePressFR 1;
BA_ "FlexKomComment" SG_ 662 TirePressFR "Tire Pressure Packet";
BA_ "GenSigTimeout_TBM" SG_ 662 TirePressRL 10500;
BA_ "GenSigTimeout_ORC" SG_ 662 TirePressRL 3500;
BA_ "GenSigTimeout_IC" SG_ 662 TirePressRL 10500;
BA_ "GenSigStartValue" SG_ 662 TirePressRL 255;
BA_ "GenSigSNA" SG_ 662 TirePressRL "FFh";
BA_ "GenSigSendType" SG_ 662 TirePressRL 5;
BA_ "GenSigCycleTime" SG_ 662 TirePressRL 1000;
BA_ "FlexKomSigStartValue" SG_ 662 TirePressRL "000000FFFFFFFFFFh";
BA_ "FlexKomSigStartPos" SG_ 662 TirePressRL 7;
BA_ "FlexKomSigName" SG_ 662 TirePressRL "TPM_A1_PKT";
BA_ "FlexKomSigLaenge" SG_ 662 TirePressRL 64;
BA_ "FlexKomSID" SG_ 662 TirePressRL 866;
BA_ "FlexKomIsMotorola" SG_ 662 TirePressRL 1;
BA_ "FlexKomComment" SG_ 662 TirePressRL "Tire Pressure Packet";
BA_ "GenSigTimeout_TBM" SG_ 662 TirePressRR 10500;
BA_ "GenSigTimeout_ORC" SG_ 662 TirePressRR 3500;
BA_ "GenSigTimeout_IC" SG_ 662 TirePressRR 10500;
BA_ "GenSigStartValue" SG_ 662 TirePressRR 255;
BA_ "GenSigSNA" SG_ 662 TirePressRR "FFh";
BA_ "GenSigSendType" SG_ 662 TirePressRR 5;
BA_ "GenSigCycleTime" SG_ 662 TirePressRR 1000;
BA_ "FlexKomSigStartValue" SG_ 662 TirePressRR "000000FFFFFFFFFFh";
BA_ "FlexKomSigStartPos" SG_ 662 TirePressRR 7;
BA_ "FlexKomSigName" SG_ 662 TirePressRR "TPM_A1_PKT";
BA_ "FlexKomSigLaenge" SG_ 662 TirePressRR 64;
BA_ "FlexKomSID" SG_ 662 TirePressRR 866;
BA_ "FlexKomIsMotorola" SG_ 662 TirePressRR 1;
BA_ "FlexKomComment" SG_ 662 TirePressRR "Tire Pressure Packet";
BA_ "GenSigTimeout_ORC" SG_ 662 TirePressSpr 3500;
BA_ "GenSigTimeout_IC" SG_ 662 TirePressSpr 10500;
BA_ "GenSigStartValue" SG_ 662 TirePressSpr 255;
BA_ "GenSigSNA" SG_ 662 TirePressSpr "FFh";
BA_ "GenSigSendType" SG_ 662 TirePressSpr 5;
BA_ "GenSigCycleTime" SG_ 662 TirePressSpr 1000;
BA_ "FlexKomSigStartValue" SG_ 662 TirePressSpr "000000FFFFFFFFFFh";
BA_ "FlexKomSigStartPos" SG_ 662 TirePressSpr 7;
BA_ "FlexKomSigName" SG_ 662 TirePressSpr "TPM_A1_PKT";
BA_ "FlexKomSigLaenge" SG_ 662 TirePressSpr 64;
BA_ "FlexKomSID" SG_ 662 TirePressSpr 866;
BA_ "FlexKomIsMotorola" SG_ 662 TirePressSpr 1;
BA_ "FlexKomComment" SG_ 662 TirePressSpr "Tire Pressure Packet";
BA_ "GenSigTimeout_ORC" SG_ 662 TireRL 3500;
BA_ "GenSigTimeout_IC" SG_ 662 TireRL 10500;
BA_ "GenSigTimeout_ETM" SG_ 662 TireRL 10500;
BA_ "GenSigSNA" SG_ 662 TireRL "3h";
BA_ "GenSigSendType" SG_ 662 TireRL 5;
BA_ "GenSigCycleTime" SG_ 662 TireRL 1000;
BA_ "FlexKomSigStartValue" SG_ 662 TireRL "000000FFFFFFFFFFh";
BA_ "FlexKomSigStartPos" SG_ 662 TireRL 7;
BA_ "FlexKomSigName" SG_ 662 TireRL "TPM_A1_PKT";
BA_ "FlexKomSigLaenge" SG_ 662 TireRL 64;
BA_ "FlexKomSID" SG_ 662 TireRL 866;
BA_ "FlexKomIsMotorola" SG_ 662 TireRL 1;
BA_ "FlexKomComment" SG_ 662 TireRL "Tire Pressure Packet";
BA_ "GenSigTimeout_ORC" SG_ 662 TireRR 3500;
BA_ "GenSigTimeout_IC" SG_ 662 TireRR 10500;
BA_ "GenSigTimeout_ETM" SG_ 662 TireRR 10500;
BA_ "GenSigSNA" SG_ 662 TireRR "3h";
BA_ "GenSigSendType" SG_ 662 TireRR 5;
BA_ "GenSigCycleTime" SG_ 662 TireRR 1000;
BA_ "FlexKomSigStartValue" SG_ 662 TireRR "000000FFFFFFFFFFh";
BA_ "FlexKomSigStartPos" SG_ 662 TireRR 7;
BA_ "FlexKomSigName" SG_ 662 TireRR "TPM_A1_PKT";
BA_ "FlexKomSigLaenge" SG_ 662 TireRR 64;
BA_ "FlexKomSID" SG_ 662 TireRR 866;
BA_ "FlexKomIsMotorola" SG_ 662 TireRR 1;
BA_ "FlexKomComment" SG_ 662 TireRR "Tire Pressure Packet";
BA_ "GenSigTimeout_ORC" SG_ 662 TireSpr 3500;
BA_ "GenSigTimeout_IC" SG_ 662 TireSpr 10500;
BA_ "GenSigSNA" SG_ 662 TireSpr "3h";
BA_ "GenSigSendType" SG_ 662 TireSpr 5;
BA_ "GenSigCycleTime" SG_ 662 TireSpr 1000;
BA_ "FlexKomSigStartValue" SG_ 662 TireSpr "000000FFFFFFFFFFh";
BA_ "FlexKomSigStartPos" SG_ 662 TireSpr 7;
BA_ "FlexKomSigName" SG_ 662 TireSpr "TPM_A1_PKT";
BA_ "FlexKomSigLaenge" SG_ 662 TireSpr 64;
BA_ "FlexKomSID" SG_ 662 TireSpr 866;
BA_ "FlexKomIsMotorola" SG_ 662 TireSpr 1;
BA_ "FlexKomComment" SG_ 662 TireSpr "Tire Pressure Packet";
BA_ "GenSigSNA" SG_ 526 CodeCheckSts "0h";
BA_ "GenSigSendType" SG_ 526 CodeCheckSts 1;
BA_ "FlexKomSigStartValue" SG_ 526 CodeCheckSts "000000800000h";
BA_ "FlexKomSigStartPos" SG_ 526 CodeCheckSts 7;
BA_ "FlexKomSigName" SG_ 526 CodeCheckSts "TRM_CodePkt";
BA_ "FlexKomSigLaenge" SG_ 526 CodeCheckSts 48;
BA_ "FlexKomSID" SG_ 526 CodeCheckSts 2329;
BA_ "FlexKomIsMotorola" SG_ 526 CodeCheckSts 1;
BA_ "FlexKomComment" SG_ 526 CodeCheckSts "Transponder code packet";
BA_ "GenSigSNA" SG_ 526 ControlEncoding "0h";
BA_ "GenSigSendType" SG_ 526 ControlEncoding 1;
BA_ "FlexKomSigStartValue" SG_ 526 ControlEncoding "000000800000h";
BA_ "FlexKomSigStartPos" SG_ 526 ControlEncoding 7;
BA_ "FlexKomSigName" SG_ 526 ControlEncoding "TRM_CodePkt";
BA_ "FlexKomSigLaenge" SG_ 526 ControlEncoding 48;
BA_ "FlexKomSID" SG_ 526 ControlEncoding 2329;
BA_ "FlexKomIsMotorola" SG_ 526 ControlEncoding 1;
BA_ "FlexKomComment" SG_ 526 ControlEncoding "Transponder code packet";
BA_ "GenSigSNA" SG_ 526 MiniCryptGCode "0h";
BA_ "GenSigSendType" SG_ 526 MiniCryptGCode 1;
BA_ "FlexKomSigStartValue" SG_ 526 MiniCryptGCode "000000800000h";
BA_ "FlexKomSigStartPos" SG_ 526 MiniCryptGCode 7;
BA_ "FlexKomSigName" SG_ 526 MiniCryptGCode "TRM_CodePkt";
BA_ "FlexKomSigLaenge" SG_ 526 MiniCryptGCode 48;
BA_ "FlexKomSID" SG_ 526 MiniCryptGCode 2329;
BA_ "FlexKomIsMotorola" SG_ 526 MiniCryptGCode 1;
BA_ "FlexKomComment" SG_ 526 MiniCryptGCode "Transponder code packet";
BA_ "GenSigSNA" SG_ 526 ProgrammedSts "0h";
BA_ "GenSigSendType" SG_ 526 ProgrammedSts 1;
BA_ "FlexKomSigStartValue" SG_ 526 ProgrammedSts "000000800000h";
BA_ "FlexKomSigStartPos" SG_ 526 ProgrammedSts 7;
BA_ "FlexKomSigName" SG_ 526 ProgrammedSts "TRM_CodePkt";
BA_ "FlexKomSigLaenge" SG_ 526 ProgrammedSts 48;
BA_ "FlexKomSID" SG_ 526 ProgrammedSts 2329;
BA_ "FlexKomIsMotorola" SG_ 526 ProgrammedSts 1;
BA_ "FlexKomComment" SG_ 526 ProgrammedSts "Transponder code packet";
BA_ "GenSigStartValue" SG_ 526 TxpFound 1;
BA_ "GenSigSNA" SG_ 526 TxpFound "1h";
BA_ "GenSigSendType" SG_ 526 TxpFound 1;
BA_ "FlexKomSigStartValue" SG_ 526 TxpFound "000000800000h";
BA_ "FlexKomSigStartPos" SG_ 526 TxpFound 7;
BA_ "FlexKomSigName" SG_ 526 TxpFound "TRM_CodePkt";
BA_ "FlexKomSigLaenge" SG_ 526 TxpFound 48;
BA_ "FlexKomSID" SG_ 526 TxpFound 2329;
BA_ "FlexKomIsMotorola" SG_ 526 TxpFound 1;
BA_ "FlexKomComment" SG_ 526 TxpFound "Transponder code packet";
BA_ "GenSigSNA" SG_ 526 TxpID "0h";
BA_ "GenSigSendType" SG_ 526 TxpID 1;
BA_ "FlexKomSigStartValue" SG_ 526 TxpID "000000800000h";
BA_ "FlexKomSigStartPos" SG_ 526 TxpID 7;
BA_ "FlexKomSigName" SG_ 526 TxpID "TRM_CodePkt";
BA_ "FlexKomSigLaenge" SG_ 526 TxpID 48;
BA_ "FlexKomSID" SG_ 526 TxpID 2329;
BA_ "FlexKomIsMotorola" SG_ 526 TxpID 1;
BA_ "FlexKomComment" SG_ 526 TxpID "Transponder code packet";
BA_ "GenSigSNA" SG_ 527 DATA1 "0h";
BA_ "GenSigSendType" SG_ 527 DATA1 1;
BA_ "FlexKomSigStartValue" SG_ 527 DATA1 "0000000000000000h";
BA_ "FlexKomSigStartPos" SG_ 527 DATA1 7;
BA_ "FlexKomSigName" SG_ 527 DATA1 "TRM_KeyPkt";
BA_ "FlexKomSigLaenge" SG_ 527 DATA1 64;
BA_ "FlexKomSID" SG_ 527 DATA1 2330;
BA_ "FlexKomIsMotorola" SG_ 527 DATA1 1;
BA_ "FlexKomComment" SG_ 527 DATA1 "Transponder key packet";
BA_ "GenSigSNA" SG_ 527 DATA2 "0h";
BA_ "GenSigSendType" SG_ 527 DATA2 1;
BA_ "FlexKomSigStartValue" SG_ 527 DATA2 "0000000000000000h";
BA_ "FlexKomSigStartPos" SG_ 527 DATA2 7;
BA_ "FlexKomSigName" SG_ 527 DATA2 "TRM_KeyPkt";
BA_ "FlexKomSigLaenge" SG_ 527 DATA2 64;
BA_ "FlexKomSID" SG_ 527 DATA2 2330;
BA_ "FlexKomIsMotorola" SG_ 527 DATA2 1;
BA_ "FlexKomComment" SG_ 527 DATA2 "Transponder key packet";
BA_ "GenSigSNA" SG_ 527 DATA3 "0h";
BA_ "GenSigSendType" SG_ 527 DATA3 1;
BA_ "FlexKomSigStartValue" SG_ 527 DATA3 "0000000000000000h";
BA_ "FlexKomSigStartPos" SG_ 527 DATA3 7;
BA_ "FlexKomSigName" SG_ 527 DATA3 "TRM_KeyPkt";
BA_ "FlexKomSigLaenge" SG_ 527 DATA3 64;
BA_ "FlexKomSID" SG_ 527 DATA3 2330;
BA_ "FlexKomIsMotorola" SG_ 527 DATA3 1;
BA_ "FlexKomComment" SG_ 527 DATA3 "Transponder key packet";
BA_ "GenSigSNA" SG_ 527 DATA4 "0h";
BA_ "GenSigSendType" SG_ 527 DATA4 1;
BA_ "FlexKomSigStartValue" SG_ 527 DATA4 "0000000000000000h";
BA_ "FlexKomSigStartPos" SG_ 527 DATA4 7;
BA_ "FlexKomSigName" SG_ 527 DATA4 "TRM_KeyPkt";
BA_ "FlexKomSigLaenge" SG_ 527 DATA4 64;
BA_ "FlexKomSID" SG_ 527 DATA4 2330;
BA_ "FlexKomIsMotorola" SG_ 527 DATA4 1;
BA_ "FlexKomComment" SG_ 527 DATA4 "Transponder key packet";
BA_ "GenSigSNA" SG_ 527 DATA5 "0h";
BA_ "GenSigSendType" SG_ 527 DATA5 1;
BA_ "FlexKomSigStartValue" SG_ 527 DATA5 "0000000000000000h";
BA_ "FlexKomSigStartPos" SG_ 527 DATA5 7;
BA_ "FlexKomSigName" SG_ 527 DATA5 "TRM_KeyPkt";
BA_ "FlexKomSigLaenge" SG_ 527 DATA5 64;
BA_ "FlexKomSID" SG_ 527 DATA5 2330;
BA_ "FlexKomIsMotorola" SG_ 527 DATA5 1;
BA_ "FlexKomComment" SG_ 527 DATA5 "Transponder key packet";
BA_ "GenSigSNA" SG_ 527 DATA6 "0h";
BA_ "GenSigSendType" SG_ 527 DATA6 1;
BA_ "FlexKomSigStartValue" SG_ 527 DATA6 "0000000000000000h";
BA_ "FlexKomSigStartPos" SG_ 527 DATA6 7;
BA_ "FlexKomSigName" SG_ 527 DATA6 "TRM_KeyPkt";
BA_ "FlexKomSigLaenge" SG_ 527 DATA6 64;
BA_ "FlexKomSID" SG_ 527 DATA6 2330;
BA_ "FlexKomIsMotorola" SG_ 527 DATA6 1;
BA_ "FlexKomComment" SG_ 527 DATA6 "Transponder key packet";
BA_ "GenSigSNA" SG_ 527 DATA7 "0h";
BA_ "GenSigSendType" SG_ 527 DATA7 1;
BA_ "FlexKomSigStartValue" SG_ 527 DATA7 "0000000000000000h";
BA_ "FlexKomSigStartPos" SG_ 527 DATA7 7;
BA_ "FlexKomSigName" SG_ 527 DATA7 "TRM_KeyPkt";
BA_ "FlexKomSigLaenge" SG_ 527 DATA7 64;
BA_ "FlexKomSID" SG_ 527 DATA7 2330;
BA_ "FlexKomIsMotorola" SG_ 527 DATA7 1;
BA_ "FlexKomComment" SG_ 527 DATA7 "Transponder key packet";
BA_ "GenSigSNA" SG_ 527 FrameNumber "0h";
BA_ "GenSigSendType" SG_ 527 FrameNumber 1;
BA_ "FlexKomSigStartValue" SG_ 527 FrameNumber "0000000000000000h";
BA_ "FlexKomSigStartPos" SG_ 527 FrameNumber 7;
BA_ "FlexKomSigName" SG_ 527 FrameNumber "TRM_KeyPkt";
BA_ "FlexKomSigLaenge" SG_ 527 FrameNumber 64;
BA_ "FlexKomSID" SG_ 527 FrameNumber 2330;
BA_ "FlexKomIsMotorola" SG_ 527 FrameNumber 1;
BA_ "FlexKomComment" SG_ 527 FrameNumber "Transponder key packet";
BA_ "GenSigSNA" SG_ 527 TotalFrameNumber "0h";
BA_ "GenSigSendType" SG_ 527 TotalFrameNumber 1;
BA_ "FlexKomSigStartValue" SG_ 527 TotalFrameNumber "0000000000000000h";
BA_ "FlexKomSigStartPos" SG_ 527 TotalFrameNumber 7;
BA_ "FlexKomSigName" SG_ 527 TotalFrameNumber "TRM_KeyPkt";
BA_ "FlexKomSigLaenge" SG_ 527 TotalFrameNumber 64;
BA_ "FlexKomSID" SG_ 527 TotalFrameNumber 2330;
BA_ "FlexKomIsMotorola" SG_ 527 TotalFrameNumber 1;
BA_ "FlexKomComment" SG_ 527 TotalFrameNumber "Transponder key packet";
BA_ "GenSigSNA" SG_ 133 EngSt_Enbl_Rq_TCM "0h";
BA_ "GenSigCycleTime" SG_ 133 EngSt_Enbl_Rq_TCM 20;
BA_ "FlexKomSigStartValue" SG_ 133 EngSt_Enbl_Rq_TCM "00h";
BA_ "FlexKomSigStartPos" SG_ 133 EngSt_Enbl_Rq_TCM 5;
BA_ "FlexKomSigName" SG_ 133 EngSt_Enbl_Rq_TCM "EngSt_Enbl_Rq_TCM";
BA_ "FlexKomSigLaenge" SG_ 133 EngSt_Enbl_Rq_TCM 1;
BA_ "FlexKomSID" SG_ 133 EngSt_Enbl_Rq_TCM 1125;
BA_ "FlexKomIsMotorola" SG_ 133 EngSt_Enbl_Rq_TCM 1;
BA_ "FlexKomComment" SG_ 133 EngSt_Enbl_Rq_TCM "Enable engine start request";
BA_ "GenSigSNA" SG_ 133 GearSwitchActiveSts "0h";
BA_ "GenSigCycleTime" SG_ 133 GearSwitchActiveSts 20;
BA_ "FlexKomSigStartValue" SG_ 133 GearSwitchActiveSts "00h";
BA_ "FlexKomSigStartPos" SG_ 133 GearSwitchActiveSts 2;
BA_ "FlexKomSigName" SG_ 133 GearSwitchActiveSts "GearSwitchActiveSts";
BA_ "FlexKomSigLaenge" SG_ 133 GearSwitchActiveSts 1;
BA_ "FlexKomSID" SG_ 133 GearSwitchActiveSts 1528;
BA_ "FlexKomIsMotorola" SG_ 133 GearSwitchActiveSts 1;
BA_ "FlexKomComment" SG_ 133 GearSwitchActiveSts "Transmission shift in progress";
BA_ "RID" SG_ 133 Gr "1069";
BA_ "GenSigTimeout_TPM" SG_ 133 Gr 1010;
BA_ "GenSigTimeout_RF_HUB" SG_ 133 Gr 210;
BA_ "GenSigTimeout_ORC" SG_ 133 Gr 70;
BA_ "GenSigTimeout_IC" SG_ 133 Gr 210;
BA_ "GenSigTimeout_ESM" SG_ 133 Gr 210;
BA_ "GenSigTimeout_DTCM" SG_ 133 Gr 210;
BA_ "GenSigTimeout_CBC" SG_ 133 Gr 210;
BA_ "GenSigStartValue" SG_ 133 Gr 15;
BA_ "GenSigSNA" SG_ 133 Gr "Fh";
BA_ "GenSigCycleTime" SG_ 133 Gr 20;
BA_ "FlexKomSigStartValue" SG_ 133 Gr "FF00h";
BA_ "FlexKomSigStartPos" SG_ 133 Gr 15;
BA_ "FlexKomSigName" SG_ 133 Gr "Gear_Pkt";
BA_ "FlexKomSigLaenge" SG_ 133 Gr 16;
BA_ "FlexKomSID" SG_ 133 Gr 1128;
BA_ "FlexKomIsMotorola" SG_ 133 Gr 1;
BA_ "FlexKomComment" SG_ 133 Gr "Current Gear/Target Gear";
BA_ "RID" SG_ 133 Gr_Target "1814";
BA_ "GenSigTimeout_DTCM" SG_ 133 Gr_Target 210;
BA_ "GenSigTimeout_CBC" SG_ 133 Gr_Target 210;
BA_ "GenSigStartValue" SG_ 133 Gr_Target 15;
BA_ "GenSigSNA" SG_ 133 Gr_Target "Fh";
BA_ "GenSigCycleTime" SG_ 133 Gr_Target 20;
BA_ "FlexKomSigStartValue" SG_ 133 Gr_Target "FF00h";
BA_ "FlexKomSigStartPos" SG_ 133 Gr_Target 15;
BA_ "FlexKomSigName" SG_ 133 Gr_Target "Gear_Pkt";
BA_ "FlexKomSigLaenge" SG_ 133 Gr_Target 16;
BA_ "FlexKomSID" SG_ 133 Gr_Target 1128;
BA_ "FlexKomIsMotorola" SG_ 133 Gr_Target 1;
BA_ "FlexKomComment" SG_ 133 Gr_Target "Current Gear/Target Gear";
BA_ "GenSigSNA" SG_ 133 K_G_B "0h";
BA_ "GenSigCycleTime" SG_ 133 K_G_B 20;
BA_ "FlexKomSigStartValue" SG_ 133 K_G_B "000000h";
BA_ "FlexKomSigStartPos" SG_ 133 K_G_B 7;
BA_ "FlexKomSigName" SG_ 133 K_G_B "K_B";
BA_ "FlexKomSigLaenge" SG_ 133 K_G_B 24;
BA_ "FlexKomSID" SG_ 133 K_G_B 1129;
BA_ "FlexKomIsMotorola" SG_ 133 K_G_B 1;
BA_ "FlexKomComment" SG_ 133 K_G_B "Torque converter lock-up status";
BA_ "GenSigSNA" SG_ 133 K_O_B "0h";
BA_ "GenSigCycleTime" SG_ 133 K_O_B 20;
BA_ "FlexKomSigStartValue" SG_ 133 K_O_B "000000h";
BA_ "FlexKomSigStartPos" SG_ 133 K_O_B 7;
BA_ "FlexKomSigName" SG_ 133 K_O_B "K_B";
BA_ "FlexKomSigLaenge" SG_ 133 K_O_B 24;
BA_ "FlexKomSID" SG_ 133 K_O_B 1129;
BA_ "FlexKomIsMotorola" SG_ 133 K_O_B 1;
BA_ "FlexKomComment" SG_ 133 K_O_B "Torque converter lock-up status";
BA_ "GenSigSNA" SG_ 133 K_STO_B "0h";
BA_ "GenSigCycleTime" SG_ 133 K_STO_B 20;
BA_ "FlexKomSigStartValue" SG_ 133 K_STO_B "000000h";
BA_ "FlexKomSigStartPos" SG_ 133 K_STO_B 7;
BA_ "FlexKomSigName" SG_ 133 K_STO_B "K_B";
BA_ "FlexKomSigLaenge" SG_ 133 K_STO_B 24;
BA_ "FlexKomSID" SG_ 133 K_STO_B 1129;
BA_ "FlexKomIsMotorola" SG_ 133 K_STO_B 1;
BA_ "FlexKomComment" SG_ 133 K_STO_B "Torque converter lock-up status";
BA_ "GenSigSNA" SG_ 133 K_S_B "0h";
BA_ "GenSigCycleTime" SG_ 133 K_S_B 20;
BA_ "FlexKomSigStartValue" SG_ 133 K_S_B "000000h";
BA_ "FlexKomSigStartPos" SG_ 133 K_S_B 7;
BA_ "FlexKomSigName" SG_ 133 K_S_B "K_B";
BA_ "FlexKomSigLaenge" SG_ 133 K_S_B 24;
BA_ "FlexKomSID" SG_ 133 K_S_B 1129;
BA_ "FlexKomIsMotorola" SG_ 133 K_S_B 1;
BA_ "FlexKomComment" SG_ 133 K_S_B "Torque converter lock-up status";
BA_ "GenSigStartValue" SG_ 133 N_Turb 65535;
BA_ "GenSigSNA" SG_ 133 N_Turb "FFFFh";
BA_ "GenSigCycleTime" SG_ 133 N_Turb 20;
BA_ "FlexKomSigStartValue" SG_ 133 N_Turb "FFFFh";
BA_ "FlexKomSigStartPos" SG_ 133 N_Turb 47;
BA_ "FlexKomSigName" SG_ 133 N_Turb "N_Turb";
BA_ "FlexKomSigLaenge" SG_ 133 N_Turb 16;
BA_ "FlexKomSID" SG_ 133 N_Turb 1133;
BA_ "FlexKomIsMotorola" SG_ 133 N_Turb 1;
BA_ "FlexKomComment" SG_ 133 N_Turb "Unfiltered turbine speed (n_t_v)";
BA_ "GenSigStartValue" SG_ 133 OUTPUT_SPEED 65535;
BA_ "GenSigSNA" SG_ 133 OUTPUT_SPEED "FFFFh";
BA_ "GenSigCycleTime" SG_ 133 OUTPUT_SPEED 20;
BA_ "FlexKomSigStartValue" SG_ 133 OUTPUT_SPEED "FFFF000000h";
BA_ "FlexKomSigStartPos" SG_ 133 OUTPUT_SPEED 31;
BA_ "FlexKomSigName" SG_ 133 OUTPUT_SPEED "OutputSpdPkt";
BA_ "FlexKomSigLaenge" SG_ 133 OUTPUT_SPEED 40;
BA_ "FlexKomSID" SG_ 133 OUTPUT_SPEED 1605;
BA_ "FlexKomIsMotorola" SG_ 133 OUTPUT_SPEED 1;
BA_ "FlexKomComment" SG_ 133 OUTPUT_SPEED "Output shaft speed packet";
BA_ "GenSigSNA" SG_ 133 OutputSpdPolarity "3h";
BA_ "GenSigCycleTime" SG_ 133 OutputSpdPolarity 20;
BA_ "FlexKomSigStartValue" SG_ 133 OutputSpdPolarity "FFFF000000h";
BA_ "FlexKomSigStartPos" SG_ 133 OutputSpdPolarity 31;
BA_ "FlexKomSigName" SG_ 133 OutputSpdPolarity "OutputSpdPkt";
BA_ "FlexKomSigLaenge" SG_ 133 OutputSpdPolarity 40;
BA_ "FlexKomSID" SG_ 133 OutputSpdPolarity 1605;
BA_ "FlexKomIsMotorola" SG_ 133 OutputSpdPolarity 1;
BA_ "FlexKomComment" SG_ 133 OutputSpdPolarity "Output shaft speed packet";
BA_ "RID" SG_ 133 TCM_ManMd "1696";
BA_ "GenSigTimeout_IC" SG_ 133 TCM_ManMd 210;
BA_ "GenSigSNA" SG_ 133 TCM_ManMd "0h";
BA_ "GenSigCycleTime" SG_ 133 TCM_ManMd 20;
BA_ "FlexKomSigStartValue" SG_ 133 TCM_ManMd "00h";
BA_ "FlexKomSigStartPos" SG_ 133 TCM_ManMd 63;
BA_ "FlexKomSigName" SG_ 133 TCM_ManMd "ManualMdPkt";
BA_ "FlexKomSigLaenge" SG_ 133 TCM_ManMd 2;
BA_ "FlexKomSID" SG_ 133 TCM_ManMd 1762;
BA_ "FlexKomIsMotorola" SG_ 133 TCM_ManMd 1;
BA_ "FlexKomComment" SG_ 133 TCM_ManMd "Manual mode packet";
BA_ "GenSigSNA" SG_ 133 TRNS_SPD_MC "0h";
BA_ "GenSigCycleTime" SG_ 133 TRNS_SPD_MC 20;
BA_ "FlexKomSigStartValue" SG_ 133 TRNS_SPD_MC "00h";
BA_ "FlexKomSigStartPos" SG_ 133 TRNS_SPD_MC 61;
BA_ "FlexKomSigName" SG_ 133 TRNS_SPD_MC "TRNS_SPD_MC";
BA_ "FlexKomSigLaenge" SG_ 133 TRNS_SPD_MC 4;
BA_ "FlexKomSID" SG_ 133 TRNS_SPD_MC 2607;
BA_ "FlexKomIsMotorola" SG_ 133 TRNS_SPD_MC 1;
BA_ "FlexKomComment" SG_ 133 TRNS_SPD_MC "TRNS_SPD message counter";
BA_ "GenSigSNA" SG_ 133 Trns_EMCC_Achvd "0h";
BA_ "GenSigCycleTime" SG_ 133 Trns_EMCC_Achvd 20;
BA_ "FlexKomSigStartValue" SG_ 133 Trns_EMCC_Achvd "00h";
BA_ "FlexKomSigStartPos" SG_ 133 Trns_EMCC_Achvd 20;
BA_ "FlexKomSigName" SG_ 133 Trns_EMCC_Achvd "Trns_EMCC_Achvd";
BA_ "FlexKomSigLaenge" SG_ 133 Trns_EMCC_Achvd 1;
BA_ "FlexKomSID" SG_ 133 Trns_EMCC_Achvd 1130;
BA_ "FlexKomIsMotorola" SG_ 133 Trns_EMCC_Achvd 1;
BA_ "FlexKomComment" SG_ 133 Trns_EMCC_Achvd "Trans A/C Converter Clutch Slipping; [1] = True";
BA_ "GenSigTimeout_ORC" SG_ 147 CRC_TRNS_STAT 70;
BA_ "GenSigTimeout_ESM" SG_ 147 CRC_TRNS_STAT 410;
BA_ "GenSigStartValue" SG_ 147 CRC_TRNS_STAT 255;
BA_ "GenSigSNA" SG_ 147 CRC_TRNS_STAT "FFh";
BA_ "GenSigCycleTime" SG_ 147 CRC_TRNS_STAT 20;
BA_ "FlexKomSigStartValue" SG_ 147 CRC_TRNS_STAT "1CFFFF00000000FFh";
BA_ "FlexKomSigStartPos" SG_ 147 CRC_TRNS_STAT 7;
BA_ "FlexKomSigName" SG_ 147 CRC_TRNS_STAT "TRNS_STAT_PKT";
BA_ "FlexKomSigLaenge" SG_ 147 CRC_TRNS_STAT 64;
BA_ "FlexKomSID" SG_ 147 CRC_TRNS_STAT 1366;
BA_ "FlexKomIsMotorola" SG_ 147 CRC_TRNS_STAT 1;
BA_ "FlexKomComment" SG_ 147 CRC_TRNS_STAT "TRNS_STAT message packet";
BA_ "GenSigSNA" SG_ 147 EngStEnblRqTCM "0h";
BA_ "GenSigCycleTime" SG_ 147 EngStEnblRqTCM 20;
BA_ "FlexKomSigStartValue" SG_ 147 EngStEnblRqTCM "1CFFFF00000000FFh";
BA_ "FlexKomSigStartPos" SG_ 147 EngStEnblRqTCM 7;
BA_ "FlexKomSigName" SG_ 147 EngStEnblRqTCM "TRNS_STAT_PKT";
BA_ "FlexKomSigLaenge" SG_ 147 EngStEnblRqTCM 64;
BA_ "FlexKomSID" SG_ 147 EngStEnblRqTCM 1366;
BA_ "FlexKomIsMotorola" SG_ 147 EngStEnblRqTCM 1;
BA_ "FlexKomComment" SG_ 147 EngStEnblRqTCM "TRNS_STAT message packet";
BA_ "GenSigTimeout_ORC" SG_ 147 MC_TRNS_STAT 70;
BA_ "GenSigTimeout_ESM" SG_ 147 MC_TRNS_STAT 410;
BA_ "GenSigSNA" SG_ 147 MC_TRNS_STAT "0h";
BA_ "GenSigCycleTime" SG_ 147 MC_TRNS_STAT 20;
BA_ "FlexKomSigStartValue" SG_ 147 MC_TRNS_STAT "1CFFFF00000000FFh";
BA_ "FlexKomSigStartPos" SG_ 147 MC_TRNS_STAT 7;
BA_ "FlexKomSigName" SG_ 147 MC_TRNS_STAT "TRNS_STAT_PKT";
BA_ "FlexKomSigLaenge" SG_ 147 MC_TRNS_STAT 64;
BA_ "FlexKomSID" SG_ 147 MC_TRNS_STAT 1366;
BA_ "FlexKomIsMotorola" SG_ 147 MC_TRNS_STAT 1;
BA_ "FlexKomComment" SG_ 147 MC_TRNS_STAT "TRNS_STAT message packet";
BA_ "GenSigTimeout_IC" SG_ 147 PRNDL_Blink 210;
BA_ "GenSigTimeout_ESM" SG_ 147 PRNDL_Blink 210;
BA_ "GenSigSNA" SG_ 147 PRNDL_Blink "0h";
BA_ "GenSigCycleTime" SG_ 147 PRNDL_Blink 20;
BA_ "FlexKomSigStartValue" SG_ 147 PRNDL_Blink "1CFFFF00000000FFh";
BA_ "FlexKomSigStartPos" SG_ 147 PRNDL_Blink 7;
BA_ "FlexKomSigName" SG_ 147 PRNDL_Blink "TRNS_STAT_PKT";
BA_ "FlexKomSigLaenge" SG_ 147 PRNDL_Blink 64;
BA_ "FlexKomSID" SG_ 147 PRNDL_Blink 1366;
BA_ "FlexKomIsMotorola" SG_ 147 PRNDL_Blink 1;
BA_ "FlexKomComment" SG_ 147 PRNDL_Blink "TRNS_STAT message packet";
BA_ "RID" SG_ 147 PRNDL_DISP "1110";
BA_ "GenSigTimeout_IC" SG_ 147 PRNDL_DISP 210;
BA_ "GenSigTimeout_ESM" SG_ 147 PRNDL_DISP 410;
BA_ "GenSigTimeout_DTCM" SG_ 147 PRNDL_DISP 210;
BA_ "GenSigTimeout_CBC" SG_ 147 PRNDL_DISP 210;
BA_ "GenSigStartValue" SG_ 147 PRNDL_DISP 255;
BA_ "GenSigSNA" SG_ 147 PRNDL_DISP "FFh";
BA_ "GenSigCycleTime" SG_ 147 PRNDL_DISP 20;
BA_ "FlexKomSigStartValue" SG_ 147 PRNDL_DISP "1CFFFF00000000FFh";
BA_ "FlexKomSigStartPos" SG_ 147 PRNDL_DISP 7;
BA_ "FlexKomSigName" SG_ 147 PRNDL_DISP "TRNS_STAT_PKT";
BA_ "FlexKomSigLaenge" SG_ 147 PRNDL_DISP 64;
BA_ "FlexKomSID" SG_ 147 PRNDL_DISP 1366;
BA_ "FlexKomIsMotorola" SG_ 147 PRNDL_DISP 1;
BA_ "FlexKomComment" SG_ 147 PRNDL_DISP "TRNS_STAT message packet";
BA_ "RID" SG_ 147 PRND_STAT "1003 1270 1290 1708 6372 6373 6374";
BA_ "GenSigTimeout_TPM" SG_ 147 PRND_STAT 210;
BA_ "GenSigTimeout_RF_HUB" SG_ 147 PRND_STAT 210;
BA_ "GenSigTimeout_PTS" SG_ 147 PRND_STAT 210;
BA_ "GenSigTimeout_ORC" SG_ 147 PRND_STAT 70;
BA_ "GenSigTimeout_IC" SG_ 147 PRND_STAT 210;
BA_ "GenSigTimeout_ESM" SG_ 147 PRND_STAT 410;
BA_ "GenSigTimeout_DTCM" SG_ 147 PRND_STAT 210;
BA_ "GenSigTimeout_CBC" SG_ 147 PRND_STAT 510;
BA_ "GenSigStartValue" SG_ 147 PRND_STAT 7;
BA_ "GenSigSNA" SG_ 147 PRND_STAT "7h";
BA_ "GenSigCycleTime" SG_ 147 PRND_STAT 20;
BA_ "FlexKomSigStartValue" SG_ 147 PRND_STAT "1CFFFF00000000FFh";
BA_ "FlexKomSigStartPos" SG_ 147 PRND_STAT 7;
BA_ "FlexKomSigName" SG_ 147 PRND_STAT "TRNS_STAT_PKT";
BA_ "FlexKomSigLaenge" SG_ 147 PRND_STAT 64;
BA_ "FlexKomSID" SG_ 147 PRND_STAT 1366;
BA_ "FlexKomIsMotorola" SG_ 147 PRND_STAT 1;
BA_ "FlexKomComment" SG_ 147 PRND_STAT "TRNS_STAT message packet";
BA_ "RID" SG_ 147 PaddlesModeSts "2048";
BA_ "GenSigTimeout_IC" SG_ 147 PaddlesModeSts 210;
BA_ "GenSigTimeout_ESM" SG_ 147 PaddlesModeSts 410;
BA_ "GenSigTimeout_CBC" SG_ 147 PaddlesModeSts 210;
BA_ "GenSigSNA" SG_ 147 PaddlesModeSts "3h";
BA_ "GenSigCycleTime" SG_ 147 PaddlesModeSts 20;
BA_ "FlexKomSigStartValue" SG_ 147 PaddlesModeSts "1CFFFF00000000FFh";
BA_ "FlexKomSigStartPos" SG_ 147 PaddlesModeSts 7;
BA_ "FlexKomSigName" SG_ 147 PaddlesModeSts "TRNS_STAT_PKT";
BA_ "FlexKomSigLaenge" SG_ 147 PaddlesModeSts 64;
BA_ "FlexKomSID" SG_ 147 PaddlesModeSts 1366;
BA_ "FlexKomIsMotorola" SG_ 147 PaddlesModeSts 1;
BA_ "FlexKomComment" SG_ 147 PaddlesModeSts "TRNS_STAT message packet";
BA_ "GenSigTimeout_ESM" SG_ 147 SHFT_LOCK 210;
BA_ "GenSigSNA" SG_ 147 SHFT_LOCK "0h";
BA_ "GenSigCycleTime" SG_ 147 SHFT_LOCK 20;
BA_ "FlexKomSigStartValue" SG_ 147 SHFT_LOCK "1CFFFF00000000FFh";
BA_ "FlexKomSigStartPos" SG_ 147 SHFT_LOCK 7;
BA_ "FlexKomSigName" SG_ 147 SHFT_LOCK "TRNS_STAT_PKT";
BA_ "FlexKomSigLaenge" SG_ 147 SHFT_LOCK 64;
BA_ "FlexKomSID" SG_ 147 SHFT_LOCK 1366;
BA_ "FlexKomIsMotorola" SG_ 147 SHFT_LOCK 1;
BA_ "FlexKomComment" SG_ 147 SHFT_LOCK "TRNS_STAT message packet";
BA_ "RID" SG_ 147 SHFT_PROG "1118";
BA_ "GenSigTimeout_IC" SG_ 147 SHFT_PROG 210;
BA_ "GenSigTimeout_ESM" SG_ 147 SHFT_PROG 410;
BA_ "GenSigTimeout_DTCM" SG_ 147 SHFT_PROG 410;
BA_ "GenSigTimeout_CBC" SG_ 147 SHFT_PROG 210;
BA_ "GenSigStartValue" SG_ 147 SHFT_PROG 255;
BA_ "GenSigSNA" SG_ 147 SHFT_PROG "FFh";
BA_ "GenSigCycleTime" SG_ 147 SHFT_PROG 20;
BA_ "FlexKomSigStartValue" SG_ 147 SHFT_PROG "1CFFFF00000000FFh";
BA_ "FlexKomSigStartPos" SG_ 147 SHFT_PROG 7;
BA_ "FlexKomSigName" SG_ 147 SHFT_PROG "TRNS_STAT_PKT";
BA_ "FlexKomSigLaenge" SG_ 147 SHFT_PROG 64;
BA_ "FlexKomSID" SG_ 147 SHFT_PROG 1366;
BA_ "FlexKomIsMotorola" SG_ 147 SHFT_PROG 1;
BA_ "FlexKomComment" SG_ 147 SHFT_PROG "TRNS_STAT message packet";
BA_ "GenSigSNA" SG_ 147 TxDisengaged "0h";
BA_ "GenSigCycleTime" SG_ 147 TxDisengaged 20;
BA_ "FlexKomSigStartValue" SG_ 147 TxDisengaged "1CFFFF00000000FFh";
BA_ "FlexKomSigStartPos" SG_ 147 TxDisengaged 7;
BA_ "FlexKomSigName" SG_ 147 TxDisengaged "TRNS_STAT_PKT";
BA_ "FlexKomSigLaenge" SG_ 147 TxDisengaged 64;
BA_ "FlexKomSID" SG_ 147 TxDisengaged 1366;
BA_ "FlexKomIsMotorola" SG_ 147 TxDisengaged 1;
BA_ "FlexKomComment" SG_ 147 TxDisengaged "TRNS_STAT message packet";
BA_ "GenSigStartValue" SG_ 293 FAN_RQ 15;
BA_ "GenSigSNA" SG_ 293 FAN_RQ "Fh";
BA_ "GenSigCycleTime" SG_ 293 FAN_RQ 100;
BA_ "FlexKomSigStartValue" SG_ 293 FAN_RQ "0Fh";
BA_ "FlexKomSigStartPos" SG_ 293 FAN_RQ 7;
BA_ "FlexKomSigName" SG_ 293 FAN_RQ "FAN_RQ";
BA_ "FlexKomSigLaenge" SG_ 293 FAN_RQ 4;
BA_ "FlexKomSID" SG_ 293 FAN_RQ 1145;
BA_ "FlexKomIsMotorola" SG_ 293 FAN_RQ 1;
BA_ "FlexKomComment" SG_ 293 FAN_RQ "Cooling fan request";
BA_ "GenSigTimeout_ORC" SG_ 293 GS_NOTL 350;
BA_ "GenSigSNA" SG_ 293 GS_NOTL "0h";
BA_ "GenSigCycleTime" SG_ 293 GS_NOTL 100;
BA_ "FlexKomSigStartValue" SG_ 293 GS_NOTL "00h";
BA_ "FlexKomSigStartPos" SG_ 293 GS_NOTL 2;
BA_ "FlexKomSigName" SG_ 293 GS_NOTL "GS_NOTL";
BA_ "FlexKomSigLaenge" SG_ 293 GS_NOTL 1;
BA_ "FlexKomSID" SG_ 293 GS_NOTL 1143;
BA_ "FlexKomIsMotorola" SG_ 293 GS_NOTL 1;
BA_ "FlexKomComment" SG_ 293 GS_NOTL "TRANS in limp home mode";
BA_ "GenSigTimeout_IC" SG_ 293 MIL_OnRq_TCM 1050;
BA_ "GenSigSNA" SG_ 293 MIL_OnRq_TCM "0h";
BA_ "GenSigCycleTime" SG_ 293 MIL_OnRq_TCM 100;
BA_ "FlexKomSigStartValue" SG_ 293 MIL_OnRq_TCM "00h";
BA_ "FlexKomSigName" SG_ 293 MIL_OnRq_TCM "MIL_OnRq_TCM";
BA_ "FlexKomSigLaenge" SG_ 293 MIL_OnRq_TCM 1;
BA_ "FlexKomSID" SG_ 293 MIL_OnRq_TCM 1141;
BA_ "FlexKomIsMotorola" SG_ 293 MIL_OnRq_TCM 1;
BA_ "FlexKomComment" SG_ 293 MIL_OnRq_TCM "MIL on request from the transmission";
BA_ "GenSigStartValue" SG_ 293 TRNS_StpSt_FLT 1;
BA_ "GenSigSNA" SG_ 293 TRNS_StpSt_FLT "1h";
BA_ "GenSigCycleTime" SG_ 293 TRNS_StpSt_FLT 100;
BA_ "FlexKomSigStartValue" SG_ 293 TRNS_StpSt_FLT "01h";
BA_ "FlexKomSigStartPos" SG_ 293 TRNS_StpSt_FLT 23;
BA_ "FlexKomSigName" SG_ 293 TRNS_StpSt_FLT "TRNS_StpSt_FLT";
BA_ "FlexKomSigLaenge" SG_ 293 TRNS_StpSt_FLT 1;
BA_ "FlexKomSID" SG_ 293 TRNS_StpSt_FLT 1399;
BA_ "FlexKomIsMotorola" SG_ 293 TRNS_StpSt_FLT 1;
BA_ "FlexKomComment" SG_ 293 TRNS_StpSt_FLT "Trans stop start fault (1=fault)";
BA_ "GenSigTimeout_ESM" SG_ 293 TX_FAULT 1050;
BA_ "GenSigSNA" SG_ 293 TX_FAULT "3h";
BA_ "GenSigCycleTime" SG_ 293 TX_FAULT 100;
BA_ "FlexKomSigStartValue" SG_ 293 TX_FAULT "00h";
BA_ "FlexKomSigStartPos" SG_ 293 TX_FAULT 21;
BA_ "FlexKomSigName" SG_ 293 TX_FAULT "TX_FAULT";
BA_ "FlexKomSigLaenge" SG_ 293 TX_FAULT 2;
BA_ "FlexKomSID" SG_ 293 TX_FAULT 1364;
BA_ "FlexKomIsMotorola" SG_ 293 TX_FAULT 1;
BA_ "FlexKomComment" SG_ 293 TX_FAULT "Transmission fault";
BA_ "RID" SG_ 293 TX_TEMP "1265";
BA_ "GenSigTimeout_IC" SG_ 293 TX_TEMP 1050;
BA_ "GenSigTimeout_ETM" SG_ 293 TX_TEMP 1050;
BA_ "GenSigTimeout_CBC" SG_ 293 TX_TEMP 1050;
BA_ "GenSigStartValue" SG_ 293 TX_TEMP 255;
BA_ "GenSigSNA" SG_ 293 TX_TEMP "FFh";
BA_ "GenSigCycleTime" SG_ 293 TX_TEMP 100;
BA_ "FlexKomSigStartValue" SG_ 293 TX_TEMP "FFh";
BA_ "FlexKomSigStartPos" SG_ 293 TX_TEMP 15;
BA_ "FlexKomSigName" SG_ 293 TX_TEMP "TX_TEMP";
BA_ "FlexKomSigLaenge" SG_ 293 TX_TEMP 8;
BA_ "FlexKomSID" SG_ 293 TX_TEMP 1146;
BA_ "FlexKomIsMotorola" SG_ 293 TX_TEMP 1;
BA_ "FlexKomComment" SG_ 293 TX_TEMP "Transmission fluid temperature";
BA_ "GenSigTimeout_IC" SG_ 293 TX_WARN 1050;
BA_ "GenSigSNA" SG_ 293 TX_WARN "Fh";
BA_ "GenSigCycleTime" SG_ 293 TX_WARN 100;
BA_ "FlexKomSigStartValue" SG_ 293 TX_WARN "00h";
BA_ "FlexKomSigStartPos" SG_ 293 TX_WARN 19;
BA_ "FlexKomSigName" SG_ 293 TX_WARN "TX_WARN";
BA_ "FlexKomSigLaenge" SG_ 293 TX_WARN 4;
BA_ "FlexKomSID" SG_ 293 TX_WARN 1365;
BA_ "FlexKomIsMotorola" SG_ 293 TX_WARN 1;
BA_ "FlexKomComment" SG_ 293 TX_WARN "Transmission warning";
BA_ "GenSigSNA" SG_ 293 TransReadyForESS "0h";
BA_ "GenSigCycleTime" SG_ 293 TransReadyForESS 100;
BA_ "FlexKomSigStartValue" SG_ 293 TransReadyForESS "00h";
BA_ "FlexKomSigStartPos" SG_ 293 TransReadyForESS 22;
BA_ "FlexKomSigName" SG_ 293 TransReadyForESS "TransReadyForESS";
BA_ "FlexKomSigLaenge" SG_ 293 TransReadyForESS 1;
BA_ "FlexKomSID" SG_ 293 TransReadyForESS 1665;
BA_ "FlexKomIsMotorola" SG_ 293 TransReadyForESS 1;
BA_ "FlexKomComment" SG_ 293 TransReadyForESS "Trans ready for auto stop (0= not ready)";
BA_ "RID" SG_ 293 TxTemp_Excess "6542";
BA_ "GenSigTimeout_TBM" SG_ 293 TxTemp_Excess 1050;
BA_ "GenSigTimeout_IC" SG_ 293 TxTemp_Excess 1050;
BA_ "GenSigTimeout_ETM" SG_ 293 TxTemp_Excess 1050;
BA_ "GenSigSNA" SG_ 293 TxTemp_Excess "0h";
BA_ "GenSigCycleTime" SG_ 293 TxTemp_Excess 100;
BA_ "FlexKomSigStartValue" SG_ 293 TxTemp_Excess "00h";
BA_ "FlexKomSigStartPos" SG_ 293 TxTemp_Excess 3;
BA_ "FlexKomSigName" SG_ 293 TxTemp_Excess "TxTemp_Excess";
BA_ "FlexKomSigLaenge" SG_ 293 TxTemp_Excess 1;
BA_ "FlexKomSID" SG_ 293 TxTemp_Excess 1144;
BA_ "FlexKomIsMotorola" SG_ 293 TxTemp_Excess 1;
BA_ "FlexKomComment" SG_ 293 TxTemp_Excess "Excessive transmission temperature";
BA_ "GenSigSNA" SG_ 698 UConnReq "1Fh";
BA_ "GenSigSendType" SG_ 698 UConnReq 8;
BA_ "GenSigCycleTimeActive" SG_ 698 UConnReq 100;
BA_ "FlexKomSigStartValue" SG_ 698 UConnReq "00000000h";
BA_ "FlexKomSigStartPos" SG_ 698 UConnReq 7;
BA_ "FlexKomSigName" SG_ 698 UConnReq "Uconnect_1_Pkt";
BA_ "FlexKomSigLaenge" SG_ 698 UConnReq 32;
BA_ "FlexKomSID" SG_ 698 UConnReq 1772;
BA_ "FlexKomIsMotorola" SG_ 698 UConnReq 1;
BA_ "FlexKomComment" SG_ 698 UConnReq "Uconnect_1_Pkt";
BA_ "GenSigSNA" SG_ 698 UConnReqAuthCode "FFFFh";
BA_ "GenSigSendType" SG_ 698 UConnReqAuthCode 8;
BA_ "GenSigCycleTimeActive" SG_ 698 UConnReqAuthCode 100;
BA_ "FlexKomSigStartValue" SG_ 698 UConnReqAuthCode "00000000h";
BA_ "FlexKomSigStartPos" SG_ 698 UConnReqAuthCode 7;
BA_ "FlexKomSigName" SG_ 698 UConnReqAuthCode "Uconnect_1_Pkt";
BA_ "FlexKomSigLaenge" SG_ 698 UConnReqAuthCode 32;
BA_ "FlexKomSID" SG_ 698 UConnReqAuthCode 1772;
BA_ "FlexKomIsMotorola" SG_ 698 UConnReqAuthCode 1;
BA_ "FlexKomComment" SG_ 698 UConnReqAuthCode "Uconnect_1_Pkt";
BA_ "GenSigSNA" SG_ 698 UConnReqFOBNum "Fh";
BA_ "GenSigSendType" SG_ 698 UConnReqFOBNum 8;
BA_ "GenSigCycleTimeActive" SG_ 698 UConnReqFOBNum 100;
BA_ "FlexKomSigStartValue" SG_ 698 UConnReqFOBNum "00000000h";
BA_ "FlexKomSigStartPos" SG_ 698 UConnReqFOBNum 7;
BA_ "FlexKomSigName" SG_ 698 UConnReqFOBNum "Uconnect_1_Pkt";
BA_ "FlexKomSigLaenge" SG_ 698 UConnReqFOBNum 32;
BA_ "FlexKomSID" SG_ 698 UConnReqFOBNum 1772;
BA_ "FlexKomIsMotorola" SG_ 698 UConnReqFOBNum 1;
BA_ "FlexKomComment" SG_ 698 UConnReqFOBNum "Uconnect_1_Pkt";
BA_ "RID" SG_ 992 VIN_DATA "1239";
BA_ "GenSigTimeout_TPM" SG_ 992 VIN_DATA 1050;
BA_ "GenSigTimeout_SCCM" SG_ 992 VIN_DATA 1050;
BA_ "GenSigTimeout_ORC" SG_ 992 VIN_DATA 350;
BA_ "GenSigTimeout_OCM" SG_ 992 VIN_DATA 5050;
BA_ "GenSigTimeout_IC" SG_ 992 VIN_DATA 1050;
BA_ "GenSigTimeout_ESM" SG_ 992 VIN_DATA 1050;
BA_ "GenSigTimeout_EHPS" SG_ 992 VIN_DATA 1050;
BA_ "GenSigTimeout_DPDM" SG_ 992 VIN_DATA 5050;
BA_ "GenSigSNA" SG_ 992 VIN_DATA "0h";
BA_ "GenSigCycleTime" SG_ 992 VIN_DATA 100;
BA_ "FlexKomSigStartValue" SG_ 992 VIN_DATA "0300000000000000h";
BA_ "FlexKomSigStartPos" SG_ 992 VIN_DATA 7;
BA_ "FlexKomSigName" SG_ 992 VIN_DATA "VIN_INFO";
BA_ "FlexKomSigLaenge" SG_ 992 VIN_DATA 64;
BA_ "FlexKomSID" SG_ 992 VIN_DATA 430;
BA_ "FlexKomIsMotorola" SG_ 992 VIN_DATA 1;
BA_ "FlexKomComment" SG_ 992 VIN_DATA "Vin Information";
BA_ "RID" SG_ 992 VIN_MSG "1275";
BA_ "GenSigTimeout_TPM" SG_ 992 VIN_MSG 1050;
BA_ "GenSigTimeout_SCCM" SG_ 992 VIN_MSG 1050;
BA_ "GenSigTimeout_RF_HUB" SG_ 992 VIN_MSG 1050;
BA_ "GenSigTimeout_ORC" SG_ 992 VIN_MSG 350;
BA_ "GenSigTimeout_OCM" SG_ 992 VIN_MSG 5050;
BA_ "GenSigTimeout_IC" SG_ 992 VIN_MSG 1050;
BA_ "GenSigTimeout_ESM" SG_ 992 VIN_MSG 1050;
BA_ "GenSigTimeout_EHPS" SG_ 992 VIN_MSG 1050;
BA_ "GenSigTimeout_DTCM" SG_ 992 VIN_MSG 1050;
BA_ "GenSigTimeout_DPDM" SG_ 992 VIN_MSG 5050;
BA_ "GenSigStartValue" SG_ 992 VIN_MSG 3;
BA_ "GenSigSNA" SG_ 992 VIN_MSG "3h";
BA_ "GenSigCycleTime" SG_ 992 VIN_MSG 100;
BA_ "FlexKomSigStartValue" SG_ 992 VIN_MSG "0300000000000000h";
BA_ "FlexKomSigStartPos" SG_ 992 VIN_MSG 7;
BA_ "FlexKomSigName" SG_ 992 VIN_MSG "VIN_INFO";
BA_ "FlexKomSigLaenge" SG_ 992 VIN_MSG 64;
BA_ "FlexKomSID" SG_ 992 VIN_MSG 430;
BA_ "FlexKomIsMotorola" SG_ 992 VIN_MSG 1;
BA_ "FlexKomComment" SG_ 992 VIN_MSG "Vin Information";
BA_ "GenSigTimeout_IC" SG_ 1000 VC_AUTO_HB 5250;
BA_ "GenSigSNA" SG_ 1000 VC_AUTO_HB "0h";
BA_ "GenSigSendType" SG_ 1000 VC_AUTO_HB 5;
BA_ "GenSigCycleTime" SG_ 1000 VC_AUTO_HB 500;
BA_ "FlexKomSigStartValue" SG_ 1000 VC_AUTO_HB "FFFF7FF0FF0FFF00h";
BA_ "FlexKomSigStartPos" SG_ 1000 VC_AUTO_HB 7;
BA_ "FlexKomSigName" SG_ 1000 VC_AUTO_HB "VehCfg1_Pkt";
BA_ "FlexKomSigLaenge" SG_ 1000 VC_AUTO_HB 64;
BA_ "FlexKomSID" SG_ 1000 VC_AUTO_HB 886;
BA_ "FlexKomIsMotorola" SG_ 1000 VC_AUTO_HB 1;
BA_ "FlexKomComment" SG_ 1000 VC_AUTO_HB "Vehicle Configuration 1 Packet";
BA_ "GenSigTimeout_TPM" SG_ 1000 VC_BODY_STYLE 5250;
BA_ "GenSigTimeout_SCCM" SG_ 1000 VC_BODY_STYLE 5250;
BA_ "GenSigTimeout_ORC" SG_ 1000 VC_BODY_STYLE 1750;
BA_ "GenSigTimeout_IC" SG_ 1000 VC_BODY_STYLE 5250;
BA_ "GenSigTimeout_ESM" SG_ 1000 VC_BODY_STYLE 5250;
BA_ "GenSigTimeout_EHPS" SG_ 1000 VC_BODY_STYLE 5250;
BA_ "GenSigTimeout_DTCM" SG_ 1000 VC_BODY_STYLE 5250;
BA_ "GenSigStartValue" SG_ 1000 VC_BODY_STYLE 15;
BA_ "GenSigSNA" SG_ 1000 VC_BODY_STYLE "Fh";
BA_ "GenSigSendType" SG_ 1000 VC_BODY_STYLE 5;
BA_ "GenSigCycleTime" SG_ 1000 VC_BODY_STYLE 500;
BA_ "FlexKomSigStartValue" SG_ 1000 VC_BODY_STYLE "FFFF7FF0FF0FFF00h";
BA_ "FlexKomSigStartPos" SG_ 1000 VC_BODY_STYLE 7;
BA_ "FlexKomSigName" SG_ 1000 VC_BODY_STYLE "VehCfg1_Pkt";
BA_ "FlexKomSigLaenge" SG_ 1000 VC_BODY_STYLE 64;
BA_ "FlexKomSID" SG_ 1000 VC_BODY_STYLE 886;
BA_ "FlexKomIsMotorola" SG_ 1000 VC_BODY_STYLE 1;
BA_ "FlexKomComment" SG_ 1000 VC_BODY_STYLE "Vehicle Configuration 1 Packet";
BA_ "GenSigSNA" SG_ 1000 VC_CHMCM_Prsnt "0h";
BA_ "GenSigSendType" SG_ 1000 VC_CHMCM_Prsnt 5;
BA_ "GenSigCycleTime" SG_ 1000 VC_CHMCM_Prsnt 500;
BA_ "FlexKomSigStartValue" SG_ 1000 VC_CHMCM_Prsnt "FFFF7FF0FF0FFF00h";
BA_ "FlexKomSigStartPos" SG_ 1000 VC_CHMCM_Prsnt 7;
BA_ "FlexKomSigName" SG_ 1000 VC_CHMCM_Prsnt "VehCfg1_Pkt";
BA_ "FlexKomSigLaenge" SG_ 1000 VC_CHMCM_Prsnt 64;
BA_ "FlexKomSID" SG_ 1000 VC_CHMCM_Prsnt 886;
BA_ "FlexKomIsMotorola" SG_ 1000 VC_CHMCM_Prsnt 1;
BA_ "FlexKomComment" SG_ 1000 VC_CHMCM_Prsnt "Vehicle Configuration 1 Packet";
BA_ "GenSigTimeout_TPM" SG_ 1000 VC_COUNTRY 5250;
BA_ "GenSigTimeout_SCCM" SG_ 1000 VC_COUNTRY 5250;
BA_ "GenSigTimeout_ORC" SG_ 1000 VC_COUNTRY 1750;
BA_ "GenSigTimeout_IC" SG_ 1000 VC_COUNTRY 5250;
BA_ "GenSigTimeout_ESM" SG_ 1000 VC_COUNTRY 5250;
BA_ "GenSigTimeout_EHPS" SG_ 1000 VC_COUNTRY 5250;
BA_ "GenSigTimeout_DTCM" SG_ 1000 VC_COUNTRY 5250;
BA_ "GenSigStartValue" SG_ 1000 VC_COUNTRY 31;
BA_ "GenSigSNA" SG_ 1000 VC_COUNTRY "1Fh";
BA_ "GenSigSendType" SG_ 1000 VC_COUNTRY 5;
BA_ "GenSigCycleTime" SG_ 1000 VC_COUNTRY 500;
BA_ "FlexKomSigStartValue" SG_ 1000 VC_COUNTRY "FFFF7FF0FF0FFF00h";
BA_ "FlexKomSigStartPos" SG_ 1000 VC_COUNTRY 7;
BA_ "FlexKomSigName" SG_ 1000 VC_COUNTRY "VehCfg1_Pkt";
BA_ "FlexKomSigLaenge" SG_ 1000 VC_COUNTRY 64;
BA_ "FlexKomSID" SG_ 1000 VC_COUNTRY 886;
BA_ "FlexKomIsMotorola" SG_ 1000 VC_COUNTRY 1;
BA_ "FlexKomComment" SG_ 1000 VC_COUNTRY "Vehicle Configuration 1 Packet";
BA_ "GenSigSNA" SG_ 1000 VC_EmodePrsnt "0h";
BA_ "GenSigSendType" SG_ 1000 VC_EmodePrsnt 5;
BA_ "GenSigCycleTime" SG_ 1000 VC_EmodePrsnt 500;
BA_ "FlexKomSigStartValue" SG_ 1000 VC_EmodePrsnt "FFFF7FF0FF0FFF00h";
BA_ "FlexKomSigStartPos" SG_ 1000 VC_EmodePrsnt 7;
BA_ "FlexKomSigName" SG_ 1000 VC_EmodePrsnt "VehCfg1_Pkt";
BA_ "FlexKomSigLaenge" SG_ 1000 VC_EmodePrsnt 64;
BA_ "FlexKomSID" SG_ 1000 VC_EmodePrsnt 886;
BA_ "FlexKomIsMotorola" SG_ 1000 VC_EmodePrsnt 1;
BA_ "FlexKomComment" SG_ 1000 VC_EmodePrsnt "Vehicle Configuration 1 Packet";
BA_ "GenSigTimeout_IC" SG_ 1000 VC_HDC_Prsnt 5250;
BA_ "GenSigSNA" SG_ 1000 VC_HDC_Prsnt "0h";
BA_ "GenSigSendType" SG_ 1000 VC_HDC_Prsnt 5;
BA_ "GenSigCycleTime" SG_ 1000 VC_HDC_Prsnt 500;
BA_ "FlexKomSigStartValue" SG_ 1000 VC_HDC_Prsnt "FFFF7FF0FF0FFF00h";
BA_ "FlexKomSigStartPos" SG_ 1000 VC_HDC_Prsnt 7;
BA_ "FlexKomSigName" SG_ 1000 VC_HDC_Prsnt "VehCfg1_Pkt";
BA_ "FlexKomSigLaenge" SG_ 1000 VC_HDC_Prsnt 64;
BA_ "FlexKomSID" SG_ 1000 VC_HDC_Prsnt 886;
BA_ "FlexKomIsMotorola" SG_ 1000 VC_HDC_Prsnt 1;
BA_ "FlexKomComment" SG_ 1000 VC_HDC_Prsnt "Vehicle Configuration 1 Packet";
BA_ "GenSigSNA" SG_ 1000 VC_HdRstPrsnt "0h";
BA_ "GenSigSendType" SG_ 1000 VC_HdRstPrsnt 5;
BA_ "GenSigCycleTime" SG_ 1000 VC_HdRstPrsnt 500;
BA_ "FlexKomSigStartValue" SG_ 1000 VC_HdRstPrsnt "FFFF7FF0FF0FFF00h";
BA_ "FlexKomSigStartPos" SG_ 1000 VC_HdRstPrsnt 7;
BA_ "FlexKomSigName" SG_ 1000 VC_HdRstPrsnt "VehCfg1_Pkt";
BA_ "FlexKomSigLaenge" SG_ 1000 VC_HdRstPrsnt 64;
BA_ "FlexKomSID" SG_ 1000 VC_HdRstPrsnt 886;
BA_ "FlexKomIsMotorola" SG_ 1000 VC_HdRstPrsnt 1;
BA_ "FlexKomComment" SG_ 1000 VC_HdRstPrsnt "Vehicle Configuration 1 Packet";
BA_ "GenSigTimeout_ORC" SG_ 1000 VC_LHD_RHD 1750;
BA_ "GenSigTimeout_IC" SG_ 1000 VC_LHD_RHD 5250;
BA_ "GenSigTimeout_ESM" SG_ 1000 VC_LHD_RHD 5250;
BA_ "GenSigStartValue" SG_ 1000 VC_LHD_RHD 3;
BA_ "GenSigSNA" SG_ 1000 VC_LHD_RHD "3h";
BA_ "GenSigSendType" SG_ 1000 VC_LHD_RHD 5;
BA_ "GenSigCycleTime" SG_ 1000 VC_LHD_RHD 500;
BA_ "FlexKomSigStartValue" SG_ 1000 VC_LHD_RHD "FFFF7FF0FF0FFF00h";
BA_ "FlexKomSigStartPos" SG_ 1000 VC_LHD_RHD 7;
BA_ "FlexKomSigName" SG_ 1000 VC_LHD_RHD "VehCfg1_Pkt";
BA_ "FlexKomSigLaenge" SG_ 1000 VC_LHD_RHD 64;
BA_ "FlexKomSID" SG_ 1000 VC_LHD_RHD 886;
BA_ "FlexKomIsMotorola" SG_ 1000 VC_LHD_RHD 1;
BA_ "FlexKomComment" SG_ 1000 VC_LHD_RHD "Vehicle Configuration 1 Packet";
BA_ "GenSigStartValue" SG_ 1000 VC_MAX_VEH_SPD 255;
BA_ "GenSigSNA" SG_ 1000 VC_MAX_VEH_SPD "FFh";
BA_ "GenSigSendType" SG_ 1000 VC_MAX_VEH_SPD 5;
BA_ "GenSigCycleTime" SG_ 1000 VC_MAX_VEH_SPD 500;
BA_ "FlexKomSigStartValue" SG_ 1000 VC_MAX_VEH_SPD "FFFF7FF0FF0FFF00h";
BA_ "FlexKomSigStartPos" SG_ 1000 VC_MAX_VEH_SPD 7;
BA_ "FlexKomSigName" SG_ 1000 VC_MAX_VEH_SPD "VehCfg1_Pkt";
BA_ "FlexKomSigLaenge" SG_ 1000 VC_MAX_VEH_SPD 64;
BA_ "FlexKomSID" SG_ 1000 VC_MAX_VEH_SPD 886;
BA_ "FlexKomIsMotorola" SG_ 1000 VC_MAX_VEH_SPD 1;
BA_ "FlexKomComment" SG_ 1000 VC_MAX_VEH_SPD "Vehicle Configuration 1 Packet";
BA_ "GenSigTimeout_TPM" SG_ 1000 VC_MODEL_YEAR 5250;
BA_ "GenSigTimeout_SCCM" SG_ 1000 VC_MODEL_YEAR 5250;
BA_ "GenSigTimeout_ORC" SG_ 1000 VC_MODEL_YEAR 1750;
BA_ "GenSigTimeout_IC" SG_ 1000 VC_MODEL_YEAR 5250;
BA_ "GenSigTimeout_ESM" SG_ 1000 VC_MODEL_YEAR 5250;
BA_ "GenSigTimeout_EHPS" SG_ 1000 VC_MODEL_YEAR 5250;
BA_ "GenSigTimeout_DTCM" SG_ 1000 VC_MODEL_YEAR 5250;
BA_ "GenSigStartValue" SG_ 1000 VC_MODEL_YEAR 63;
BA_ "GenSigSNA" SG_ 1000 VC_MODEL_YEAR "3Fh";
BA_ "GenSigSendType" SG_ 1000 VC_MODEL_YEAR 5;
BA_ "GenSigCycleTime" SG_ 1000 VC_MODEL_YEAR 500;
BA_ "FlexKomSigStartValue" SG_ 1000 VC_MODEL_YEAR "FFFF7FF0FF0FFF00h";
BA_ "FlexKomSigStartPos" SG_ 1000 VC_MODEL_YEAR 7;
BA_ "FlexKomSigName" SG_ 1000 VC_MODEL_YEAR "VehCfg1_Pkt";
BA_ "FlexKomSigLaenge" SG_ 1000 VC_MODEL_YEAR 64;
BA_ "FlexKomSID" SG_ 1000 VC_MODEL_YEAR 886;
BA_ "FlexKomIsMotorola" SG_ 1000 VC_MODEL_YEAR 1;
BA_ "FlexKomComment" SG_ 1000 VC_MODEL_YEAR "Vehicle Configuration 1 Packet";
BA_ "GenSigTimeout_IC" SG_ 1000 VC_PP_Prsnt 5250;
BA_ "GenSigSNA" SG_ 1000 VC_PP_Prsnt "0h";
BA_ "GenSigSendType" SG_ 1000 VC_PP_Prsnt 5;
BA_ "GenSigCycleTime" SG_ 1000 VC_PP_Prsnt 500;
BA_ "FlexKomSigStartValue" SG_ 1000 VC_PP_Prsnt "FFFF7FF0FF0FFF00h";
BA_ "FlexKomSigStartPos" SG_ 1000 VC_PP_Prsnt 7;
BA_ "FlexKomSigName" SG_ 1000 VC_PP_Prsnt "VehCfg1_Pkt";
BA_ "FlexKomSigLaenge" SG_ 1000 VC_PP_Prsnt 64;
BA_ "FlexKomSID" SG_ 1000 VC_PP_Prsnt 886;
BA_ "FlexKomIsMotorola" SG_ 1000 VC_PP_Prsnt 1;
BA_ "FlexKomComment" SG_ 1000 VC_PP_Prsnt "Vehicle Configuration 1 Packet";
BA_ "GenSigTimeout_PTS" SG_ 1000 VC_PTS_Config 2750;
BA_ "GenSigTimeout_IC" SG_ 1000 VC_PTS_Config 5250;
BA_ "GenSigSNA" SG_ 1000 VC_PTS_Config "0h";
BA_ "GenSigSendType" SG_ 1000 VC_PTS_Config 5;
BA_ "GenSigCycleTime" SG_ 1000 VC_PTS_Config 500;
BA_ "FlexKomSigStartValue" SG_ 1000 VC_PTS_Config "FFFF7FF0FF0FFF00h";
BA_ "FlexKomSigStartPos" SG_ 1000 VC_PTS_Config 7;
BA_ "FlexKomSigName" SG_ 1000 VC_PTS_Config "VehCfg1_Pkt";
BA_ "FlexKomSigLaenge" SG_ 1000 VC_PTS_Config 64;
BA_ "FlexKomSID" SG_ 1000 VC_PTS_Config 886;
BA_ "FlexKomIsMotorola" SG_ 1000 VC_PTS_Config 1;
BA_ "FlexKomComment" SG_ 1000 VC_PTS_Config "Vehicle Configuration 1 Packet";
BA_ "GenSigTimeout_PTS" SG_ 1000 VC_PTS_DispTyp 2750;
BA_ "GenSigSNA" SG_ 1000 VC_PTS_DispTyp "7h";
BA_ "GenSigSendType" SG_ 1000 VC_PTS_DispTyp 5;
BA_ "GenSigCycleTime" SG_ 1000 VC_PTS_DispTyp 500;
BA_ "FlexKomSigStartValue" SG_ 1000 VC_PTS_DispTyp "FFFF7FF0FF0FFF00h";
BA_ "FlexKomSigStartPos" SG_ 1000 VC_PTS_DispTyp 7;
BA_ "FlexKomSigName" SG_ 1000 VC_PTS_DispTyp "VehCfg1_Pkt";
BA_ "FlexKomSigLaenge" SG_ 1000 VC_PTS_DispTyp 64;
BA_ "FlexKomSID" SG_ 1000 VC_PTS_DispTyp 886;
BA_ "FlexKomIsMotorola" SG_ 1000 VC_PTS_DispTyp 1;
BA_ "FlexKomComment" SG_ 1000 VC_PTS_DispTyp "Vehicle Configuration 1 Packet";
BA_ "GenSigSNA" SG_ 1000 VC_RVCM_Prsnt "0h";
BA_ "GenSigSendType" SG_ 1000 VC_RVCM_Prsnt 5;
BA_ "GenSigCycleTime" SG_ 1000 VC_RVCM_Prsnt 500;
BA_ "FlexKomSigStartValue" SG_ 1000 VC_RVCM_Prsnt "FFFF7FF0FF0FFF00h";
BA_ "FlexKomSigStartPos" SG_ 1000 VC_RVCM_Prsnt 7;
BA_ "FlexKomSigName" SG_ 1000 VC_RVCM_Prsnt "VehCfg1_Pkt";
BA_ "FlexKomSigLaenge" SG_ 1000 VC_RVCM_Prsnt 64;
BA_ "FlexKomSID" SG_ 1000 VC_RVCM_Prsnt 886;
BA_ "FlexKomIsMotorola" SG_ 1000 VC_RVCM_Prsnt 1;
BA_ "FlexKomComment" SG_ 1000 VC_RVCM_Prsnt "Vehicle Configuration 1 Packet";
BA_ "GenSigTimeout_TPM" SG_ 1000 VC_RemStPrsnt 5250;
BA_ "GenSigTimeout_IC" SG_ 1000 VC_RemStPrsnt 5250;
BA_ "GenSigSNA" SG_ 1000 VC_RemStPrsnt "0h";
BA_ "GenSigSendType" SG_ 1000 VC_RemStPrsnt 5;
BA_ "GenSigCycleTime" SG_ 1000 VC_RemStPrsnt 500;
BA_ "FlexKomSigStartValue" SG_ 1000 VC_RemStPrsnt "FFFF7FF0FF0FFF00h";
BA_ "FlexKomSigStartPos" SG_ 1000 VC_RemStPrsnt 7;
BA_ "FlexKomSigName" SG_ 1000 VC_RemStPrsnt "VehCfg1_Pkt";
BA_ "FlexKomSigLaenge" SG_ 1000 VC_RemStPrsnt 64;
BA_ "FlexKomSID" SG_ 1000 VC_RemStPrsnt 886;
BA_ "FlexKomIsMotorola" SG_ 1000 VC_RemStPrsnt 1;
BA_ "FlexKomComment" SG_ 1000 VC_RemStPrsnt "Vehicle Configuration 1 Packet";
BA_ "GenSigTimeout_IC" SG_ 1000 VC_SCR_Prsnt 5250;
BA_ "GenSigSNA" SG_ 1000 VC_SCR_Prsnt "0h";
BA_ "GenSigSendType" SG_ 1000 VC_SCR_Prsnt 5;
BA_ "GenSigCycleTime" SG_ 1000 VC_SCR_Prsnt 500;
BA_ "FlexKomSigStartValue" SG_ 1000 VC_SCR_Prsnt "FFFF7FF0FF0FFF00h";
BA_ "FlexKomSigStartPos" SG_ 1000 VC_SCR_Prsnt 7;
BA_ "FlexKomSigName" SG_ 1000 VC_SCR_Prsnt "VehCfg1_Pkt";
BA_ "FlexKomSigLaenge" SG_ 1000 VC_SCR_Prsnt 64;
BA_ "FlexKomSID" SG_ 1000 VC_SCR_Prsnt 886;
BA_ "FlexKomIsMotorola" SG_ 1000 VC_SCR_Prsnt 1;
BA_ "FlexKomComment" SG_ 1000 VC_SCR_Prsnt "Vehicle Configuration 1 Packet";
BA_ "GenSigTimeout_IC" SG_ 1000 VC_SSC_Prsnt 5250;
BA_ "GenSigSNA" SG_ 1000 VC_SSC_Prsnt "0h";
BA_ "GenSigSendType" SG_ 1000 VC_SSC_Prsnt 5;
BA_ "GenSigCycleTime" SG_ 1000 VC_SSC_Prsnt 500;
BA_ "FlexKomSigStartValue" SG_ 1000 VC_SSC_Prsnt "FFFF7FF0FF0FFF00h";
BA_ "FlexKomSigStartPos" SG_ 1000 VC_SSC_Prsnt 7;
BA_ "FlexKomSigName" SG_ 1000 VC_SSC_Prsnt "VehCfg1_Pkt";
BA_ "FlexKomSigLaenge" SG_ 1000 VC_SSC_Prsnt 64;
BA_ "FlexKomSID" SG_ 1000 VC_SSC_Prsnt 886;
BA_ "FlexKomIsMotorola" SG_ 1000 VC_SSC_Prsnt 1;
BA_ "FlexKomComment" SG_ 1000 VC_SSC_Prsnt "Vehicle Configuration 1 Packet";
BA_ "GenSigTimeout_IC" SG_ 1000 VC_ShftrTyp 5250;
BA_ "GenSigTimeout_ESM" SG_ 1000 VC_ShftrTyp 5250;
BA_ "GenSigStartValue" SG_ 1000 VC_ShftrTyp 15;
BA_ "GenSigSNA" SG_ 1000 VC_ShftrTyp "Fh";
BA_ "GenSigSendType" SG_ 1000 VC_ShftrTyp 5;
BA_ "GenSigCycleTime" SG_ 1000 VC_ShftrTyp 500;
BA_ "FlexKomSigStartValue" SG_ 1000 VC_ShftrTyp "FFFF7FF0FF0FFF00h";
BA_ "FlexKomSigStartPos" SG_ 1000 VC_ShftrTyp 7;
BA_ "FlexKomSigName" SG_ 1000 VC_ShftrTyp "VehCfg1_Pkt";
BA_ "FlexKomSigLaenge" SG_ 1000 VC_ShftrTyp 64;
BA_ "FlexKomSID" SG_ 1000 VC_ShftrTyp 886;
BA_ "FlexKomIsMotorola" SG_ 1000 VC_ShftrTyp 1;
BA_ "FlexKomComment" SG_ 1000 VC_ShftrTyp "Vehicle Configuration 1 Packet";
BA_ "GenSigTimeout_ORC" SG_ 1000 VC_SpecialPKG 1750;
BA_ "GenSigTimeout_IC" SG_ 1000 VC_SpecialPKG 5250;
BA_ "GenSigStartValue" SG_ 1000 VC_SpecialPKG 255;
BA_ "GenSigSNA" SG_ 1000 VC_SpecialPKG "FFh";
BA_ "GenSigSendType" SG_ 1000 VC_SpecialPKG 5;
BA_ "GenSigCycleTime" SG_ 1000 VC_SpecialPKG 500;
BA_ "FlexKomSigStartValue" SG_ 1000 VC_SpecialPKG "FFFF7FF0FF0FFF00h";
BA_ "FlexKomSigStartPos" SG_ 1000 VC_SpecialPKG 7;
BA_ "FlexKomSigName" SG_ 1000 VC_SpecialPKG "VehCfg1_Pkt";
BA_ "FlexKomSigLaenge" SG_ 1000 VC_SpecialPKG 64;
BA_ "FlexKomSID" SG_ 1000 VC_SpecialPKG 886;
BA_ "FlexKomIsMotorola" SG_ 1000 VC_SpecialPKG 1;
BA_ "FlexKomComment" SG_ 1000 VC_SpecialPKG "Vehicle Configuration 1 Packet";
BA_ "GenSigTimeout_TPM" SG_ 1000 VC_VEH_LINE 5250;
BA_ "GenSigTimeout_SCCM" SG_ 1000 VC_VEH_LINE 5250;
BA_ "GenSigTimeout_ORC" SG_ 1000 VC_VEH_LINE 1750;
BA_ "GenSigTimeout_OCM" SG_ 1000 VC_VEH_LINE 2750;
BA_ "GenSigTimeout_IC" SG_ 1000 VC_VEH_LINE 5250;
BA_ "GenSigTimeout_ESM" SG_ 1000 VC_VEH_LINE 5250;
BA_ "GenSigTimeout_EHPS" SG_ 1000 VC_VEH_LINE 5250;
BA_ "GenSigTimeout_DTCM" SG_ 1000 VC_VEH_LINE 5250;
BA_ "GenSigTimeout_DPDM" SG_ 1000 VC_VEH_LINE 2750;
BA_ "GenSigStartValue" SG_ 1000 VC_VEH_LINE 255;
BA_ "GenSigSNA" SG_ 1000 VC_VEH_LINE "FFh";
BA_ "GenSigSendType" SG_ 1000 VC_VEH_LINE 5;
BA_ "GenSigCycleTime" SG_ 1000 VC_VEH_LINE 500;
BA_ "FlexKomSigStartValue" SG_ 1000 VC_VEH_LINE "FFFF7FF0FF0FFF00h";
BA_ "FlexKomSigStartPos" SG_ 1000 VC_VEH_LINE 7;
BA_ "FlexKomSigName" SG_ 1000 VC_VEH_LINE "VehCfg1_Pkt";
BA_ "FlexKomSigLaenge" SG_ 1000 VC_VEH_LINE 64;
BA_ "FlexKomSID" SG_ 1000 VC_VEH_LINE 886;
BA_ "FlexKomIsMotorola" SG_ 1000 VC_VEH_LINE 1;
BA_ "FlexKomComment" SG_ 1000 VC_VEH_LINE "Vehicle Configuration 1 Packet";
BA_ "GenSigTimeout_TPM" SG_ 1000 VC_VehCfg1_Stat 5250;
BA_ "GenSigTimeout_SCCM" SG_ 1000 VC_VehCfg1_Stat 5250;
BA_ "GenSigTimeout_ORC" SG_ 1000 VC_VehCfg1_Stat 1750;
BA_ "GenSigTimeout_OCM" SG_ 1000 VC_VehCfg1_Stat 5250;
BA_ "GenSigTimeout_IC" SG_ 1000 VC_VehCfg1_Stat 5250;
BA_ "GenSigTimeout_ESM" SG_ 1000 VC_VehCfg1_Stat 5250;
BA_ "GenSigTimeout_EHPS" SG_ 1000 VC_VehCfg1_Stat 5250;
BA_ "GenSigTimeout_DTCM" SG_ 1000 VC_VehCfg1_Stat 5250;
BA_ "GenSigTimeout_DPDM" SG_ 1000 VC_VehCfg1_Stat 5250;
BA_ "GenSigStartValue" SG_ 1000 VC_VehCfg1_Stat 3;
BA_ "GenSigSNA" SG_ 1000 VC_VehCfg1_Stat "3h";
BA_ "GenSigSendType" SG_ 1000 VC_VehCfg1_Stat 5;
BA_ "GenSigCycleTime" SG_ 1000 VC_VehCfg1_Stat 500;
BA_ "FlexKomSigStartValue" SG_ 1000 VC_VehCfg1_Stat "FFFF7FF0FF0FFF00h";
BA_ "FlexKomSigStartPos" SG_ 1000 VC_VehCfg1_Stat 7;
BA_ "FlexKomSigName" SG_ 1000 VC_VehCfg1_Stat "VehCfg1_Pkt";
BA_ "FlexKomSigLaenge" SG_ 1000 VC_VehCfg1_Stat 64;
BA_ "FlexKomSID" SG_ 1000 VC_VehCfg1_Stat 886;
BA_ "FlexKomIsMotorola" SG_ 1000 VC_VehCfg1_Stat 1;
BA_ "FlexKomComment" SG_ 1000 VC_VehCfg1_Stat "Vehicle Configuration 1 Packet";
BA_ "GenSigTimeout_ORC" SG_ 1000 VC_XWD 1750;
BA_ "GenSigTimeout_IC" SG_ 1000 VC_XWD 5250;
BA_ "GenSigTimeout_ESM" SG_ 1000 VC_XWD 5250;
BA_ "GenSigSNA" SG_ 1000 VC_XWD "0h";
BA_ "GenSigSendType" SG_ 1000 VC_XWD 5;
BA_ "GenSigCycleTime" SG_ 1000 VC_XWD 500;
BA_ "FlexKomSigStartValue" SG_ 1000 VC_XWD "FFFF7FF0FF0FFF00h";
BA_ "FlexKomSigStartPos" SG_ 1000 VC_XWD 7;
BA_ "FlexKomSigName" SG_ 1000 VC_XWD "VehCfg1_Pkt";
BA_ "FlexKomSigLaenge" SG_ 1000 VC_XWD 64;
BA_ "FlexKomSID" SG_ 1000 VC_XWD 886;
BA_ "FlexKomIsMotorola" SG_ 1000 VC_XWD 1;
BA_ "FlexKomComment" SG_ 1000 VC_XWD "Vehicle Configuration 1 Packet";
BA_ "GenSigSNA" SG_ 1001 VC_AC_Prsnt "0h";
BA_ "GenSigSendType" SG_ 1001 VC_AC_Prsnt 5;
BA_ "GenSigCycleTime" SG_ 1001 VC_AC_Prsnt 2000;
BA_ "FlexKomSigStartValue" SG_ 1001 VC_AC_Prsnt "0300FF00FFFFFFFFh";
BA_ "FlexKomSigStartPos" SG_ 1001 VC_AC_Prsnt 7;
BA_ "FlexKomSigName" SG_ 1001 VC_AC_Prsnt "VehCfg2_Pkt";
BA_ "FlexKomSigLaenge" SG_ 1001 VC_AC_Prsnt 64;
BA_ "FlexKomSID" SG_ 1001 VC_AC_Prsnt 887;
BA_ "FlexKomIsMotorola" SG_ 1001 VC_AC_Prsnt 1;
BA_ "FlexKomComment" SG_ 1001 VC_AC_Prsnt "Vehicle Configuration 2 Packet";
BA_ "GenSigTimeout_ORC" SG_ 1001 VC_CRUISE_PRSNT 7000;
BA_ "GenSigTimeout_IC" SG_ 1001 VC_CRUISE_PRSNT 21000;
BA_ "GenSigSNA" SG_ 1001 VC_CRUISE_PRSNT "0h";
BA_ "GenSigSendType" SG_ 1001 VC_CRUISE_PRSNT 5;
BA_ "GenSigCycleTime" SG_ 1001 VC_CRUISE_PRSNT 2000;
BA_ "FlexKomSigStartValue" SG_ 1001 VC_CRUISE_PRSNT "0300FF00FFFFFFFFh";
BA_ "FlexKomSigStartPos" SG_ 1001 VC_CRUISE_PRSNT 7;
BA_ "FlexKomSigName" SG_ 1001 VC_CRUISE_PRSNT "VehCfg2_Pkt";
BA_ "FlexKomSigLaenge" SG_ 1001 VC_CRUISE_PRSNT 64;
BA_ "FlexKomSID" SG_ 1001 VC_CRUISE_PRSNT 887;
BA_ "FlexKomIsMotorola" SG_ 1001 VC_CRUISE_PRSNT 1;
BA_ "FlexKomComment" SG_ 1001 VC_CRUISE_PRSNT "Vehicle Configuration 2 Packet";
BA_ "GenSigSNA" SG_ 1001 VC_DRVMD_Prsnt "0h";
BA_ "GenSigSendType" SG_ 1001 VC_DRVMD_Prsnt 5;
BA_ "GenSigCycleTime" SG_ 1001 VC_DRVMD_Prsnt 2000;
BA_ "FlexKomSigStartValue" SG_ 1001 VC_DRVMD_Prsnt "0300FF00FFFFFFFFh";
BA_ "FlexKomSigStartPos" SG_ 1001 VC_DRVMD_Prsnt 7;
BA_ "FlexKomSigName" SG_ 1001 VC_DRVMD_Prsnt "VehCfg2_Pkt";
BA_ "FlexKomSigLaenge" SG_ 1001 VC_DRVMD_Prsnt 64;
BA_ "FlexKomSID" SG_ 1001 VC_DRVMD_Prsnt 887;
BA_ "FlexKomIsMotorola" SG_ 1001 VC_DRVMD_Prsnt 1;
BA_ "FlexKomComment" SG_ 1001 VC_DRVMD_Prsnt "Vehicle Configuration 2 Packet";
BA_ "GenSigTimeout_IC" SG_ 1001 VC_ECO_Indicator 21000;
BA_ "GenSigSNA" SG_ 1001 VC_ECO_Indicator "0h";
BA_ "GenSigSendType" SG_ 1001 VC_ECO_Indicator 5;
BA_ "GenSigCycleTime" SG_ 1001 VC_ECO_Indicator 2000;
BA_ "FlexKomSigStartValue" SG_ 1001 VC_ECO_Indicator "0300FF00FFFFFFFFh";
BA_ "FlexKomSigStartPos" SG_ 1001 VC_ECO_Indicator 7;
BA_ "FlexKomSigName" SG_ 1001 VC_ECO_Indicator "VehCfg2_Pkt";
BA_ "FlexKomSigLaenge" SG_ 1001 VC_ECO_Indicator 64;
BA_ "FlexKomSID" SG_ 1001 VC_ECO_Indicator 887;
BA_ "FlexKomIsMotorola" SG_ 1001 VC_ECO_Indicator 1;
BA_ "FlexKomComment" SG_ 1001 VC_ECO_Indicator "Vehicle Configuration 2 Packet";
BA_ "GenSigTimeout_IC" SG_ 1001 VC_ESCDrvMd_Prsnt 21000;
BA_ "GenSigSNA" SG_ 1001 VC_ESCDrvMd_Prsnt "0h";
BA_ "GenSigSendType" SG_ 1001 VC_ESCDrvMd_Prsnt 5;
BA_ "GenSigCycleTime" SG_ 1001 VC_ESCDrvMd_Prsnt 2000;
BA_ "FlexKomSigStartValue" SG_ 1001 VC_ESCDrvMd_Prsnt "0300FF00FFFFFFFFh";
BA_ "FlexKomSigStartPos" SG_ 1001 VC_ESCDrvMd_Prsnt 7;
BA_ "FlexKomSigName" SG_ 1001 VC_ESCDrvMd_Prsnt "VehCfg2_Pkt";
BA_ "FlexKomSigLaenge" SG_ 1001 VC_ESCDrvMd_Prsnt 64;
BA_ "FlexKomSID" SG_ 1001 VC_ESCDrvMd_Prsnt 887;
BA_ "FlexKomIsMotorola" SG_ 1001 VC_ESCDrvMd_Prsnt 1;
BA_ "FlexKomComment" SG_ 1001 VC_ESCDrvMd_Prsnt "Vehicle Configuration 2 Packet";
BA_ "GenSigTimeout_IC" SG_ 1001 VC_EngPowerDrvMd_Prsnt 21000;
BA_ "GenSigSNA" SG_ 1001 VC_EngPowerDrvMd_Prsnt "0h";
BA_ "GenSigSendType" SG_ 1001 VC_EngPowerDrvMd_Prsnt 5;
BA_ "GenSigCycleTime" SG_ 1001 VC_EngPowerDrvMd_Prsnt 2000;
BA_ "FlexKomSigStartValue" SG_ 1001 VC_EngPowerDrvMd_Prsnt "0300FF00FFFFFFFFh";
BA_ "FlexKomSigStartPos" SG_ 1001 VC_EngPowerDrvMd_Prsnt 7;
BA_ "FlexKomSigName" SG_ 1001 VC_EngPowerDrvMd_Prsnt "VehCfg2_Pkt";
BA_ "FlexKomSigLaenge" SG_ 1001 VC_EngPowerDrvMd_Prsnt 64;
BA_ "FlexKomSID" SG_ 1001 VC_EngPowerDrvMd_Prsnt 887;
BA_ "FlexKomIsMotorola" SG_ 1001 VC_EngPowerDrvMd_Prsnt 1;
BA_ "FlexKomComment" SG_ 1001 VC_EngPowerDrvMd_Prsnt "Vehicle Configuration 2 Packet";
BA_ "GenSigTimeout_IC" SG_ 1001 VC_FG_PRSNT 21000;
BA_ "GenSigSNA" SG_ 1001 VC_FG_PRSNT "0h";
BA_ "GenSigSendType" SG_ 1001 VC_FG_PRSNT 5;
BA_ "GenSigCycleTime" SG_ 1001 VC_FG_PRSNT 2000;
BA_ "FlexKomSigStartValue" SG_ 1001 VC_FG_PRSNT "0300FF00FFFFFFFFh";
BA_ "FlexKomSigStartPos" SG_ 1001 VC_FG_PRSNT 7;
BA_ "FlexKomSigName" SG_ 1001 VC_FG_PRSNT "VehCfg2_Pkt";
BA_ "FlexKomSigLaenge" SG_ 1001 VC_FG_PRSNT 64;
BA_ "FlexKomSID" SG_ 1001 VC_FG_PRSNT 887;
BA_ "FlexKomIsMotorola" SG_ 1001 VC_FG_PRSNT 1;
BA_ "FlexKomComment" SG_ 1001 VC_FG_PRSNT "Vehicle Configuration 2 Packet";
BA_ "GenSigTimeout_TPM" SG_ 1001 VC_FULL_SPARE 21000;
BA_ "GenSigSNA" SG_ 1001 VC_FULL_SPARE "0h";
BA_ "GenSigSendType" SG_ 1001 VC_FULL_SPARE 5;
BA_ "GenSigCycleTime" SG_ 1001 VC_FULL_SPARE 2000;
BA_ "FlexKomSigStartValue" SG_ 1001 VC_FULL_SPARE "0300FF00FFFFFFFFh";
BA_ "FlexKomSigStartPos" SG_ 1001 VC_FULL_SPARE 7;
BA_ "FlexKomSigName" SG_ 1001 VC_FULL_SPARE "VehCfg2_Pkt";
BA_ "FlexKomSigLaenge" SG_ 1001 VC_FULL_SPARE 64;
BA_ "FlexKomSID" SG_ 1001 VC_FULL_SPARE 887;
BA_ "FlexKomIsMotorola" SG_ 1001 VC_FULL_SPARE 1;
BA_ "FlexKomComment" SG_ 1001 VC_FULL_SPARE "Vehicle Configuration 2 Packet";
BA_ "GenSigTimeout_TPM" SG_ 1001 VC_LgtLdPressFtTr 21000;
BA_ "GenSigTimeout_IC" SG_ 1001 VC_LgtLdPressFtTr 21000;
BA_ "GenSigStartValue" SG_ 1001 VC_LgtLdPressFtTr 255;
BA_ "GenSigSNA" SG_ 1001 VC_LgtLdPressFtTr "FFh";
BA_ "GenSigSendType" SG_ 1001 VC_LgtLdPressFtTr 5;
BA_ "GenSigCycleTime" SG_ 1001 VC_LgtLdPressFtTr 2000;
BA_ "FlexKomSigStartValue" SG_ 1001 VC_LgtLdPressFtTr "0300FF00FFFFFFFFh";
BA_ "FlexKomSigStartPos" SG_ 1001 VC_LgtLdPressFtTr 7;
BA_ "FlexKomSigName" SG_ 1001 VC_LgtLdPressFtTr "VehCfg2_Pkt";
BA_ "FlexKomSigLaenge" SG_ 1001 VC_LgtLdPressFtTr 64;
BA_ "FlexKomSID" SG_ 1001 VC_LgtLdPressFtTr 887;
BA_ "FlexKomIsMotorola" SG_ 1001 VC_LgtLdPressFtTr 1;
BA_ "FlexKomComment" SG_ 1001 VC_LgtLdPressFtTr "Vehicle Configuration 2 Packet";
BA_ "GenSigTimeout_TPM" SG_ 1001 VC_LgtLdPressRrTr 21000;
BA_ "GenSigTimeout_IC" SG_ 1001 VC_LgtLdPressRrTr 21000;
BA_ "GenSigStartValue" SG_ 1001 VC_LgtLdPressRrTr 255;
BA_ "GenSigSNA" SG_ 1001 VC_LgtLdPressRrTr "FFh";
BA_ "GenSigSendType" SG_ 1001 VC_LgtLdPressRrTr 5;
BA_ "GenSigCycleTime" SG_ 1001 VC_LgtLdPressRrTr 2000;
BA_ "FlexKomSigStartValue" SG_ 1001 VC_LgtLdPressRrTr "0300FF00FFFFFFFFh";
BA_ "FlexKomSigStartPos" SG_ 1001 VC_LgtLdPressRrTr 7;
BA_ "FlexKomSigName" SG_ 1001 VC_LgtLdPressRrTr "VehCfg2_Pkt";
BA_ "FlexKomSigLaenge" SG_ 1001 VC_LgtLdPressRrTr 64;
BA_ "FlexKomSID" SG_ 1001 VC_LgtLdPressRrTr 887;
BA_ "FlexKomIsMotorola" SG_ 1001 VC_LgtLdPressRrTr 1;
BA_ "FlexKomComment" SG_ 1001 VC_LgtLdPressRrTr "Vehicle Configuration 2 Packet";
BA_ "GenSigTimeout_IC" SG_ 1001 VC_MaseratiMd 21000;
BA_ "GenSigSNA" SG_ 1001 VC_MaseratiMd "3h";
BA_ "GenSigSendType" SG_ 1001 VC_MaseratiMd 5;
BA_ "GenSigCycleTime" SG_ 1001 VC_MaseratiMd 2000;
BA_ "FlexKomSigStartValue" SG_ 1001 VC_MaseratiMd "0300FF00FFFFFFFFh";
BA_ "FlexKomSigStartPos" SG_ 1001 VC_MaseratiMd 7;
BA_ "FlexKomSigName" SG_ 1001 VC_MaseratiMd "VehCfg2_Pkt";
BA_ "FlexKomSigLaenge" SG_ 1001 VC_MaseratiMd 64;
BA_ "FlexKomSID" SG_ 1001 VC_MaseratiMd 887;
BA_ "FlexKomIsMotorola" SG_ 1001 VC_MaseratiMd 1;
BA_ "FlexKomComment" SG_ 1001 VC_MaseratiMd "Vehicle Configuration 2 Packet";
BA_ "GenSigTimeout_TPM" SG_ 1001 VC_MaxLdPressFtTr 21000;
BA_ "GenSigTimeout_IC" SG_ 1001 VC_MaxLdPressFtTr 21000;
BA_ "GenSigStartValue" SG_ 1001 VC_MaxLdPressFtTr 255;
BA_ "GenSigSNA" SG_ 1001 VC_MaxLdPressFtTr "FFh";
BA_ "GenSigSendType" SG_ 1001 VC_MaxLdPressFtTr 5;
BA_ "GenSigCycleTime" SG_ 1001 VC_MaxLdPressFtTr 2000;
BA_ "FlexKomSigStartValue" SG_ 1001 VC_MaxLdPressFtTr "0300FF00FFFFFFFFh";
BA_ "FlexKomSigStartPos" SG_ 1001 VC_MaxLdPressFtTr 7;
BA_ "FlexKomSigName" SG_ 1001 VC_MaxLdPressFtTr "VehCfg2_Pkt";
BA_ "FlexKomSigLaenge" SG_ 1001 VC_MaxLdPressFtTr 64;
BA_ "FlexKomSID" SG_ 1001 VC_MaxLdPressFtTr 887;
BA_ "FlexKomIsMotorola" SG_ 1001 VC_MaxLdPressFtTr 1;
BA_ "FlexKomComment" SG_ 1001 VC_MaxLdPressFtTr "Vehicle Configuration 2 Packet";
BA_ "GenSigTimeout_TPM" SG_ 1001 VC_MaxLdPressRrTr 21000;
BA_ "GenSigTimeout_IC" SG_ 1001 VC_MaxLdPressRrTr 21000;
BA_ "GenSigStartValue" SG_ 1001 VC_MaxLdPressRrTr 255;
BA_ "GenSigSNA" SG_ 1001 VC_MaxLdPressRrTr "FFh";
BA_ "GenSigSendType" SG_ 1001 VC_MaxLdPressRrTr 5;
BA_ "GenSigCycleTime" SG_ 1001 VC_MaxLdPressRrTr 2000;
BA_ "FlexKomSigStartValue" SG_ 1001 VC_MaxLdPressRrTr "0300FF00FFFFFFFFh";
BA_ "FlexKomSigStartPos" SG_ 1001 VC_MaxLdPressRrTr 7;
BA_ "FlexKomSigName" SG_ 1001 VC_MaxLdPressRrTr "VehCfg2_Pkt";
BA_ "FlexKomSigLaenge" SG_ 1001 VC_MaxLdPressRrTr 64;
BA_ "FlexKomSID" SG_ 1001 VC_MaxLdPressRrTr 887;
BA_ "FlexKomIsMotorola" SG_ 1001 VC_MaxLdPressRrTr 1;
BA_ "FlexKomComment" SG_ 1001 VC_MaxLdPressRrTr "Vehicle Configuration 2 Packet";
BA_ "GenSigSNA" SG_ 1001 VC_MemoryDRVMD_Prsnt "0h";
BA_ "GenSigSendType" SG_ 1001 VC_MemoryDRVMD_Prsnt 5;
BA_ "GenSigCycleTime" SG_ 1001 VC_MemoryDRVMD_Prsnt 2000;
BA_ "FlexKomSigStartValue" SG_ 1001 VC_MemoryDRVMD_Prsnt "0300FF00FFFFFFFFh";
BA_ "FlexKomSigStartPos" SG_ 1001 VC_MemoryDRVMD_Prsnt 7;
BA_ "FlexKomSigName" SG_ 1001 VC_MemoryDRVMD_Prsnt "VehCfg2_Pkt";
BA_ "FlexKomSigLaenge" SG_ 1001 VC_MemoryDRVMD_Prsnt 64;
BA_ "FlexKomSID" SG_ 1001 VC_MemoryDRVMD_Prsnt 887;
BA_ "FlexKomIsMotorola" SG_ 1001 VC_MemoryDRVMD_Prsnt 1;
BA_ "FlexKomComment" SG_ 1001 VC_MemoryDRVMD_Prsnt "Vehicle Configuration 2 Packet";
BA_ "GenSigTimeout_ORC" SG_ 1001 VC_OffRoad 7000;
BA_ "GenSigTimeout_IC" SG_ 1001 VC_OffRoad 21000;
BA_ "GenSigSNA" SG_ 1001 VC_OffRoad "0h";
BA_ "GenSigSendType" SG_ 1001 VC_OffRoad 5;
BA_ "GenSigCycleTime" SG_ 1001 VC_OffRoad 2000;
BA_ "FlexKomSigStartValue" SG_ 1001 VC_OffRoad "0300FF00FFFFFFFFh";
BA_ "FlexKomSigStartPos" SG_ 1001 VC_OffRoad 7;
BA_ "FlexKomSigName" SG_ 1001 VC_OffRoad "VehCfg2_Pkt";
BA_ "FlexKomSigLaenge" SG_ 1001 VC_OffRoad 64;
BA_ "FlexKomSID" SG_ 1001 VC_OffRoad 887;
BA_ "FlexKomIsMotorola" SG_ 1001 VC_OffRoad 1;
BA_ "FlexKomComment" SG_ 1001 VC_OffRoad "Vehicle Configuration 2 Packet";
BA_ "GenSigTimeout_ORC" SG_ 1001 VC_PADS_Prsnt 7000;
BA_ "GenSigTimeout_IC" SG_ 1001 VC_PADS_Prsnt 21000;
BA_ "GenSigSNA" SG_ 1001 VC_PADS_Prsnt "0h";
BA_ "GenSigSendType" SG_ 1001 VC_PADS_Prsnt 5;
BA_ "GenSigCycleTime" SG_ 1001 VC_PADS_Prsnt 2000;
BA_ "FlexKomSigStartValue" SG_ 1001 VC_PADS_Prsnt "0300FF00FFFFFFFFh";
BA_ "FlexKomSigStartPos" SG_ 1001 VC_PADS_Prsnt 7;
BA_ "FlexKomSigName" SG_ 1001 VC_PADS_Prsnt "VehCfg2_Pkt";
BA_ "FlexKomSigLaenge" SG_ 1001 VC_PADS_Prsnt 64;
BA_ "FlexKomSID" SG_ 1001 VC_PADS_Prsnt 887;
BA_ "FlexKomIsMotorola" SG_ 1001 VC_PADS_Prsnt 1;
BA_ "FlexKomComment" SG_ 1001 VC_PADS_Prsnt "Vehicle Configuration 2 Packet";
BA_ "GenSigSNA" SG_ 1001 VC_PwrIvtrTyp "0h";
BA_ "GenSigSendType" SG_ 1001 VC_PwrIvtrTyp 5;
BA_ "GenSigCycleTime" SG_ 1001 VC_PwrIvtrTyp 2000;
BA_ "FlexKomSigStartValue" SG_ 1001 VC_PwrIvtrTyp "0300FF00FFFFFFFFh";
BA_ "FlexKomSigStartPos" SG_ 1001 VC_PwrIvtrTyp 7;
BA_ "FlexKomSigName" SG_ 1001 VC_PwrIvtrTyp "VehCfg2_Pkt";
BA_ "FlexKomSigLaenge" SG_ 1001 VC_PwrIvtrTyp 64;
BA_ "FlexKomSID" SG_ 1001 VC_PwrIvtrTyp 887;
BA_ "FlexKomIsMotorola" SG_ 1001 VC_PwrIvtrTyp 1;
BA_ "FlexKomComment" SG_ 1001 VC_PwrIvtrTyp "Vehicle Configuration 2 Packet";
BA_ "GenSigTimeout_IC" SG_ 1001 VC_RainSnsPrsnt 21000;
BA_ "GenSigSNA" SG_ 1001 VC_RainSnsPrsnt "0h";
BA_ "GenSigSendType" SG_ 1001 VC_RainSnsPrsnt 5;
BA_ "GenSigCycleTime" SG_ 1001 VC_RainSnsPrsnt 2000;
BA_ "FlexKomSigStartValue" SG_ 1001 VC_RainSnsPrsnt "0300FF00FFFFFFFFh";
BA_ "FlexKomSigStartPos" SG_ 1001 VC_RainSnsPrsnt 7;
BA_ "FlexKomSigName" SG_ 1001 VC_RainSnsPrsnt "VehCfg2_Pkt";
BA_ "FlexKomSigLaenge" SG_ 1001 VC_RainSnsPrsnt 64;
BA_ "FlexKomSID" SG_ 1001 VC_RainSnsPrsnt 887;
BA_ "FlexKomIsMotorola" SG_ 1001 VC_RainSnsPrsnt 1;
BA_ "FlexKomComment" SG_ 1001 VC_RainSnsPrsnt "Vehicle Configuration 2 Packet";
BA_ "GenSigTimeout_TPM" SG_ 1001 VC_RunFlatTirePrsnt 21000;
BA_ "GenSigTimeout_IC" SG_ 1001 VC_RunFlatTirePrsnt 21000;
BA_ "GenSigSNA" SG_ 1001 VC_RunFlatTirePrsnt "0h";
BA_ "GenSigSendType" SG_ 1001 VC_RunFlatTirePrsnt 5;
BA_ "GenSigCycleTime" SG_ 1001 VC_RunFlatTirePrsnt 2000;
BA_ "FlexKomSigStartValue" SG_ 1001 VC_RunFlatTirePrsnt "0300FF00FFFFFFFFh";
BA_ "FlexKomSigStartPos" SG_ 1001 VC_RunFlatTirePrsnt 7;
BA_ "FlexKomSigName" SG_ 1001 VC_RunFlatTirePrsnt "VehCfg2_Pkt";
BA_ "FlexKomSigLaenge" SG_ 1001 VC_RunFlatTirePrsnt 64;
BA_ "FlexKomSID" SG_ 1001 VC_RunFlatTirePrsnt 887;
BA_ "FlexKomIsMotorola" SG_ 1001 VC_RunFlatTirePrsnt 1;
BA_ "FlexKomComment" SG_ 1001 VC_RunFlatTirePrsnt "Vehicle Configuration 2 Packet";
BA_ "GenSigSNA" SG_ 1001 VC_SKIM_PRSNT "0h";
BA_ "GenSigSendType" SG_ 1001 VC_SKIM_PRSNT 5;
BA_ "GenSigCycleTime" SG_ 1001 VC_SKIM_PRSNT 2000;
BA_ "FlexKomSigStartValue" SG_ 1001 VC_SKIM_PRSNT "0300FF00FFFFFFFFh";
BA_ "FlexKomSigStartPos" SG_ 1001 VC_SKIM_PRSNT 7;
BA_ "FlexKomSigName" SG_ 1001 VC_SKIM_PRSNT "VehCfg2_Pkt";
BA_ "FlexKomSigLaenge" SG_ 1001 VC_SKIM_PRSNT 64;
BA_ "FlexKomSID" SG_ 1001 VC_SKIM_PRSNT 887;
BA_ "FlexKomIsMotorola" SG_ 1001 VC_SKIM_PRSNT 1;
BA_ "FlexKomComment" SG_ 1001 VC_SKIM_PRSNT "Vehicle Configuration 2 Packet";
BA_ "GenSigTimeout_IC" SG_ 1001 VC_SecPrkPrsnt 21000;
BA_ "GenSigSNA" SG_ 1001 VC_SecPrkPrsnt "0h";
BA_ "GenSigSendType" SG_ 1001 VC_SecPrkPrsnt 5;
BA_ "GenSigCycleTime" SG_ 1001 VC_SecPrkPrsnt 2000;
BA_ "FlexKomSigStartValue" SG_ 1001 VC_SecPrkPrsnt "0300FF00FFFFFFFFh";
BA_ "FlexKomSigStartPos" SG_ 1001 VC_SecPrkPrsnt 7;
BA_ "FlexKomSigName" SG_ 1001 VC_SecPrkPrsnt "VehCfg2_Pkt";
BA_ "FlexKomSigLaenge" SG_ 1001 VC_SecPrkPrsnt 64;
BA_ "FlexKomSID" SG_ 1001 VC_SecPrkPrsnt 887;
BA_ "FlexKomIsMotorola" SG_ 1001 VC_SecPrkPrsnt 1;
BA_ "FlexKomComment" SG_ 1001 VC_SecPrkPrsnt "Vehicle Configuration 2 Packet";
BA_ "GenSigTimeout_IC" SG_ 1001 VC_ShftInd_Prsnt 21000;
BA_ "GenSigSNA" SG_ 1001 VC_ShftInd_Prsnt "0h";
BA_ "GenSigSendType" SG_ 1001 VC_ShftInd_Prsnt 5;
BA_ "GenSigCycleTime" SG_ 1001 VC_ShftInd_Prsnt 2000;
BA_ "FlexKomSigStartValue" SG_ 1001 VC_ShftInd_Prsnt "0300FF00FFFFFFFFh";
BA_ "FlexKomSigStartPos" SG_ 1001 VC_ShftInd_Prsnt 7;
BA_ "FlexKomSigName" SG_ 1001 VC_ShftInd_Prsnt "VehCfg2_Pkt";
BA_ "FlexKomSigLaenge" SG_ 1001 VC_ShftInd_Prsnt 64;
BA_ "FlexKomSID" SG_ 1001 VC_ShftInd_Prsnt 887;
BA_ "FlexKomIsMotorola" SG_ 1001 VC_ShftInd_Prsnt 1;
BA_ "FlexKomComment" SG_ 1001 VC_ShftInd_Prsnt "Vehicle Configuration 2 Packet";
BA_ "GenSigTimeout_ORC" SG_ 1001 VC_SpecialPKG_IC 7000;
BA_ "GenSigTimeout_IC" SG_ 1001 VC_SpecialPKG_IC 21000;
BA_ "GenSigStartValue" SG_ 1001 VC_SpecialPKG_IC 255;
BA_ "GenSigSNA" SG_ 1001 VC_SpecialPKG_IC "FFh";
BA_ "GenSigSendType" SG_ 1001 VC_SpecialPKG_IC 5;
BA_ "GenSigCycleTime" SG_ 1001 VC_SpecialPKG_IC 2000;
BA_ "FlexKomSigStartValue" SG_ 1001 VC_SpecialPKG_IC "0300FF00FFFFFFFFh";
BA_ "FlexKomSigStartPos" SG_ 1001 VC_SpecialPKG_IC 7;
BA_ "FlexKomSigName" SG_ 1001 VC_SpecialPKG_IC "VehCfg2_Pkt";
BA_ "FlexKomSigLaenge" SG_ 1001 VC_SpecialPKG_IC 64;
BA_ "FlexKomSID" SG_ 1001 VC_SpecialPKG_IC 887;
BA_ "FlexKomIsMotorola" SG_ 1001 VC_SpecialPKG_IC 1;
BA_ "FlexKomComment" SG_ 1001 VC_SpecialPKG_IC "Vehicle Configuration 2 Packet";
BA_ "GenSigTimeout_IC" SG_ 1001 VC_ThatchamPrsnt 21000;
BA_ "GenSigSNA" SG_ 1001 VC_ThatchamPrsnt "0h";
BA_ "GenSigSendType" SG_ 1001 VC_ThatchamPrsnt 5;
BA_ "GenSigCycleTime" SG_ 1001 VC_ThatchamPrsnt 2000;
BA_ "FlexKomSigStartValue" SG_ 1001 VC_ThatchamPrsnt "0300FF00FFFFFFFFh";
BA_ "FlexKomSigStartPos" SG_ 1001 VC_ThatchamPrsnt 7;
BA_ "FlexKomSigName" SG_ 1001 VC_ThatchamPrsnt "VehCfg2_Pkt";
BA_ "FlexKomSigLaenge" SG_ 1001 VC_ThatchamPrsnt 64;
BA_ "FlexKomSID" SG_ 1001 VC_ThatchamPrsnt 887;
BA_ "FlexKomIsMotorola" SG_ 1001 VC_ThatchamPrsnt 1;
BA_ "FlexKomComment" SG_ 1001 VC_ThatchamPrsnt "Vehicle Configuration 2 Packet";
BA_ "GenSigTimeout_ORC" SG_ 1001 VC_VehCfg2_Stat 7000;
BA_ "GenSigTimeout_IC" SG_ 1001 VC_VehCfg2_Stat 21000;
BA_ "GenSigStartValue" SG_ 1001 VC_VehCfg2_Stat 3;
BA_ "GenSigSNA" SG_ 1001 VC_VehCfg2_Stat "3h";
BA_ "GenSigSendType" SG_ 1001 VC_VehCfg2_Stat 5;
BA_ "GenSigCycleTime" SG_ 1001 VC_VehCfg2_Stat 2000;
BA_ "FlexKomSigStartValue" SG_ 1001 VC_VehCfg2_Stat "0300FF00FFFFFFFFh";
BA_ "FlexKomSigStartPos" SG_ 1001 VC_VehCfg2_Stat 7;
BA_ "FlexKomSigName" SG_ 1001 VC_VehCfg2_Stat "VehCfg2_Pkt";
BA_ "FlexKomSigLaenge" SG_ 1001 VC_VehCfg2_Stat 64;
BA_ "FlexKomSID" SG_ 1001 VC_VehCfg2_Stat 887;
BA_ "FlexKomIsMotorola" SG_ 1001 VC_VehCfg2_Stat 1;
BA_ "FlexKomComment" SG_ 1001 VC_VehCfg2_Stat "Vehicle Configuration 2 Packet";
VAL_ 423 ESLSts 0 "Undefined_Position" 3 "Lock" 5 "Unlock" 7 "SNA" ;
VAL_ 557 Command_11 0 "NOT_PSD" 1 "PSD" 3 "SNA" ;
VAL_ 557 Command_12 0 "NOT_PSD" 1 "PSD" 3 "SNA" ;
VAL_ 557 Command_13 0 "NOT_PSD" 1 "PSD" 3 "SNA" ;
VAL_ 557 Command_14 0 "NOT_PSD" 1 "PSD" 3 "SNA" ;
VAL_ 557 Command_15 0 "NOT_PSD" 1 "PSD" 3 "SNA" ;
VAL_ 792 HiBmLvr_Stat 0 "IDLE" 1 "HIBM_ON_PSD" 2 "HIBM_FLSH_ON_PSD" ;
VAL_ 792 TurnIndLvr_Stat 0 "IDLE" 1 "LEFT" 2 "RIGHT" ;
VAL_ 792 WprSw6Posn 0 "OFF" 1 "INTERVAL1" 2 "INTERVAL2" 3 "INTERVAL3" 4 "INTERVAL4" 5 "INTERVAL5" 6 "INTERVAL6" 13 "WPR_LOW" 14 "WPR_HI" 15 "SNA" ;
VAL_ 792 WprWashSw_Psd 0 "NPSD" 1 "MIST" 2 "WASH" ;
VAL_ 792 WprWash_R_Sw_Posn_V3 0 "OFF" 1 "INTERMITTENT" 2 "WASH" 3 "CONSTANT" ;
VAL_ 793 Batt_CabinPriority1 0 "Checkbox_Unselected" 1 "Checkbox_Selected" ;
VAL_ 793 ChargeUntilFull1 0 "Charge_Until_Full_Not_selected" 1 "Charge_Until_Full" ;
VAL_ 793 Do_Not_Repeat1 0 "Repeat" 1 "Do_Not_Repeat" ;
VAL_ 793 Enable_Schedule1 0 "Disable_schedule" 1 "Enable_schedule" ;
VAL_ 793 End_Time_Hr1 31 "SNA" ;
VAL_ 793 End_Time_Min1 15 "SNA" ;
VAL_ 793 Schedule_Day1 0 "No_Selection" 1 "M" 2 "T" 3 "TM" 4 "W" 5 "WM" 6 "WT" 7 "WTM" 8 "Th" 9 "ThM" 10 "ThT" 11 "ThTM" 12 "ThW" 13 "ThWM" 14 "ThWT" 15 "ThWTM" 16 "F" 17 "FM" 18 "FT" 19 "FTM" 20 "FW" 21 "FWM" 22 "FWT" 23 "FWTM" 24 "FTh" 25 "FThM" 26 "FThT" 27 "FThTM" 28 "FThW" 29 "FThWM" 30 "FThWT" 31 "FThWTM" 32 "S" 33 "SM" 34 "ST" 35 "STM" 36 "SW" 37 "SWM" 38 "SWT" 39 "SWTM" 40 "STh" 41 "SThM" 42 "SThT" 43 "SThTM" 44 "SThW" 45 "SThWM" 46 "SThWT" 47 "SThWTM" 48 "SF" 49 "SFM" 50 "SFT" 51 "SFTM" 52 "SFW" 53 "SFWM" 54 "SFWT" 55 "SFWTM" 56 "SFTh" 57 "SFThM" 58 "SFThT" 59 "SFThTM" 60 "SFThW" 61 "SFThWM" 62 "SFThWT" 63 "SFThWTM" 64 "Sa" 65 "SaM" 66 "SaT" 67 "SaTM" 68 "SaW" 69 "SaWM" 70 "SaWT" 71 "SaWTM" 72 "SaTh" 73 "SaThM" 74 "SaThT" 75 "SaThTM" 76 "SaThW" 77 "SaThWM" 78 "SaThWT" 79 "SaThWTM" 80 "SaF" 81 "SaFM" 82 "SaFT" 83 "SaFTM" 84 "SaFW" 85 "SaFWM" 86 "SaFWT" 87 "SaFWTM" 88 "SaFTh" 89 "SaFThM" 90 "SaFThT" 91 "SaFThTM" 92 "SaFThW" 93 "SaFThWM" 94 "SaFThWT" 95 "SaFThWTM" 96 "SaS" 97 "SaSM" 98 "SaST" 99 "SaSTM" 100 "SaSW" 101 "SaSWM" 102 "SaSWT" 103 "SaSWTM" 104 "SaSTh" 105 "SaSThM" 106 "SaSThT" 107 "SaSThTM" 108 "SaSThW" 109 "SaSThWM" 110 "SaSThWT" 111 "SaSThWTM" 112 "SaSF" 113 "SaSFM" 114 "SaSFT" 115 "SaSFTM" 116 "SaSFW" 117 "SaSFWM" 118 "SaSFWT" 119 "SaSFWTM" 120 "SaSFTh" 121 "SaSFThM" 122 "SaSFThT" 123 "SaSFThTM" 124 "SaSFThW" 125 "SaSFThWM" 126 "SaSFThWT" 127 "SaSFThWTM" ;
VAL_ 793 Schedule_Type1 0 "No_Selection" 1 "Departure_Time" 2 "Charge_Interval" 3 "SNA" ;
VAL_ 793 Start_Time_Hr1 31 "SNA" ;
VAL_ 793 Start_Time_Min1 15 "SNA" ;
VAL_ 793 Submit_Schedule1 0 "No_Change" 1 "Change_in_schedule" ;
VAL_ 794 Batt_CabinPriority2 0 "Checkbox_Unselected" 1 "Checkbox_Selected" ;
VAL_ 794 ChargeUntilFull2 0 "Charge_Until_Full_Not_selected" 1 "Charge_Until_Full" ;
VAL_ 794 Do_Not_Repeat2 0 "Repeat" 1 "Do_Not_Repeat" ;
VAL_ 794 Enable_Schedule2 0 "Disable_schedule" 1 "Enable_schedule" ;
VAL_ 794 End_Time_Hr2 31 "SNA" ;
VAL_ 794 End_Time_Min2 15 "SNA" ;
VAL_ 794 Schedule_Day2 0 "No_Selection" 1 "M" 2 "T" 3 "TM" 4 "W" 5 "WM" 6 "WT" 7 "WTM" 8 "Th" 9 "ThM" 10 "ThT" 11 "ThTM" 12 "ThW" 13 "ThWM" 14 "ThWT" 15 "ThWTM" 16 "F" 17 "FM" 18 "FT" 19 "FTM" 20 "FW" 21 "FWM" 22 "FWT" 23 "FWTM" 24 "FTh" 25 "FThM" 26 "FThT" 27 "FThTM" 28 "FThW" 29 "FThWM" 30 "FThWT" 31 "FThWTM" 32 "S" 33 "SM" 34 "ST" 35 "STM" 36 "SW" 37 "SWM" 38 "SWT" 39 "SWTM" 40 "STh" 41 "SThM" 42 "SThT" 43 "SThTM" 44 "SThW" 45 "SThWM" 46 "SThWT" 47 "SThWTM" 48 "SF" 49 "SFM" 50 "SFT" 51 "SFTM" 52 "SFW" 53 "SFWM" 54 "SFWT" 55 "SFWTM" 56 "SFTh" 57 "SFThM" 58 "SFThT" 59 "SFThTM" 60 "SFThW" 61 "SFThWM" 62 "SFThWT" 63 "SFThWTM" 64 "Sa" 65 "SaM" 66 "SaT" 67 "SaTM" 68 "SaW" 69 "SaWM" 70 "SaWT" 71 "SaWTM" 72 "SaTh" 73 "SaThM" 74 "SaThT" 75 "SaThTM" 76 "SaThW" 77 "SaThWM" 78 "SaThWT" 79 "SaThWTM" 80 "SaF" 81 "SaFM" 82 "SaFT" 83 "SaFTM" 84 "SaFW" 85 "SaFWM" 86 "SaFWT" 87 "SaFWTM" 88 "SaFTh" 89 "SaFThM" 90 "SaFThT" 91 "SaFThTM" 92 "SaFThW" 93 "SaFThWM" 94 "SaFThWT" 95 "SaFThWTM" 96 "SaS" 97 "SaSM" 98 "SaST" 99 "SaSTM" 100 "SaSW" 101 "SaSWM" 102 "SaSWT" 103 "SaSWTM" 104 "SaSTh" 105 "SaSThM" 106 "SaSThT" 107 "SaSThTM" 108 "SaSThW" 109 "SaSThWM" 110 "SaSThWT" 111 "SaSThWTM" 112 "SaSF" 113 "SaSFM" 114 "SaSFT" 115 "SaSFTM" 116 "SaSFW" 117 "SaSFWM" 118 "SaSFWT" 119 "SaSFWTM" 120 "SaSFTh" 121 "SaSFThM" 122 "SaSFThT" 123 "SaSFThTM" 124 "SaSFThW" 125 "SaSFThWM" 126 "SaSFThWT" 127 "SaSFThWTM" ;
VAL_ 794 Schedule_Type2 0 "No_Selection" 1 "Departure_Time" 2 "Charge_Interval" 3 "SNA" ;
VAL_ 794 Start_Time_Hr2 31 "SNA" ;
VAL_ 794 Start_Time_Min2 15 "SNA" ;
VAL_ 794 Submit_Schedule2 0 "No_Change" 1 "Change_in_schedule" ;
VAL_ 795 Batt_CabinPriority3 0 "Checkbox_Unselected" 1 "Checkbox_Selected" ;
VAL_ 795 ChargeUntilFull3 0 "Charge_Until_Full_Not_selected" 1 "Charge_Until_Full" ;
VAL_ 795 Do_Not_Repeat3 0 "Repeat" 1 "Do_Not_Repeat" ;
VAL_ 795 Enable_Schedule3 0 "Disable_schedule" 1 "Enable_schedule" ;
VAL_ 795 End_Time_Hr3 31 "SNA" ;
VAL_ 795 End_Time_Min3 15 "SNA" ;
VAL_ 795 Schedule_Day3 0 "No_Selection" 1 "M" 2 "T" 3 "TM" 4 "W" 5 "WM" 6 "WT" 7 "WTM" 8 "Th" 9 "ThM" 10 "ThT" 11 "ThTM" 12 "ThW" 13 "ThWM" 14 "ThWT" 15 "ThWTM" 16 "F" 17 "FM" 18 "FT" 19 "FTM" 20 "FW" 21 "FWM" 22 "FWT" 23 "FWTM" 24 "FTh" 25 "FThM" 26 "FThT" 27 "FThTM" 28 "FThW" 29 "FThWM" 30 "FThWT" 31 "FThWTM" 32 "S" 33 "SM" 34 "ST" 35 "STM" 36 "SW" 37 "SWM" 38 "SWT" 39 "SWTM" 40 "STh" 41 "SThM" 42 "SThT" 43 "SThTM" 44 "SThW" 45 "SThWM" 46 "SThWT" 47 "SThWTM" 48 "SF" 49 "SFM" 50 "SFT" 51 "SFTM" 52 "SFW" 53 "SFWM" 54 "SFWT" 55 "SFWTM" 56 "SFTh" 57 "SFThM" 58 "SFThT" 59 "SFThTM" 60 "SFThW" 61 "SFThWM" 62 "SFThWT" 63 "SFThWTM" 64 "Sa" 65 "SaM" 66 "SaT" 67 "SaTM" 68 "SaW" 69 "SaWM" 70 "SaWT" 71 "SaWTM" 72 "SaTh" 73 "SaThM" 74 "SaThT" 75 "SaThTM" 76 "SaThW" 77 "SaThWM" 78 "SaThWT" 79 "SaThWTM" 80 "SaF" 81 "SaFM" 82 "SaFT" 83 "SaFTM" 84 "SaFW" 85 "SaFWM" 86 "SaFWT" 87 "SaFWTM" 88 "SaFTh" 89 "SaFThM" 90 "SaFThT" 91 "SaFThTM" 92 "SaFThW" 93 "SaFThWM" 94 "SaFThWT" 95 "SaFThWTM" 96 "SaS" 97 "SaSM" 98 "SaST" 99 "SaSTM" 100 "SaSW" 101 "SaSWM" 102 "SaSWT" 103 "SaSWTM" 104 "SaSTh" 105 "SaSThM" 106 "SaSThT" 107 "SaSThTM" 108 "SaSThW" 109 "SaSThWM" 110 "SaSThWT" 111 "SaSThWTM" 112 "SaSF" 113 "SaSFM" 114 "SaSFT" 115 "SaSFTM" 116 "SaSFW" 117 "SaSFWM" 118 "SaSFWT" 119 "SaSFWTM" 120 "SaSFTh" 121 "SaSFThM" 122 "SaSFThT" 123 "SaSFThTM" 124 "SaSFThW" 125 "SaSFThWM" 126 "SaSFThWT" 127 "SaSFThWTM" ;
VAL_ 795 Schedule_Type3 0 "No_Selection" 1 "Departure_Time" 2 "Charge_Interval" 3 "SNA" ;
VAL_ 795 Start_Time_Hr3 31 "SNA" ;
VAL_ 795 Start_Time_Min3 15 "SNA" ;
VAL_ 795 Submit_Schedule3 0 "No_Change" 1 "Change_in_schedule" ;
VAL_ 171 CurrentGear 0 "N" 1 "D1" 2 "D2" 3 "D3" 4 "D4" 5 "D5" 6 "D6" 7 "D7" 8 "D8" 9 "D2P" 10 "D9" 11 "R" 12 "R2" 13 "P" 14 "KRAFTFREI" 15 "SNA" ;
VAL_ 171 CurrentGearForDisplay 0 "Initialize" 1 "D1" 2 "D2" 3 "D3" 4 "D4" 5 "D5" 6 "D6" 7 "D7" 8 "D8" 9 "D9" 12 "P" 13 "N" 14 "R" 15 "SNA" ;
VAL_ 171 TX_WARN2 0 "None" 1 "WARN_1" 2 "WARN_2" 3 "WARN_3" 4 "WARN_4" 5 "WARN_5" 6 "WARN_6" 7 "WARN_7" 8 "WARN_8" 9 "WARN_9" 10 "WARN_10" 11 "WARN_11" 12 "WARN_12" 13 "WARN_13" 14 "WARN_14" 15 "WARN_15" 17 "WARN_17" 18 "WARN_18" 19 "WARN_19" 20 "WARN_20" 21 "WARN_21" 22 "WARN_22" 23 "WARN_23" 24 "WARN_24" 25 "WARN_25" 31 "WARN_31" 32 "WARN_32" 33 "WARN_33" 34 "WARN_34" 35 "WARN_35" 36 "WARN_36" 37 "WARN_37" 38 "WARN_38" 39 "WARN_39" 40 "WARN_40" 41 "WARN_41" 42 "WARN_42" 43 "WARN_43" 44 "WARN_44" 45 "WARN_45" 46 "WARN_46" 47 "WARN_47" 48 "WARN_48" 49 "WARN_49" 50 "WARN_50" 51 "WARN_51" 52 "WARN_52" 53 "WARN_53" 54 "WARN_54" 55 "WARN_55" 56 "WARN_56" 57 "WARN_57" 58 "WARN_58" 59 "WARN_59" 60 "WARN_60" 61 "WARN_61" 62 "WARN_62" 63 "WARN_63" 64 "WARN_64" 65 "WARN_65" 66 "WARN_66" 67 "WARN_67" 68 "WARN_68" 69 "WARN_69" 70 "WARN_70" 71 "WARN_71" 72 "WARN_72" 255 "SNA" ;
VAL_ 171 TargetGear 0 "N" 1 "D1" 2 "D2" 3 "D3" 4 "D4" 5 "D5" 6 "D6" 7 "D7" 8 "D8" 9 "D2P" 10 "D9" 11 "R" 12 "R2" 13 "P" 14 "ABBRUCH" 15 "SNA" ;
VAL_ 179 DriveLineRatio 16383 "SNA" ;
VAL_ 179 TCM_Comm_Fail_ePT 0 "No_Fault" 1 "TCM_LoC_ePT_ECM" 2 "TCM_LoC_ePT_HCP" 3 "TCM_LoC_ePT_HCP_ECM" 7 "TCM_Bus_Failure_ePT" ;
VAL_ 149 Trans_Trq_Ratio 2047 "SNA" ;
VAL_ 149 TxIdleRq 255 "SNA" ;
VAL_ 55 EngTrqRq 8191 "SNA" ;
VAL_ 55 MaxTrqDes 8191 "SNA" ;
VAL_ 55 TCM_ParkSL_Request 0 "Initialization" 1 "Request_Engage_Park" 2 "Request_Disengage_Park" 3 "SNA" ;
VAL_ 55 TrqCtrlModeReqSlow 0 "NONE" 1 "TRQ_INC_Slow" 2 "TRQ_DEC_Slow" 3 "SNA" ;
VAL_ 55 TrqCtrlModeRq 0 "NONE" 1 "TRQ_INC_Fast" 2 "TRQ_DEC_Fast" 7 "SNA" ;
VAL_ 808 TGW_GrpTyp_IC 0 "NO_TEXT" 63 "SNA" ;
VAL_ 662 STFASysEnableFault 0 "Absent" 1 "Present" ;
VAL_ 662 TPM_HornChirp 0 "HORN_CHIRP_OFF" 1 "SINGLE_HORN_CHIRP" 2 "MULTIPLE_HORN_CHIRP" 3 "SNA" ;
VAL_ 662 TPM_IndLmp_On_Rq 0 "IND_LMP_OFF" 1 "IND_LMP_ON" 2 "IND_LMP_FLASH" 3 "SNA" ;
VAL_ 662 TPM_Sys_Stat 0 "NON_LOCALIZED" 1 "PERF_LOCALIZATION" 2 "LOCALIZATION_CMPLT" 3 "TPM_NA" 7 "SNA" ;
VAL_ 662 TireFL 0 "NORMAL" 1 "LOW" 2 "HIGH" 3 "SNA" ;
VAL_ 662 TireFR 0 "NORMAL" 1 "LOW" 2 "HIGH" 3 "SNA" ;
VAL_ 662 TirePressFL 255 "SNA" ;
VAL_ 662 TirePressFR 255 "SNA" ;
VAL_ 662 TirePressRL 255 "SNA" ;
VAL_ 662 TirePressRR 255 "SNA" ;
VAL_ 662 TirePressSpr 255 "SNA" ;
VAL_ 662 TireRL 0 "NORMAL" 1 "LOW" 2 "HIGH" 3 "SNA" ;
VAL_ 662 TireRR 0 "NORMAL" 1 "LOW" 2 "HIGH" 3 "SNA" ;
VAL_ 662 TireSpr 0 "NORMAL" 1 "LOW" 2 "HIGH" 3 "SNA" ;
VAL_ 526 CodeCheckSts 0 "No_Code" 1 "CodeCheck_OK" 2 "CodeCheck_Fault" ;
VAL_ 526 TxpID 0 "Transponder_Not_Authenticated" 1 "Transponder_1_Authenticated" 2 "Transponder_2_Authenticated" 3 "Transponder_3_Authenticated" 4 "Transponder_4_Authenticated" 5 "Transponder_5_Authenticated" 6 "Transponder_6_Authenticated" 7 "Transponder_7_Authenticated" 8 "Transponder_8_Authenticated" 9 "Transponder_9_Authenticated" 10 "Transponder_10_Authenticated" 11 "Transponder_11_Authenticated" 12 "Transponder_12_Authenticated" 13 "Transponder_13_Authenticated" 14 "Transponder_14_Authenticated" 15 "Transponder_15_Authenticated" ;
VAL_ 527 FrameNumber 0 "Frame_1" 1 "Frame_2" 2 "Frame_3" 3 "Frame_4" 4 "Frame_5" 5 "Frame_6" 6 "Frame_7" 7 "Frame_8" 8 "Frame_9" 9 "Frame_10" 10 "Frame_11" 11 "Frame_12" 12 "Frame_13" 13 "Frame_14" 14 "Frame_15" 15 "Frame_16" ;
VAL_ 527 TotalFrameNumber 0 "One_Frame" 1 "Two_Frames" 2 "Three_Frames" 3 "Four_Frames" 4 "Five_Frames" 5 "Six_Frames" 6 "Seven_Frames" 7 "Eight_Frame" 8 "Nine_Frames" 9 "Ten_Frames" 10 "Eleven_Frames" 11 "Twelve_Frames" 12 "Thirteen_Frames" 13 "Fourteen_Frames" 14 "Fifteen_Frames" 15 "Sixteen_Frames" ;
VAL_ 133 Gr 0 "N" 1 "D1" 2 "D2" 3 "D3" 4 "D4" 5 "D5" 6 "D6" 7 "D7" 8 "D8" 9 "D2P" 10 "D9" 11 "R" 12 "R2" 13 "P" 14 "KRAFTFREI" 15 "SNA" ;
VAL_ 133 Gr_Target 0 "N" 1 "D1" 2 "D2" 3 "D3" 4 "D4" 5 "D5" 6 "D6" 7 "D7" 8 "D8" 9 "D2P" 10 "D9" 11 "R" 12 "R2" 13 "P" 14 "ABBRUCH" 15 "SNA" ;
VAL_ 133 N_Turb 65535 "SNA" ;
VAL_ 133 OUTPUT_SPEED 65535 "SNA" ;
VAL_ 133 OutputSpdPolarity 0 "DND" 1 "DF" 2 "DB" 3 "SNA" ;
VAL_ 147 PRNDL_Blink 0 "NONE" 1 "P" 2 "R" 3 "N" 4 "D" 5 "L" 6 "S" 7 "M_TIP" ;
VAL_ 147 PRNDL_DISP 32 "BLANK" 49 "ONE" 50 "TWO" 51 "THREE" 52 "FOUR" 53 "FIVE" 54 "SIX" 55 "SEVEN" 56 "EIGHT" 57 "NINE" 65 "A" 68 "D" 70 "F" 76 "L" 77 "M" 78 "N" 80 "P" 82 "R" 83 "S" 128 "DS" 130 "D2" 131 "D3" 132 "D4" 133 "D5" 135 "SNOW" 254 "NOT_N" 255 "SNA" ;
VAL_ 147 PRND_STAT 0 "LVR_P" 1 "LVR_R" 2 "LVR_N" 4 "LVR_D" 5 "NOT_R" 7 "SNA" ;
VAL_ 147 PaddlesModeSts 0 "NONE" 1 "DIS" 2 "EN" 3 "SNA" ;
VAL_ 147 SHFT_PROG 1 "LOW" 2 "SSC" 3 "HDC" 4 "TRACK" 5 "VALET" 7 "SNOW" 11 "MUD" 12 "SAND" 16 "SKIP_SHFT" 24 "UPSHIFT_IND_RQ" 32 "BLANK" 64 "E_MODE" 65 "A" 77 "M" 83 "S" 87 "W" 249 "TX_RACE" 250 "Sport_Plus" 251 "TX_SPORT" 252 "TX_NORM" 253 "OD_OFF" 254 "TX_TOW" 255 "SNA" ;
VAL_ 293 FAN_RQ 15 "SNA" ;
VAL_ 293 TRNS_StpSt_FLT 1 "SNA" ;
VAL_ 293 TX_FAULT 0 "OK" 1 "TPF" 3 "SNA" ;
VAL_ 293 TX_TEMP 255 "SNA" ;
VAL_ 293 TX_WARN 0 "None" 1 "WARN_1" 2 "WARN_2" 3 "WARN_3" 4 "WARN_4" 5 "WARN_5" 6 "WARN_6" 7 "WARN_7" 8 "WARN_8" 9 "WARN_9" 10 "WARN_10" 11 "WARN_11" 12 "WARN_12" 13 "WARN_13" 14 "WARN_14" 15 "SNA" ;
VAL_ 698 UConnReq 0 "NO_BASIC_REQUEST" 1 "LOCK_REQUEST" 2 "RELOCK_REQUEST" 3 "DRIVER_UNLOCK_REQUEST" 4 "ALL_UNLOCK_REQUEST" 5 "TRUNK_PLG_TOGGLE_REQUEST" 6 "LEFT_SLIDER_TOGGLE_REQUEST" 7 "RIGHT_SLIDER_TOGGLE_REQUEST" 8 "FLIPPER_GLASS_REQUEST" 9 "REMOTE_START_ON" 10 "REMOTE_START_OFF" 11 "GLOBAL_WINDOW_DOWN_REQUEST" 12 "OPEN_CONVERTIBLE_TOP" 13 "CLOSE_CONVERTIBLE_TOP" 14 "PANIC_TOGGLE_REQUEST" 15 "DRIVER_TOGGLE_REQUEST" 16 "PASSENGER_TOGGLE_REQUEST" 17 "ExtLightReq" 18 "AirSuspReq" 19 "AirSuspCancel" 20 "GLBL_WIN_UP_RQ" 21 "CAR_FINDER_REQUEST" 22 "TRUNK_PLG_BTN_PRESSED" 23 "TRUNK_PLG_STOP_REQUEST" 24 "TRUNK_PLG_OPEN_REQUEST" 25 "TRUNK_PLG_CLOSE_REQUEST" 26 "VTA_RQ" 27 "RAP_UNLOCK_REQUEST" 28 "ABORT_CRANKING_ON_REQUEST" 29 "ABORT_CRANKING_OFF_REQUEST" 30 "Remote_Headlights" 31 "SNA" ;
VAL_ 698 UConnReqAuthCode 65535 "SNA" ;
VAL_ 698 UConnReqFOBNum 0 "FOB_DEFAULT" 1 "FOB_1" 2 "FOB_2" 3 "FOB_3" 4 "FOB_4" 5 "FOB_5" 6 "FOB_6" 7 "FOB_7" 8 "FOB_8" 15 "SNA" ;
VAL_ 992 VIN_MSG 0 "VIN_LO" 1 "VIN_MID" 2 "VIN_HI" 3 "SNA" ;
VAL_ 1000 VC_BODY_STYLE 0 "BODY_NONE" 1 "BODY_4DS" 2 "BODY_2DS" 3 "BODY_CONV" 4 "BODY_WAGON" 5 "BODY_4DH" 6 "BODY_2DP" 7 "BODY_4DP" 8 "BODY_4DMP" 15 "BODY_SNA" ;
VAL_ 1000 VC_COUNTRY 0 "ROW" 2 "USA" 3 "EU" 4 "CND" 5 "GB" 6 "JPN" 7 "GER" 8 "SWISS" 9 "MLY" 10 "AUS" 11 "IND" 12 "GULF" 13 "VEN" 14 "MEX" 15 "BRZ" 16 "CHINA" 17 "EGYPT" 20 "S_KOR" 21 "ECE" 31 "COUNTRY_SNA" ;
VAL_ 1000 VC_LHD_RHD 0 "NA" 1 "LHD" 2 "RHD" 3 "SNA" ;
VAL_ 1000 VC_MAX_VEH_SPD 255 "SNA" ;
VAL_ 1000 VC_MODEL_YEAR 63 "SNA" ;
VAL_ 1000 VC_PTS_Config 0 "REAR" 1 "FRT_REAR" 3 "SEMI" ;
VAL_ 1000 VC_PTS_DispTyp 0 "HEAD_DISP" 1 "CCN_DISP" 2 "AUDIO_DISP" 7 "SNA" ;
VAL_ 1000 VC_ShftrTyp 0 "TYPE_NA" 1 "TYPE_ERS4" 2 "TYPE_AS4" 3 "TYPE_ERS5" 4 "TYPE_AS5" 5 "TYPE_RS5M" 6 "TYPE_RS5S" 7 "TYPE_RS5L" 8 "TYPE_ERS4ESW" 9 "TYPE_MS7D" 10 "TYPE_MS7M156" 11 "TYPE_RS4" 12 "TYPE_MS7S" 13 "TYPE_MS7" 14 "TYPE_PS5" 15 "SNA" ;
VAL_ 1000 VC_SpecialPKG 0 "NONE" 255 "SNA" ;
VAL_ 1000 VC_VEH_LINE 0 "VEH_NONE" 1 "VEH_WK" 2 "VEH_LX" 22 "VEH_JC" 29 "VEH_DS" 31 "VEH_D2" 32 "VEH_DD" 33 "VEH_DP" 34 "VEH_DJ" 35 "VEH_WD" 39 "VEH_DX" 41 "VEH_LD" 42 "VEH_M156" 43 "VEH_ZD" 44 "VEH_LA" 45 "VEH_RU" 46 "VEH_M161" 47 "VEH_WS" 48 "VEH_DF" 49 "VEH_JL" 50 "VEH_M157" 51 "VEH_RA" 52 "VEH_WL" 53 "VEH_DT" 54 "VEH_DU" 55 "VEH_JT" 80 "VEH_PF" 81 "VEH_KL" 82 "VEH_UF" 83 "VEH_UT" 84 "VEH_M145" 85 "VEH_M145BD" 86 "VEH_K8" 87 "VEH_FF" 255 "SNA" ;
VAL_ 1000 VC_VehCfg1_Stat 0 "NA" 1 "PROGAMMED" 2 "REQUEST_DATA" 3 "SNA" ;
VAL_ 1000 VC_XWD 0 "2FT" 1 "2RR" 2 "ALLWD" 3 "4WD" ;
VAL_ 1001 VC_LgtLdPressFtTr 255 "SNA" ;
VAL_ 1001 VC_LgtLdPressRrTr 255 "SNA" ;
VAL_ 1001 VC_MaseratiMd 0 "NORMAL" 1 "GTS" 2 "RACE" 3 "SNA" ;
VAL_ 1001 VC_MaxLdPressFtTr 255 "SNA" ;
VAL_ 1001 VC_MaxLdPressRrTr 255 "SNA" ;
VAL_ 1001 VC_PwrIvtrTyp 0 "NoPwrIvtr" 1 "MtrySw" 2 "LchSw" ;
VAL_ 1001 VC_ShftInd_Prsnt 0 "NONE" 1 "GSI" 2 "PSI" 3 "PGSI" ;
VAL_ 1001 VC_SpecialPKG_IC 0 "NONE" 1 "PKG_70JP" 2 "PKG_300S" 3 "PKG_BEATS" 4 "PKG_SUPERBEE" 5 "MOPAR" 6 "Hellcat" 7 "Shaker" 8 "Scat" 9 "ADR" 10 "Scat_Drag" 11 "High_Output" 12 "Hellcat_HO" 16 "LARAMIE" 17 "BIGHORN" 18 "LONGHORN" 19 "LONESTAR" 20 "LIMITED" 21 "MOSSY_OAK" 22 "ORT" 23 "POWERWAGON" 24 "HD_DX" 25 "SPORT" 26 "PWGN_Laramie" 27 "RAM_1500" 28 "PWGN_GOODYEAR" 29 "LONGHORN_BLACK" 30 "LONGHORN_BROWN" 31 "RAM_2500" 32 "RAM_3500" 33 "RAM_4500" 34 "RAM_5500" 35 "RAM_TRX21" 36 "VOYAGER" 37 "PACIFICA" 38 "GRAND_CARAVAN" 39 "50th_Anniversary" 100 "WRANGLER_SPORT" 101 "WRANGLER_SAHARA" 102 "WRANGLER_RUBICON" 103 "JEEP_SPORT" 104 "JEEP_SPORT_X" 105 "JEEP_RUBICON" 106 "JEEP_PRO_FIGHTER" 150 "TRAILHAWK_SUPERCHARGED" 246 "DODGE_100" 247 "VARVATOS" 255 "SNA" ;
VAL_ 1001 VC_VehCfg2_Stat 0 "NA" 1 "PROGAMMED" 2 "REQUEST_DATA" 3 "SNA" ;
